VERSION ""

NS_ :

BS_:

BU_: HIB SaGE CBC DASM DIAGNOST EBCM ECM EPSB ESC ESL HALF HCP IC OCM ORC PTS RF_HUB SCCM

BO_ 996 NET_CFG_PT: 8 HIB
 SG_ NET_CFG_STAT_PT : 0|2@1+ (1,0) [0|0] ""  DASM,EBCM,ECM,EPSB,ESC,ESL,HALF,HCP,IC,OCM,ORC,PTS,RF_HUB,SCCM
 SG_ NetCfg_ACC : 2|1@1+ (1,0) [0|0] ""  RF_HUB
 SG_ NetCfg_ADCM : 3|1@1+ (1,0) [0|0] ""  RF_HUB
 SG_ NetCfg_AFLS : 28|1@1+ (1,0) [0|0] ""  RF_HUB
 SG_ NetCfg_AHLM : 4|1@1+ (1,0) [0|0] ""  RF_HUB
 SG_ NetCfg_ANC : 39|1@1+ (1,0) [0|0] ""  RF_HUB
 SG_ NetCfg_ASCM : 6|1@1+ (1,0) [0|0] ""  DASM,HALF,RF_HUB
 SG_ NetCfg_BSMO : 36|1@1+ (1,0) [0|0] ""  EPSB,IC,RF_HUB
 SG_ NetCfg_CBC_PT : 7|1@1+ (1,0) [0|0] ""  EPSB,RF_HUB
 SG_ NetCfg_DASM : 16|1@1+ (1,0) [0|0] ""  DASM,ECM,ESC,IC,RF_HUB,SCCM
 SG_ NetCfg_DTCM : 8|1@1+ (1,0) [0|0] ""  DASM,RF_HUB
 SG_ NetCfg_ECM : 9|1@1+ (1,0) [0|0] ""  DASM,EPSB,RF_HUB
 SG_ NetCfg_ELSD : 24|1@1+ (1,0) [0|0] ""  RF_HUB
 SG_ NetCfg_EPB : 13|1@1+ (1,0) [0|0] ""  RF_HUB
 SG_ NetCfg_EPPM : 18|1@1+ (1,0) [0|0] ""  RF_HUB
 SG_ NetCfg_EPS : 10|1@1+ (1,0) [0|0] ""  HALF,IC,ORC,RF_HUB
 SG_ NetCfg_ESC : 12|1@1+ (1,0) [0|0] ""  EPSB,RF_HUB
 SG_ NetCfg_ESL : 37|1@1+ (1,0) [0|0] ""  RF_HUB
 SG_ NetCfg_ESM : 11|1@1+ (1,0) [0|0] ""  RF_HUB
 SG_ NetCfg_FDCM : 17|1@1+ (1,0) [0|0] ""  RF_HUB
 SG_ NetCfg_HCP : 38|1@1+ (1,0) [0|0] ""  EPSB,PTS,RF_HUB
 SG_ NetCfg_HaLF : 31|1@1+ (1,0) [0|0] ""  DASM,HALF,RF_HUB
 SG_ NetCfg_IC : 15|1@1+ (1,0) [0|0] ""  DASM,EPSB,RF_HUB
 SG_ NetCfg_ITBM : 29|1@1+ (1,0) [0|0] ""  RF_HUB
 SG_ NetCfg_OCM : 30|1@1+ (1,0) [0|0] ""  ORC,RF_HUB
 SG_ NetCfg_ORC : 19|1@1+ (1,0) [0|0] ""  DASM,RF_HUB
 SG_ NetCfg_PASS_PT : 27|1@1+ (1,0) [0|0] ""  RF_HUB
 SG_ NetCfg_PTS : 20|1@1+ (1,0) [0|0] ""  EPSB,ESC,IC,RF_HUB
 SG_ NetCfg_RF_HUB : 14|1@1+ (1,0) [0|0] ""  HCP,IC,RF_HUB
 SG_ NetCfg_RHSC2 : 44|1@1+ (1,0) [0|0] ""  EPSB,HCP,RF_HUB
 SG_ NetCfg_SCCM : 23|1@1+ (1,0) [0|0] ""  DASM,EPSB,RF_HUB
 SG_ NetCfg_TCM : 25|1@1+ (1,0) [0|0] ""  ORC,RF_HUB
 SG_ NetCfg_TPM : 26|1@1+ (1,0) [0|0] ""  IC,RF_HUB
 SG_ NetCfg_VSIM_C : 5|1@1+ (1,0) [0|0] ""  RF_HUB

BO_ 1025 NM_CBC: 8 CBC
 SG_ Awake_Diag_Actv m15 : 33|1@1+ (1,0) [0|0] ""  CBC,EBCM,EPSB,ESC,ESL,HCP,IC,RF_HUB,SCCM
 SG_ Awake_NwSt m15 : 32|1@1+ (1,0) [0|0] ""  CBC,EBCM,EPSB,ESC,ESL,HCP,IC,RF_HUB,SCCM
 SG_ NM_Mode : 0|8@1+ (1,0) [0|0] ""  CBC,EBCM,EPSB,ESC,ESL,HCP,IC,RF_HUB,SCCM
 SG_ NM_Sleep_Ack : 22|1@1+ (1,0) [0|0] ""  CBC,EBCM,EPSB,ESC,ESL,HCP,IC,RF_HUB,SCCM
 SG_ NM_Sleep_Ind : 23|1@1+ (1,0) [0|0] ""  CBC,EBCM,EPSB,ESC,ESL,HCP,IC,RF_HUB,SCCM
 SG_ NM_Successor : 8|8@1+ (1,0) [0|63] ""  CBC,EBCM,EPSB,ESC,ESL,HCP,IC,RF_HUB,SCCM
 SG_ NM_Ud_Launch : 16|6@1+ (1,0) [0|0] ""  CBC,EBCM,EPSB,ESC,ESL,HCP,IC,RF_HUB,SCCM
 SG_ NM_Ud_Srv M : 24|8@1+ (1,0) [0|0] ""  CBC,EBCM,EPSB,ESC,ESL,HCP,IC,RF_HUB,SCCM
 SG_ Nw_Id : 56|8@1+ (1,0) [0|0] ""  CBC,EBCM,EPSB,ESC,ESL,HCP,IC,RF_HUB,SCCM
 SG_ WakeupCnt m2 : 40|8@1+ (1,0) [0|254] ""  CBC,EBCM,EPSB,ESC,ESL,HCP,IC,RF_HUB,SCCM
 SG_ WakeupRsn_CBC m2 : 32|8@1+ (1,0) [0|0] ""  CBC,EBCM,EPSB,ESC,ESL,HCP,IC,RF_HUB,SCCM

BO_ 1083 NM_EBCM: 8 EBCM
 SG_ Awake_Diag_Actv m15 : 33|1@1+ (1,0) [0|0] ""  CBC,EBCM,EPSB,ESC,ESL,HCP,IC,RF_HUB,SCCM
 SG_ Awake_NwSt m15 : 32|1@1+ (1,0) [0|0] ""  CBC,EBCM,EPSB,ESC,ESL,HCP,IC,RF_HUB,SCCM
 SG_ NM_Mode : 0|8@1+ (1,0) [0|0] ""  CBC,EBCM,EPSB,ESC,ESL,HCP,IC,RF_HUB,SCCM
 SG_ NM_Sleep_Ack : 22|1@1+ (1,0) [0|0] ""  CBC,EBCM,EPSB,ESC,ESL,HCP,IC,RF_HUB,SCCM
 SG_ NM_Sleep_Ind : 23|1@1+ (1,0) [0|0] ""  CBC,EBCM,EPSB,ESC,ESL,HCP,IC,RF_HUB,SCCM
 SG_ NM_Successor : 8|8@1+ (1,0) [0|63] ""  CBC,EBCM,EPSB,ESC,ESL,HCP,IC,RF_HUB,SCCM
 SG_ NM_Ud_Launch : 16|6@1+ (1,0) [0|0] ""  CBC,EBCM,EPSB,ESC,ESL,HCP,IC,RF_HUB,SCCM
 SG_ NM_Ud_Srv M : 24|8@1+ (1,0) [0|0] ""  CBC,EBCM,EPSB,ESC,ESL,HCP,IC,RF_HUB,SCCM
 SG_ Nw_Id : 56|8@1+ (1,0) [0|0] ""  CBC,EBCM,EPSB,ESC,ESL,HCP,IC,RF_HUB,SCCM
 SG_ WakeupCnt m2 : 40|8@1+ (1,0) [0|254] ""  CBC,EBCM,EPSB,ESC,ESL,HCP,IC,RF_HUB,SCCM
 SG_ WakeupRsn_EBCM m2 : 32|8@1+ (1,0) [0|0] ""  CBC,EBCM,EPSB,ESC,ESL,HCP,IC,RF_HUB,SCCM

BO_ 1050 NM_EPS: 8 EPSB
 SG_ Awake_Diag_Actv m15 : 33|1@1+ (1,0) [0|0] ""  CBC,EBCM,EPSB,ESC,ESL,HCP,IC,RF_HUB,SCCM
 SG_ Awake_EngRPM_high m15 : 36|1@1+ (1,0) [0|0] ""  CBC,EBCM,EPSB,ESC,ESL,HCP,IC,RF_HUB,SCCM
 SG_ Awake_IgnHigh m15 : 37|1@1+ (1,0) [0|0] ""  CBC,EBCM,EPSB,ESC,ESL,HCP,IC,RF_HUB,SCCM
 SG_ Awake_NwSt m15 : 32|1@1+ (1,0) [0|0] ""  CBC,EBCM,EPSB,ESC,ESL,HCP,IC,RF_HUB,SCCM
 SG_ Awake_Rampout m15 : 34|1@1+ (1,0) [0|0] ""  CBC,EBCM,EPSB,ESC,ESL,HCP,IC,RF_HUB,SCCM
 SG_ Awake_VSS_high m15 : 35|1@1+ (1,0) [0|0] ""  CBC,EBCM,EPSB,ESC,ESL,HCP,IC,RF_HUB,SCCM
 SG_ NM_Mode : 0|8@1+ (1,0) [0|0] ""  CBC,EBCM,EPSB,ESC,ESL,HCP,IC,RF_HUB,SCCM
 SG_ NM_Sleep_Ack : 22|1@1+ (1,0) [0|0] ""  CBC,EBCM,EPSB,ESC,ESL,HCP,IC,RF_HUB,SCCM
 SG_ NM_Sleep_Ind : 23|1@1+ (1,0) [0|0] ""  CBC,EBCM,EPSB,ESC,ESL,HCP,IC,RF_HUB,SCCM
 SG_ NM_Successor : 8|8@1+ (1,0) [0|63] ""  CBC,EBCM,EPSB,ESC,ESL,HCP,IC,RF_HUB,SCCM
 SG_ NM_Ud_Launch : 16|6@1+ (1,0) [0|0] ""  CBC,EBCM,EPSB,ESC,ESL,HCP,IC,RF_HUB,SCCM
 SG_ NM_Ud_Srv M : 24|8@1+ (1,0) [0|0] ""  CBC,EBCM,EPSB,ESC,ESL,HCP,IC,RF_HUB,SCCM
 SG_ Nw_Id : 56|8@1+ (1,0) [0|0] ""  CBC,EBCM,EPSB,ESC,ESL,HCP,IC,RF_HUB,SCCM
 SG_ WakeupCnt m2 : 40|8@1+ (1,0) [0|254] ""  CBC,EBCM,EPSB,ESC,ESL,HCP,IC,RF_HUB,SCCM
 SG_ WakeupRsn_EPS m2 : 32|8@1+ (1,0) [0|0] ""  CBC,EBCM,EPSB,ESC,ESL,HCP,IC,RF_HUB,SCCM

BO_ 1031 NM_ESC: 8 ESC
 SG_ Awake_Brake_Pedal_Pressed m15 : 34|1@1+ (1,0) [0|0] ""  CBC,EBCM,EPSB,ESC,ESL,HCP,IC,RF_HUB,SCCM
 SG_ Awake_Diag_Actv m15 : 33|1@1+ (1,0) [0|0] ""  CBC,EBCM,EPSB,ESC,ESL,HCP,IC,RF_HUB,SCCM
 SG_ Awake_EPB_Switch_Wakeup m15 : 36|1@1+ (1,0) [0|0] ""  CBC,EBCM,EPSB,ESC,ESL,HCP,IC,RF_HUB,SCCM
 SG_ Awake_Hardwire_Ignition m15 : 37|1@1+ (1,0) [0|0] ""  CBC,EBCM,EPSB,ESC,ESL,HCP,IC,RF_HUB,SCCM
 SG_ Awake_NwSt m15 : 32|1@1+ (1,0) [0|0] ""  CBC,EBCM,EPSB,ESC,ESL,HCP,IC,RF_HUB,SCCM
 SG_ Awake_Vehicle_Speed m15 : 35|1@1+ (1,0) [0|0] ""  CBC,EBCM,EPSB,ESC,ESL,HCP,IC,RF_HUB,SCCM
 SG_ NM_Mode : 0|8@1+ (1,0) [0|0] ""  CBC,EBCM,EPSB,ESC,ESL,HCP,IC,RF_HUB,SCCM
 SG_ NM_Sleep_Ack : 22|1@1+ (1,0) [0|0] ""  CBC,EBCM,EPSB,ESC,ESL,HCP,IC,RF_HUB,SCCM
 SG_ NM_Sleep_Ind : 23|1@1+ (1,0) [0|0] ""  CBC,EBCM,EPSB,ESC,ESL,HCP,IC,RF_HUB,SCCM
 SG_ NM_Successor : 8|8@1+ (1,0) [0|63] ""  CBC,EBCM,EPSB,ESC,ESL,HCP,IC,RF_HUB,SCCM
 SG_ NM_Ud_Launch : 16|6@1+ (1,0) [0|0] ""  CBC,EBCM,EPSB,ESC,ESL,HCP,IC,RF_HUB,SCCM
 SG_ NM_Ud_Srv M : 24|8@1+ (1,0) [0|0] ""  CBC,EBCM,EPSB,ESC,ESL,HCP,IC,RF_HUB,SCCM
 SG_ Nw_Id : 56|8@1+ (1,0) [0|0] ""  CBC,EBCM,EPSB,ESC,ESL,HCP,IC,RF_HUB,SCCM
 SG_ WakeupCnt m2 : 40|8@1+ (1,0) [0|254] ""  CBC,EBCM,EPSB,ESC,ESL,HCP,IC,RF_HUB,SCCM
 SG_ WakeupRsn_ESC m2 : 32|8@1+ (1,0) [0|0] ""  CBC,EBCM,EPSB,ESC,ESL,HCP,IC,RF_HUB,SCCM

BO_ 1032 NM_ESL: 8 ESL
 SG_ Awake_Diag_Actv m15 : 33|1@1+ (1,0) [0|0] ""  CBC,EBCM,EPSB,ESC,ESL,HCP,IC,RF_HUB,SCCM
 SG_ Awake_Ign_RunStart m15 : 34|1@1+ (1,0) [0|0] ""  CBC,EBCM,EPSB,ESC,ESL,HCP,IC,RF_HUB,SCCM
 SG_ Awake_Lock_Unlock m15 : 35|1@1+ (1,0) [0|0] ""  CBC,EBCM,EPSB,ESC,ESL,HCP,IC,RF_HUB,SCCM
 SG_ Awake_NwSt m15 : 32|1@1+ (1,0) [0|0] ""  CBC,EBCM,EPSB,ESC,ESL,HCP,IC,RF_HUB,SCCM
 SG_ NM_Mode : 0|8@1+ (1,0) [0|0] ""  CBC,EBCM,EPSB,ESC,ESL,HCP,IC,RF_HUB,SCCM
 SG_ NM_Sleep_Ack : 22|1@1+ (1,0) [0|0] ""  CBC,EBCM,EPSB,ESC,ESL,HCP,IC,RF_HUB,SCCM
 SG_ NM_Sleep_Ind : 23|1@1+ (1,0) [0|0] ""  CBC,EBCM,EPSB,ESC,ESL,HCP,IC,RF_HUB,SCCM
 SG_ NM_Successor : 8|8@1+ (1,0) [0|63] ""  CBC,EBCM,EPSB,ESC,ESL,HCP,IC,RF_HUB,SCCM
 SG_ NM_Ud_Launch : 16|6@1+ (1,0) [0|0] ""  CBC,EBCM,EPSB,ESC,ESL,HCP,IC,RF_HUB,SCCM
 SG_ NM_Ud_Srv M : 24|8@1+ (1,0) [0|0] ""  CBC,EBCM,EPSB,ESC,ESL,HCP,IC,RF_HUB,SCCM
 SG_ Nw_Id : 56|8@1+ (1,0) [0|0] ""  CBC,EBCM,EPSB,ESC,ESL,HCP,IC,RF_HUB,SCCM
 SG_ WakeupCnt m2 : 40|8@1+ (1,0) [0|254] ""  CBC,EBCM,EPSB,ESC,ESL,HCP,IC,RF_HUB,SCCM
 SG_ WakeupRsn_ESL m2 : 32|8@1+ (1,0) [0|0] ""  CBC,EBCM,EPSB,ESC,ESL,HCP,IC,RF_HUB,SCCM

BO_ 1082 NM_HCP: 8 HCP
 SG_ Awake_Chg_ST m15 : 35|1@1+ (1,0) [0|0] ""  CBC,EBCM,EPSB,ESC,ESL,HCP,IC,RF_HUB,SCCM
 SG_ Awake_Diag_Actv m15 : 33|1@1+ (1,0) [0|0] ""  CBC,EBCM,EPSB,ESC,ESL,HCP,IC,RF_HUB,SCCM
 SG_ Awake_NwSt m15 : 32|1@1+ (1,0) [0|0] ""  CBC,EBCM,EPSB,ESC,ESL,HCP,IC,RF_HUB,SCCM
 SG_ Awake_OBCM_WU m15 : 34|1@1+ (1,0) [0|0] ""  CBC,EBCM,EPSB,ESC,ESL,HCP,IC,RF_HUB,SCCM
 SG_ NM_Mode : 0|8@1+ (1,0) [0|0] ""  CBC,EBCM,EPSB,ESC,ESL,HCP,IC,RF_HUB,SCCM
 SG_ NM_Sleep_Ack : 22|1@1+ (1,0) [0|0] ""  CBC,EBCM,EPSB,ESC,ESL,HCP,IC,RF_HUB,SCCM
 SG_ NM_Sleep_Ind : 23|1@1+ (1,0) [0|0] ""  CBC,EBCM,EPSB,ESC,ESL,HCP,IC,RF_HUB,SCCM
 SG_ NM_Successor : 8|8@1+ (1,0) [0|63] ""  CBC,EBCM,EPSB,ESC,ESL,HCP,IC,RF_HUB,SCCM
 SG_ NM_Ud_Launch : 16|6@1+ (1,0) [0|0] ""  CBC,EBCM,EPSB,ESC,ESL,HCP,IC,RF_HUB,SCCM
 SG_ NM_Ud_Srv M : 24|8@1+ (1,0) [0|0] ""  CBC,EBCM,EPSB,ESC,ESL,HCP,IC,RF_HUB,SCCM
 SG_ Nw_Id : 56|8@1+ (1,0) [0|0] ""  CBC,EBCM,EPSB,ESC,ESL,HCP,IC,RF_HUB,SCCM
 SG_ WakeupCnt m2 : 40|8@1+ (1,0) [0|254] ""  CBC,EBCM,EPSB,ESC,ESL,HCP,IC,RF_HUB,SCCM
 SG_ WakeupRsn_HCP m2 : 32|8@1+ (1,0) [0|0] ""  CBC,EBCM,EPSB,ESC,ESL,HCP,IC,RF_HUB,SCCM

BO_ 1026 NM_IC: 8 IC
 SG_ Awake_Diag_Actv m15 : 33|1@1+ (1,0) [0|0] ""  CBC,EBCM,EPSB,ESC,ESL,HCP,IC,RF_HUB,SCCM
 SG_ Awake_NwSt m15 : 32|1@1+ (1,0) [0|0] ""  CBC,EBCM,EPSB,ESC,ESL,HCP,IC,RF_HUB,SCCM
 SG_ NM_Mode : 0|8@1+ (1,0) [0|0] ""  CBC,EBCM,EPSB,ESC,ESL,HCP,IC,RF_HUB,SCCM
 SG_ NM_Sleep_Ack : 22|1@1+ (1,0) [0|0] ""  CBC,EBCM,EPSB,ESC,ESL,HCP,IC,RF_HUB,SCCM
 SG_ NM_Sleep_Ind : 23|1@1+ (1,0) [0|0] ""  CBC,EBCM,EPSB,ESC,ESL,HCP,IC,RF_HUB,SCCM
 SG_ NM_Successor : 8|8@1+ (1,0) [0|63] ""  CBC,EBCM,EPSB,ESC,ESL,HCP,IC,RF_HUB,SCCM
 SG_ NM_Ud_Launch : 16|6@1+ (1,0) [0|0] ""  CBC,EBCM,EPSB,ESC,ESL,HCP,IC,RF_HUB,SCCM
 SG_ NM_Ud_Srv M : 24|8@1+ (1,0) [0|0] ""  CBC,EBCM,EPSB,ESC,ESL,HCP,IC,RF_HUB,SCCM
 SG_ Nw_Id : 56|8@1+ (1,0) [0|0] ""  CBC,EBCM,EPSB,ESC,ESL,HCP,IC,RF_HUB,SCCM
 SG_ WakeupCnt m2 : 40|8@1+ (1,0) [0|254] ""  CBC,EBCM,EPSB,ESC,ESL,HCP,IC,RF_HUB,SCCM
 SG_ WakeupRsn_IC m2 : 32|8@1+ (1,0) [0|0] ""  CBC,EBCM,EPSB,ESC,ESL,HCP,IC,RF_HUB,SCCM

BO_ 1024 NM_RF_HUB: 8 RF_HUB
 SG_ Awake_Diag_Actv m15 : 33|1@1+ (1,0) [0|0] ""  CBC,EBCM,EPSB,ESC,ESL,HCP,IC,RF_HUB,SCCM
 SG_ Awake_NwSt m15 : 32|1@1+ (1,0) [0|0] ""  CBC,EBCM,EPSB,ESC,ESL,HCP,IC,RF_HUB,SCCM
 SG_ NM_Mode : 0|8@1+ (1,0) [0|0] ""  CBC,EBCM,EPSB,ESC,ESL,HCP,IC,RF_HUB,SCCM
 SG_ NM_Sleep_Ack : 22|1@1+ (1,0) [0|0] ""  CBC,EBCM,EPSB,ESC,ESL,HCP,IC,RF_HUB,SCCM
 SG_ NM_Sleep_Ind : 23|1@1+ (1,0) [0|0] ""  CBC,EBCM,EPSB,ESC,ESL,HCP,IC,RF_HUB,SCCM
 SG_ NM_Successor : 8|8@1+ (1,0) [0|63] ""  CBC,EBCM,EPSB,ESC,ESL,HCP,IC,RF_HUB,SCCM
 SG_ NM_Ud_Launch : 16|6@1+ (1,0) [0|0] ""  CBC,EBCM,EPSB,ESC,ESL,HCP,IC,RF_HUB,SCCM
 SG_ NM_Ud_Srv M : 24|8@1+ (1,0) [0|0] ""  CBC,EBCM,EPSB,ESC,ESL,HCP,IC,RF_HUB,SCCM
 SG_ Nw_Id : 56|8@1+ (1,0) [0|0] ""  CBC,EBCM,EPSB,ESC,ESL,HCP,IC,RF_HUB,SCCM
 SG_ WakeupCnt m2 : 40|8@1+ (1,0) [0|254] ""  CBC,EBCM,EPSB,ESC,ESL,HCP,IC,RF_HUB,SCCM
 SG_ WakeupRsn_RF_HUB m2 : 32|8@1+ (1,0) [0|0] ""  CBC,EBCM,EPSB,ESC,ESL,HCP,IC,RF_HUB,SCCM

BO_ 1059 NM_SCCM: 8 SCCM
 SG_ Awake_Diag_Actv m15 : 33|1@1+ (1,0) [0|0] ""  CBC,EBCM,EPSB,ESC,ESL,HCP,IC,RF_HUB,SCCM
 SG_ Awake_EEPROM m15 : 36|1@1+ (1,0) [0|0] ""  CBC,EBCM,EPSB,ESC,ESL,HCP,IC,RF_HUB,SCCM
 SG_ Awake_FTP_Psd m15 : 38|1@1+ (1,0) [0|0] ""  CBC,EBCM,EPSB,ESC,ESL,HCP,IC,RF_HUB,SCCM
 SG_ Awake_HrnSwt_Actv m15 : 39|1@1+ (1,0) [0|0] ""  CBC,EBCM,EPSB,ESC,ESL,HCP,IC,RF_HUB,SCCM
 SG_ Awake_Ignition_On m15 : 35|1@1+ (1,0) [0|0] ""  CBC,EBCM,EPSB,ESC,ESL,HCP,IC,RF_HUB,SCCM
 SG_ Awake_NwSt m15 : 32|1@1+ (1,0) [0|0] ""  CBC,EBCM,EPSB,ESC,ESL,HCP,IC,RF_HUB,SCCM
 SG_ Awake_StwSw_Actv m15 : 34|1@1+ (1,0) [0|0] ""  CBC,EBCM,EPSB,ESC,ESL,HCP,IC,RF_HUB,SCCM
 SG_ Awake_tilt_tel_Psd m15 : 37|1@1+ (1,0) [0|0] ""  CBC,EBCM,EPSB,ESC,ESL,HCP,IC,RF_HUB,SCCM
 SG_ NM_Mode : 0|8@1+ (1,0) [0|0] ""  CBC,EBCM,EPSB,ESC,ESL,HCP,IC,RF_HUB,SCCM
 SG_ NM_Sleep_Ack : 22|1@1+ (1,0) [0|0] ""  CBC,EBCM,EPSB,ESC,ESL,HCP,IC,RF_HUB,SCCM
 SG_ NM_Sleep_Ind : 23|1@1+ (1,0) [0|0] ""  CBC,EBCM,EPSB,ESC,ESL,HCP,IC,RF_HUB,SCCM
 SG_ NM_Successor : 8|8@1+ (1,0) [0|63] ""  CBC,EBCM,EPSB,ESC,ESL,HCP,IC,RF_HUB,SCCM
 SG_ NM_Ud_Launch : 16|6@1+ (1,0) [0|0] ""  CBC,EBCM,EPSB,ESC,ESL,HCP,IC,RF_HUB,SCCM
 SG_ NM_Ud_Srv M : 24|8@1+ (1,0) [0|0] ""  CBC,EBCM,EPSB,ESC,ESL,HCP,IC,RF_HUB,SCCM
 SG_ Nw_Id : 56|8@1+ (1,0) [0|0] ""  CBC,EBCM,EPSB,ESC,ESL,HCP,IC,RF_HUB,SCCM
 SG_ WakeupCnt m2 : 40|8@1+ (1,0) [0|254] ""  CBC,EBCM,EPSB,ESC,ESL,HCP,IC,RF_HUB,SCCM
 SG_ WakeupRsn_SCCM m2 : 32|8@1+ (1,0) [0|0] ""  CBC,EBCM,EPSB,ESC,ESL,HCP,IC,RF_HUB,SCCM

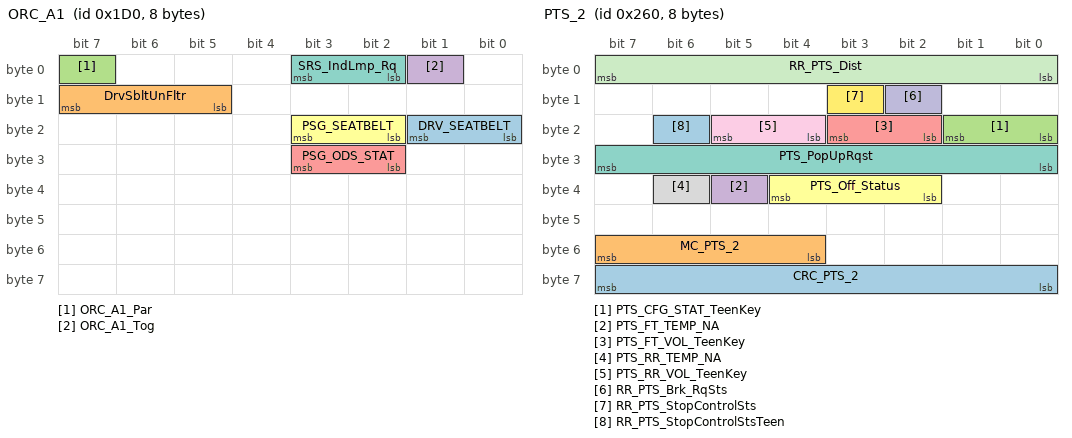
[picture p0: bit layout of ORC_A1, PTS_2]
BO_ 464 ORC_A1: 8 ORC
 SG_ DRV_SEATBELT : 16|2@1+ (1,0) [0|0] ""  DASM,ECM,ESC,HCP,IC
 SG_ DrvSbltUnFltr : 13|3@1+ (1,0) [0|0] ""  ECM,ESC
 SG_ ORC_A1_Par : 7|1@1+ (1,0) [0|0] ""  DASM
 SG_ ORC_A1_Tog : 1|1@1+ (1,0) [0|0] ""  DASM
 SG_ PSG_ODS_STAT : 26|2@1+ (1,0) [0|0] ""  IC
 SG_ PSG_SEATBELT : 18|2@1+ (1,0) [0|0] ""  IC
 SG_ SRS_IndLmp_Rq : 2|2@1+ (1,0) [0|0] ""  IC

BO_ 826 PTS_1: 8 PTS
 SG_ PTS_AlrFC : 40|4@1+ (1,0) [0|0] ""  CBC,IC
 SG_ PTS_AlrFL : 8|4@1+ (1,0) [0|0] ""  CBC,IC
 SG_ PTS_AlrFR : 16|4@1+ (1,0) [0|0] ""  CBC,IC
 SG_ PTS_AlrRC : 48|4@1+ (1,0) [0|0] ""  CBC,IC
 SG_ PTS_AlrRL : 24|4@1+ (1,0) [0|0] ""  CBC,IC
 SG_ PTS_AlrRR : 32|4@1+ (1,0) [0|0] ""  CBC,IC
 SG_ PTS_CFG_STAT : 1|2@1+ (1,0) [0|0] ""  CBC
 SG_ PTS_FT_NA : 3|1@1+ (1,0) [0|0] ""  IC
 SG_ PTS_FT_SRV : 58|1@1+ (1,0) [0|0] ""  IC
 SG_ PTS_GraphicFC : 46|2@1+ (1,0) [0|0] ""  IC
 SG_ PTS_GraphicFL : 14|2@1+ (1,0) [0|0] ""  IC
 SG_ PTS_GraphicFR : 22|2@1+ (1,0) [0|0] ""  IC
 SG_ PTS_GraphicRC : 54|2@1+ (1,0) [0|0] ""  IC
 SG_ PTS_GraphicRL : 30|2@1+ (1,0) [0|0] ""  IC
 SG_ PTS_GraphicRR : 38|2@1+ (1,0) [0|0] ""  IC
 SG_ PTS_RR_NA : 4|1@1+ (1,0) [0|0] ""  IC
 SG_ PTS_RR_SRV : 59|1@1+ (1,0) [0|0] ""  IC
 SG_ PTS_SRV_RQ : 5|1@1+ (1,0) [0|0] ""  IC
 SG_ PTS_STAT : 60|2@1+ (1,0) [0|0] ""  CBC

BO_ 608 PTS_2: 8 PTS
 SG_ CRC_PTS_2 : 56|8@1+ (1,0) [0|0] ""  ESC
 SG_ MC_PTS_2 : 52|4@1+ (1,0) [0|15] ""  ESC
 SG_ PTS_CFG_STAT_TeenKey : 16|2@1+ (1,0) [0|0] ""  CBC
 SG_ PTS_FT_TEMP_NA : 37|1@1+ (1,0) [0|0] ""  IC
 SG_ PTS_FT_VOL_TeenKey : 18|2@1+ (1,0) [0|0] ""  CBC
 SG_ PTS_Off_Status : 34|3@1+ (1,0) [0|0] ""  IC
 SG_ PTS_PopUpRqst : 24|8@1+ (1,0) [0|0] ""  IC
 SG_ PTS_RR_TEMP_NA : 38|1@1+ (1,0) [0|0] ""  IC
 SG_ PTS_RR_VOL_TeenKey : 20|2@1+ (1,0) [0|0] ""  CBC
 SG_ RR_PTS_Brk_RqSts : 10|1@1+ (1,0) [0|0] ""  ESC
 SG_ RR_PTS_Dist : 0|8@1+ (1,0) [0|254] "cm"  ESC
 SG_ RR_PTS_StopControlSts : 11|1@1+ (1,0) [0|0] ""  CBC,IC
 SG_ RR_PTS_StopControlStsTeen : 22|1@1+ (1,0) [0|0] ""  CBC,IC

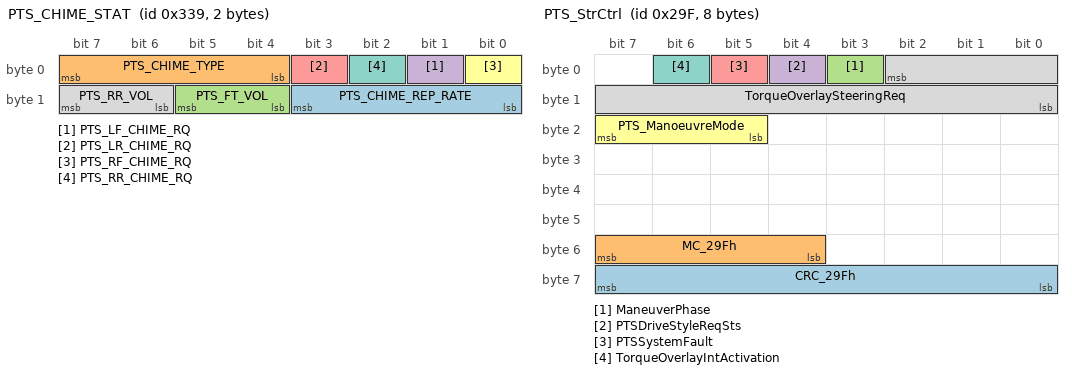
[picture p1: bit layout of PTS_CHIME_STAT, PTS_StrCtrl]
BO_ 825 PTS_CHIME_STAT: 2 PTS
 SG_ PTS_CHIME_REP_RATE : 8|4@1+ (1,0) [0|15] "Hz"  CBC
 SG_ PTS_CHIME_TYPE : 4|4@1+ (1,0) [0|0] ""  CBC
 SG_ PTS_FT_VOL : 12|2@1+ (1,0) [0|0] ""  CBC
 SG_ PTS_LF_CHIME_RQ : 1|1@1+ (1,0) [0|0] ""  CBC
 SG_ PTS_LR_CHIME_RQ : 3|1@1+ (1,0) [0|0] ""  CBC
 SG_ PTS_RF_CHIME_RQ : 0|1@1+ (1,0) [0|0] ""  CBC
 SG_ PTS_RR_CHIME_RQ : 2|1@1+ (1,0) [0|0] ""  CBC
 SG_ PTS_RR_VOL : 14|2@1+ (1,0) [0|0] ""  CBC

BO_ 671 PTS_StrCtrl: 8 PTS
 SG_ CRC_29Fh : 56|8@1+ (1,0) [0|0] ""  EPSB
 SG_ MC_29Fh : 52|4@1+ (1,0) [0|15] ""  EPSB
 SG_ ManeuverPhase : 3|1@1+ (1,0) [0|0] ""  EPSB
 SG_ PTSDriveStyleReqSts : 4|1@1+ (1,0) [0|0] ""  EPSB
 SG_ PTSSystemFault : 5|1@1+ (1,0) [0|0] ""  EPSB
 SG_ PTS_ManoeuvreMode : 21|3@1+ (1,0) [0|0] ""  IC
 SG_ TorqueOverlayIntActivation : 6|1@1+ (1,0) [0|0] ""  EPSB
 SG_ TorqueOverlaySteeringReq : 2|11@0+ (0.0078125,-8) [-8|7.9921875] "Nm"  EPSB

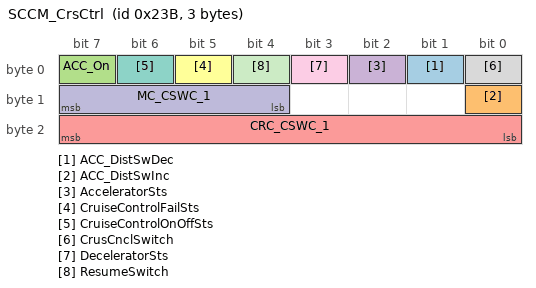
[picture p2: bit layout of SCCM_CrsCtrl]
BO_ 571 SCCM_CrsCtrl: 3 SCCM
 SG_ ACC_DistSwDec : 1|1@1+ (1,0) [0|0] ""  DASM
 SG_ ACC_DistSwInc : 8|1@1+ (1,0) [0|0] ""  DASM
 SG_ ACC_On : 7|1@1+ (1,0) [0|0] ""  DASM,ESC
 SG_ AcceleratorSts : 2|1@1+ (1,0) [0|0] ""  DASM,ECM,ESC
 SG_ CRC_CSWC_1 : 16|8@1+ (1,0) [0|0] ""  ECM
 SG_ CruiseControlFailSts : 5|1@1+ (1,0) [0|0] ""  DASM,ECM,ESC
 SG_ CruiseControlOnOffSts : 6|1@1+ (1,0) [0|0] ""  DASM,ECM,ESC
 SG_ CrusCnclSwitch : 0|1@1+ (1,0) [0|0] ""  DASM,ECM,ESC
 SG_ DeceleratorSts : 3|1@1+ (1,0) [0|0] ""  DASM,ECM,ESC
 SG_ MC_CSWC_1 : 12|4@1+ (1,0) [0|15] ""  ECM
 SG_ ResumeSwitch : 4|1@1+ (1,0) [0|0] ""  DASM,ECM,ESC

CM_ SG_ 996 NET_CFG_STAT_PT "Network configuration status";
CM_ SG_ 996 NetCfg_ACC "Active Cruise Control (1=present)";
CM_ SG_ 996 NetCfg_ADCM "Active Damping Control Module (1=present)";
CM_ SG_ 996 NetCfg_AFLS "Advanced Front Lighting System (1=present)";
CM_ SG_ 996 NetCfg_AHLM "Automatic Headlamp Leveling Module (1=present)";
CM_ SG_ 996 NetCfg_ANC "Active Noise Cancellation (1=present)";
CM_ SG_ 996 NetCfg_ASCM "Air Suspension Control Module (1=present)";
CM_ SG_ 996 NetCfg_BSMO "Brake System Module - OBD (1=present)";
CM_ SG_ 996 NetCfg_CBC_PT "Common Body Controller PT Bus (1=present)";
CM_ SG_ 996 NetCfg_DASM "Driver Assistance System Module (1=present)";
CM_ SG_ 996 NetCfg_DTCM "Drivetrain Control Module (1=present)";
CM_ SG_ 996 NetCfg_ECM "Engine Control Module (1=present)";
CM_ SG_ 996 NetCfg_ELSD "Electric Limited Slip Differential (1=present)";
CM_ SG_ 996 NetCfg_EPB "Electric Park Brake Module (1=present)";
CM_ SG_ 996 NetCfg_EPPM "Elect. Pedestrian protection module (1=present)";
CM_ SG_ 996 NetCfg_EPS "Electric Power Steering (1=present)";
CM_ SG_ 996 NetCfg_ESC "Electronic Stability Module / Anti-Lock Brake (1=present)";
CM_ SG_ 996 NetCfg_ESL "Electric Steering Lock (1=present)";
CM_ SG_ 996 NetCfg_ESM "Electronic Shift Module (1=present)";
CM_ SG_ 996 NetCfg_FDCM "Final Drive Control Module (1=present)";
CM_ SG_ 996 NetCfg_HCP "Hybrid Control Processor (1=present)";
CM_ SG_ 996 NetCfg_HaLF "Haptic Lane Feedback module (1=present)";
CM_ SG_ 996 NetCfg_IC "Instrument Cluster (1=present)";
CM_ SG_ 996 NetCfg_ITBM "Integrated Trailer Brake Module (1=present)";
CM_ SG_ 996 NetCfg_OCM "Occupant Classification Module (1=present)";
CM_ SG_ 996 NetCfg_ORC "Occupant Restraint Controller (1=present)";
CM_ SG_ 996 NetCfg_PASS_PT "Personal Assistant Safety System Module PT Bus (1=present)";
CM_ SG_ 996 NetCfg_PTS "Parktronics System (1=present)";
CM_ SG_ 996 NetCfg_RF_HUB "RF Hub Node (1=present)";
CM_ SG_ 996 NetCfg_RHSC2 "RHSC2 module (1=present)";
CM_ SG_ 996 NetCfg_SCCM "Steering Column Control Module (1=present)";
CM_ SG_ 996 NetCfg_TCM "Automatic Transmission Controller (1=present)";
CM_ SG_ 996 NetCfg_TPM "Tire Pressure Monitor (1=present)";
CM_ SG_ 996 NetCfg_VSIM_C "Vehicle System Interface Module (1=present)";
CM_ SG_ 1025 Awake_Diag_Actv "Stay awake for diagnostics active; True = [1]";
CM_ SG_ 1025 Awake_NwSt "Stay awake for network startup; True = [1]";
CM_ SG_ 1025 NM_Mode "Network management mode";
CM_ SG_ 1025 NM_Sleep_Ack "Network management sleep acknowledge; True = [1]";
CM_ SG_ 1025 NM_Sleep_Ind "Network management sleep indication; True = [1]";
CM_ SG_ 1025 NM_Successor "Network management logical successor";
CM_ SG_ 1025 NM_Ud_Launch "Network management userdata launch type";
CM_ SG_ 1025 NM_Ud_Srv "Network management userdata service no.";
CM_ SG_ 1025 Nw_Id "Network identification no.";
CM_ SG_ 1025 WakeupCnt "Counter for module wakeup states during network sleep";
CM_ SG_ 1025 WakeupRsn_CBC "Wakeup reason CBC";
CM_ SG_ 1083 Awake_Diag_Actv "Stay awake for diagnostics active; True = [1]";
CM_ SG_ 1083 Awake_NwSt "Stay awake for network startup; True = [1]";
CM_ SG_ 1083 NM_Mode "Network management mode";
CM_ SG_ 1083 NM_Sleep_Ack "Network management sleep acknowledge; True = [1]";
CM_ SG_ 1083 NM_Sleep_Ind "Network management sleep indication; True = [1]";
CM_ SG_ 1083 NM_Successor "Network management logical successor";
CM_ SG_ 1083 NM_Ud_Launch "Network management userdata launch type";
CM_ SG_ 1083 NM_Ud_Srv "Network management userdata service no.";
CM_ SG_ 1083 Nw_Id "Network identification no.";
CM_ SG_ 1083 WakeupCnt "Counter for module wakeup states during network sleep";
CM_ SG_ 1083 WakeupRsn_EBCM "Wakeup reason EBCM";
CM_ SG_ 1050 Awake_Diag_Actv "Stay awake for diagnostics active; True = [1]";
CM_ SG_ 1050 Awake_EngRPM_high "Stay awake - assist active due to engine RPM high; True = 1";
CM_ SG_ 1050 Awake_IgnHigh "Stay awake - ignition high; True = 1";
CM_ SG_ 1050 Awake_NwSt "Stay awake for network startup; True = [1]";
CM_ SG_ 1050 Awake_Rampout "Stay awake - ramping assist off; True = 1";
CM_ SG_ 1050 Awake_VSS_high "Stay awake - assist active due to vehicle speed high; True = 1";
CM_ SG_ 1050 NM_Mode "Network management mode";
CM_ SG_ 1050 NM_Sleep_Ack "Network management sleep acknowledge; True = [1]";
CM_ SG_ 1050 NM_Sleep_Ind "Network management sleep indication; True = [1]";
CM_ SG_ 1050 NM_Successor "Network management logical successor";
CM_ SG_ 1050 NM_Ud_Launch "Network management userdata launch type";
CM_ SG_ 1050 NM_Ud_Srv "Network management userdata service no.";
CM_ SG_ 1050 Nw_Id "Network identification no.";
CM_ SG_ 1050 WakeupCnt "Counter for module wakeup states during network sleep";
CM_ SG_ 1050 WakeupRsn_EPS "Wakeup reason EPS";
CM_ SG_ 1031 Awake_Brake_Pedal_Pressed "Stay awake for brake pedal pressed; True = [1]";
CM_ SG_ 1031 Awake_Diag_Actv "Stay awake for diagnostics active; True = [1]";
CM_ SG_ 1031 Awake_EPB_Switch_Wakeup "Stay awake for EPB switch actuation; True = [1]";
CM_ SG_ 1031 Awake_Hardwire_Ignition "Stay awake for ignition on; True = [1]";
CM_ SG_ 1031 Awake_NwSt "Stay awake for network startup; True = [1]";
CM_ SG_ 1031 Awake_Vehicle_Speed "Stay awake for vehicle speed; True = [1]";
CM_ SG_ 1031 NM_Mode "Network management mode";
CM_ SG_ 1031 NM_Sleep_Ack "Network management sleep acknowledge; True = [1]";
CM_ SG_ 1031 NM_Sleep_Ind "Network management sleep indication; True = [1]";
CM_ SG_ 1031 NM_Successor "Network management logical successor";
CM_ SG_ 1031 NM_Ud_Launch "Network management userdata launch type";
CM_ SG_ 1031 NM_Ud_Srv "Network management userdata service no.";
CM_ SG_ 1031 Nw_Id "Network identification no.";
CM_ SG_ 1031 WakeupCnt "Counter for module wakeup states during network sleep";
CM_ SG_ 1031 WakeupRsn_ESC "Wakeup reason ESC";
CM_ SG_ 1032 Awake_Diag_Actv "Stay awake for diagnostics active; True = [1]";
CM_ SG_ 1032 Awake_Ign_RunStart "Stay awake for the ignition is either Run or start; True = [1]";
CM_ SG_ 1032 Awake_Lock_Unlock "ESL is performing lock/unlock operation; True = [1]";
CM_ SG_ 1032 Awake_NwSt "Stay awake for network startup; True = [1]";
CM_ SG_ 1032 NM_Mode "Network management mode";
CM_ SG_ 1032 NM_Sleep_Ack "Network management sleep acknowledge; True = [1]";
CM_ SG_ 1032 NM_Sleep_Ind "Network management sleep indication; True = [1]";
CM_ SG_ 1032 NM_Successor "Network management logical successor";
CM_ SG_ 1032 NM_Ud_Launch "Network management userdata launch type";
CM_ SG_ 1032 NM_Ud_Srv "Network management userdata service no.";
CM_ SG_ 1032 Nw_Id "Network identification no.";
CM_ SG_ 1032 WakeupCnt "Counter for module wakeup states during network sleep";
CM_ SG_ 1032 WakeupRsn_ESL "Wakeup reason ESL";
CM_ SG_ 1082 Awake_Chg_ST "Stay awake for charging status indiaction; True = [1]";
CM_ SG_ 1082 Awake_Diag_Actv "Stay awake for diagnostics active; True = [1]";
CM_ SG_ 1082 Awake_NwSt "Stay awake for network startup; True = [1]";
CM_ SG_ 1082 Awake_OBCM_WU "Stay awake for OBCM wakeup; True = [1]";
CM_ SG_ 1082 NM_Mode "Network management mode";
CM_ SG_ 1082 NM_Sleep_Ack "Network management sleep acknowledge; True = [1]";
CM_ SG_ 1082 NM_Sleep_Ind "Network management sleep indication; True = [1]";
CM_ SG_ 1082 NM_Successor "Network management logical successor";
CM_ SG_ 1082 NM_Ud_Launch "Network management userdata launch type";
CM_ SG_ 1082 NM_Ud_Srv "Network management userdata service no.";
CM_ SG_ 1082 Nw_Id "Network identification no.";
CM_ SG_ 1082 WakeupCnt "Counter for module wakeup states during network sleep";
CM_ SG_ 1082 WakeupRsn_HCP "Wakeup reason HCP";
CM_ SG_ 1026 Awake_Diag_Actv "Stay awake for diagnostics active; True = [1]";
CM_ SG_ 1026 Awake_NwSt "Stay awake for network startup; True = [1]";
CM_ SG_ 1026 NM_Mode "Network management mode";
CM_ SG_ 1026 NM_Sleep_Ack "Network management sleep acknowledge; True = [1]";
CM_ SG_ 1026 NM_Sleep_Ind "Network management sleep indication; True = [1]";
CM_ SG_ 1026 NM_Successor "Network management logical successor";
CM_ SG_ 1026 NM_Ud_Launch "Network management userdata launch type";
CM_ SG_ 1026 NM_Ud_Srv "Network management userdata service no.";
CM_ SG_ 1026 Nw_Id "Network identification no.";
CM_ SG_ 1026 WakeupCnt "Counter for module wakeup states during network sleep";
CM_ SG_ 1026 WakeupRsn_IC "Wakeup reason IC";
CM_ SG_ 1024 Awake_Diag_Actv "Stay awake for diagnostics active; True = [1]";
CM_ SG_ 1024 Awake_NwSt "Stay awake for network startup; True = [1]";
CM_ SG_ 1024 NM_Mode "Network management mode";
CM_ SG_ 1024 NM_Sleep_Ack "Network management sleep acknowledge; True = [1]";
CM_ SG_ 1024 NM_Sleep_Ind "Network management sleep indication; True = [1]";
CM_ SG_ 1024 NM_Successor "Network management logical successor";
CM_ SG_ 1024 NM_Ud_Launch "Network management userdata launch type";
CM_ SG_ 1024 NM_Ud_Srv "Network management userdata service no.";
CM_ SG_ 1024 Nw_Id "Network identification no.";
CM_ SG_ 1024 WakeupCnt "Counter for module wakeup states during network sleep";
CM_ SG_ 1024 WakeupRsn_RF_HUB "Wakeup reason RF_HUB";
CM_ SG_ 1059 Awake_Diag_Actv "Stay awake for diagnostics active; True = [1]";
CM_ SG_ 1059 Awake_EEPROM "Stay awake for EEPROM write access; True = [1]";
CM_ SG_ 1059 Awake_FTP_Psd "Stay awake for flash to pass lever actuated; True = [1]";
CM_ SG_ 1059 Awake_HrnSwt_Actv "Stay awake for  horn switch active; True = [1]";
CM_ SG_ 1059 Awake_Ignition_On "Stay awake for ignition on; True = [1]";
CM_ SG_ 1059 Awake_NwSt "Stay awake for network startup; True = [1]";
CM_ SG_ 1059 Awake_StwSw_Actv "Stay awake for steering wheel switches active; True = [1]";
CM_ SG_ 1059 Awake_tilt_tel_Psd "Stay awake for tilt/telescope switch actuated; True = [1]";
CM_ SG_ 1059 NM_Mode "Network management mode";
CM_ SG_ 1059 NM_Sleep_Ack "Network management sleep acknowledge; True = [1]";
CM_ SG_ 1059 NM_Sleep_Ind "Network management sleep indication; True = [1]";
CM_ SG_ 1059 NM_Successor "Network management logical successor";
CM_ SG_ 1059 NM_Ud_Launch "Network management userdata launch type";
CM_ SG_ 1059 NM_Ud_Srv "Network management userdata service no.";
CM_ SG_ 1059 Nw_Id "Network identification no.";
CM_ SG_ 1059 WakeupCnt "Counter for module wakeup states during network sleep";
CM_ SG_ 1059 WakeupRsn_SCCM "Wakeup reason SCCM";
CM_ SG_ 464 DRV_SEATBELT "Drivers seat belt status";
CM_ SG_ 464 DrvSbltUnFltr "Drivers seat belt fault status - unfiltered";
CM_ SG_ 464 ORC_A1_Par "ORC_A1 even parity bit";
CM_ SG_ 464 ORC_A1_Tog "ORC_A1 toggle bit";
CM_ SG_ 464 PSG_ODS_STAT "Passenger Occupant Detection Sensor Status";
CM_ SG_ 464 PSG_SEATBELT "Passengers seat belt status";
CM_ SG_ 464 SRS_IndLmp_Rq "SRS indication lamp request";
CM_ SG_ 826 PTS_AlrFC "PTS alert front center";
CM_ SG_ 826 PTS_AlrFL "PTS alert front left";
CM_ SG_ 826 PTS_AlrFR "PTS alert front right";
CM_ SG_ 826 PTS_AlrRC "PTS alert rear center";
CM_ SG_ 826 PTS_AlrRL "PTS alert rear left";
CM_ SG_ 826 PTS_AlrRR "PTS alert rear right";
CM_ SG_ 826 PTS_CFG_STAT "Park assist configuration status";
CM_ SG_ 826 PTS_FT_NA "Front park assist not available - blinded sensor; True = [1]";
CM_ SG_ 826 PTS_FT_SRV "Front PTS sensor service request; True = [1]";
CM_ SG_ 826 PTS_GraphicFC "PTS graphic flash rate front center";
CM_ SG_ 826 PTS_GraphicFL "PTS graphic flash rate front left";
CM_ SG_ 826 PTS_GraphicFR "PTS graphic flash rate front right";
CM_ SG_ 826 PTS_GraphicRC "PTS graphic flash rate rear center";
CM_ SG_ 826 PTS_GraphicRL "PTS graphic flash rate rear left";
CM_ SG_ 826 PTS_GraphicRR "PTS graphic flash rate rear right";
CM_ SG_ 826 PTS_RR_NA "Rear park assist not available - blinded sensor; True = [1]";
CM_ SG_ 826 PTS_RR_SRV "Rear PTS sensor service request; True = [1]";
CM_ SG_ 826 PTS_SRV_RQ "PTS service warning request; True = [1]";
CM_ SG_ 826 PTS_STAT "Park Assist System - LED control status";
CM_ SG_ 608 CRC_PTS_2 "CRC-checksum byte 1 to 7 according to SAE J1850";
CM_ SG_ 608 MC_PTS_2 "Message counter";
CM_ SG_ 608 PTS_CFG_STAT_TeenKey "Park assist configuration status for teen key";
CM_ SG_ 608 PTS_FT_TEMP_NA "ParkSense front system temporarily not available; True = [1]";
CM_ SG_ 608 PTS_FT_VOL_TeenKey "PTS Front Volume Setting for teen key";
CM_ SG_ 608 PTS_Off_Status "ParkSense system on/off status indication";
CM_ SG_ 608 PTS_PopUpRqst "ParkSense HMI pop-up message request";
CM_ SG_ 608 PTS_RR_TEMP_NA "ParkSense rear system temporarily not available; True = [1]";
CM_ SG_ 608 PTS_RR_VOL_TeenKey "PTS Rear Volume Setting for teen key";
CM_ SG_ 608 RR_PTS_Brk_RqSts "PTS rear brake request flag; True = [1]";
CM_ SG_ 608 RR_PTS_Dist "Rear distance to nearest obstacle";
CM_ SG_ 608 RR_PTS_StopControlSts "PTS rear park stop control status; Enabled = [1]";
CM_ SG_ 608 RR_PTS_StopControlStsTeen "PTS rear park stop control status for teen key; Enabled = [1]";
CM_ SG_ 825 PTS_CHIME_REP_RATE "PTS chime repetition rate";
CM_ SG_ 825 PTS_CHIME_TYPE "PTS chime type";
CM_ SG_ 825 PTS_FT_VOL "PTS Front Volume Setting";
CM_ SG_ 825 PTS_LF_CHIME_RQ "PTS left front chime on request; True = [1]";
CM_ SG_ 825 PTS_LR_CHIME_RQ "PTS left rear chime on request; True = [1]";
CM_ SG_ 825 PTS_RF_CHIME_RQ "PTS right front chime on request; True = [1]";
CM_ SG_ 825 PTS_RR_CHIME_RQ "PTS right rear chime on request; True = [1]";
CM_ SG_ 825 PTS_RR_VOL "PTS Rear Volume Setting";
CM_ SG_ 671 CRC_29Fh "CRC-checksum byte 1 to 7 according to SAE J1850";
CM_ SG_ 671 MC_29Fh "Message counter";
CM_ SG_ 671 ManeuverPhase "Movement direction estimated by PTS; Forward = [1]";
CM_ SG_ 671 PTSDriveStyleReqSts "PTS drive style request status; Active = [1]";
CM_ SG_ 671 PTSSystemFault "PTS system fault; True = [1]";
CM_ SG_ 671 PTS_ManoeuvreMode "Parking maneuver mode status of the PTS";
CM_ SG_ 671 TorqueOverlayIntActivation "Torques overlay interface activiation request; Active = [1]";
CM_ SG_ 671 TorqueOverlaySteeringReq "Torque requested by the PTS torque overlay";
CM_ SG_ 571 ACC_DistSwDec "Cruise Switch: Distance Decrease pressed";
CM_ SG_ 571 ACC_DistSwInc "Cruise Switch: Distance Increase pressed";
CM_ SG_ 571 ACC_On "Cruise Switch: ACC or ESC mode pressed";
CM_ SG_ 571 AcceleratorSts "Cruise Switch: Set/Accel Pressed";
CM_ SG_ 571 CRC_CSWC_1 "CRC-checksum byte 1 to 2 according to SAE J1850";
CM_ SG_ 571 CruiseControlFailSts "Cruise Switch: Implausible State=1";
CM_ SG_ 571 CruiseControlOnOffSts "Cruise Switch: On/Off  Pressed";
CM_ SG_ 571 CrusCnclSwitch "Cruise Switch: Cancel Pressed";
CM_ SG_ 571 DeceleratorSts "Cruise Switch: Coast or Set/Decel Pressed";
CM_ SG_ 571 MC_CSWC_1 "Message counter";
CM_ SG_ 571 ResumeSwitch "Cruise Switch: Resume Pressed";
BA_DEF_ BO_  "App-Botschaft" ENUM  "nein","ja";
BA_DEF_ BO_  "CanMsgMinLen" INT 0 8;
BA_DEF_ BO_  "DiagRequest" ENUM  "nein","ja";
BA_DEF_ BO_  "DiagResponse" ENUM  "nein","ja";
BA_DEF_ BO_  "DiagState" ENUM  "nein","ja";
BA_DEF_ BO_  "GenMsgCycleTime" INT 0 65535;
BA_DEF_ BO_  "GenMsgCycleTimeActive" INT 0 65535;
BA_DEF_ BO_  "GenMsgDelayTime" INT 0 65535;
BA_DEF_ BO_  "GenMsgNrOfRepetitions" INT 0 65535;
BA_DEF_ BO_  "GenMsgSendType" ENUM  "cyclicX","spontanX","cyclicIfActiveX","spontanWithDelay","cyclicAndSpontanX","cyclicAndSpontanWithDelay","spontanWithRepitition","cyclicIfActiveAndSpontanWD","cyclicIfActiveFast","cyclicWithRepeatOnDemand","none";
BA_DEF_ BO_  "GenMsgStartDelayTime" INT 0 65535;
BA_DEF_ BO_  "GenMsgStartValue" STRING ;
BA_DEF_ BO_  "NWM-Botschaft" ENUM  "nein","ja";
BA_DEF_ BO_  "TpTxIndex" INT 0 99;
BA_DEF_ SG_  "FlexKomComment" STRING ;
BA_DEF_ SG_  "FlexKomIsMotorola" ENUM  "nein","ja";
BA_DEF_ SG_  "FlexKomSID" INT 0 2147483647;
BA_DEF_ SG_  "FlexKomSigLaenge" INT 0 64;
BA_DEF_ SG_  "FlexKomSigName" STRING ;
BA_DEF_ SG_  "FlexKomSigStartPos" INT 0 63;
BA_DEF_ SG_  "FlexKomSigStartValue" STRING ;
BA_DEF_ SG_  "GenSigCycleTime" INT 0 65535;
BA_DEF_ SG_  "GenSigCycleTimeActive" INT 0 65535;
BA_DEF_ SG_  "GenSigSendType" ENUM  "cyclicX","spontanX","cyclicIfActiveX","spontanWithDelay","cyclicAndSpontanX","cyclicAndSpontanWithDelay","spontanWithRepitition","cyclicIfActiveAndSpontanWD","cyclicIfActiveFast","cyclicWithRepeatOnDemand","none";
BA_DEF_ SG_  "GenSigSNA" STRING ;
BA_DEF_ SG_  "GenSigStartValue" HEX 0 2147483648;
BA_DEF_ SG_  "GenSigTimeout_CBC" INT 0 65535;
BA_DEF_ SG_  "GenSigTimeout_EPS" INT 0 65535;
BA_DEF_ SG_  "GenSigTimeout_ESC" INT 0 65535;
BA_DEF_ SG_  "GenSigTimeout_ESL" INT 0 65535;
BA_DEF_ SG_  "GenSigTimeout_RHSC2" INT 0 65535;
BA_DEF_ SG_  "GenSigTimeout_ETM" INT 0 65535;
BA_DEF_ SG_  "GenSigTimeout_HaLF" INT 0 65535;
BA_DEF_ SG_  "GenSigTimeout_IC" INT 0 65535;
BA_DEF_ SG_  "GenSigTimeout_OCM" INT 0 65535;
BA_DEF_ SG_  "GenSigTimeout_ORC" INT 0 65535;
BA_DEF_ SG_  "GenSigTimeout_PTS" INT 0 65535;
BA_DEF_ SG_  "GenSigTimeout_RF_HUB" INT 0 65535;
BA_DEF_ SG_  "GenSigTimeout_SCCM" INT 0 65535;
BA_DEF_ SG_  "RID" STRING ;
BA_DEF_DEF_  "App-Botschaft" "nein";
BA_DEF_DEF_  "CanMsgMinLen" 0;
BA_DEF_DEF_  "DiagRequest" "nein";
BA_DEF_DEF_  "DiagResponse" "nein";
BA_DEF_DEF_  "DiagState" "nein";
BA_DEF_DEF_  "GenMsgCycleTime" 0;
BA_DEF_DEF_  "GenMsgCycleTimeActive" 0;
BA_DEF_DEF_  "GenMsgDelayTime" 0;
BA_DEF_DEF_  "GenMsgNrOfRepetitions" 0;
BA_DEF_DEF_  "GenMsgSendType" "cyclicX";
BA_DEF_DEF_  "GenMsgStartDelayTime" 0;
BA_DEF_DEF_  "GenMsgStartValue" "";
BA_DEF_DEF_  "NWM-Botschaft" "nein";
BA_DEF_DEF_  "TpTxIndex" 0;
BA_DEF_DEF_  "FlexKomComment" "";
BA_DEF_DEF_  "FlexKomIsMotorola" "nein";
BA_DEF_DEF_  "FlexKomSID" 0;
BA_DEF_DEF_  "FlexKomSigLaenge" 0;
BA_DEF_DEF_  "FlexKomSigName" "";
BA_DEF_DEF_  "FlexKomSigStartPos" 0;
BA_DEF_DEF_  "FlexKomSigStartValue" "";
BA_DEF_DEF_  "GenSigCycleTime" 0;
BA_DEF_DEF_  "GenSigCycleTimeActive" 0;
BA_DEF_DEF_  "GenSigSendType" "cyclicX";
BA_DEF_DEF_  "GenSigSNA" "";
BA_DEF_DEF_  "GenSigStartValue" 0;
BA_DEF_DEF_  "GenSigTimeout_CBC" 0;
BA_DEF_DEF_  "GenSigTimeout_EPS" 0;
BA_DEF_DEF_  "GenSigTimeout_ESC" 0;
BA_DEF_DEF_  "GenSigTimeout_ESL" 0;
BA_DEF_DEF_  "GenSigTimeout_RHSC2" 0;
BA_DEF_DEF_  "GenSigTimeout_ETM" 0;
BA_DEF_DEF_  "GenSigTimeout_HaLF" 0;
BA_DEF_DEF_  "GenSigTimeout_IC" 0;
BA_DEF_DEF_  "GenSigTimeout_OCM" 0;
BA_DEF_DEF_  "GenSigTimeout_ORC" 0;
BA_DEF_DEF_  "GenSigTimeout_PTS" 0;
BA_DEF_DEF_  "GenSigTimeout_RF_HUB" 0;
BA_DEF_DEF_  "GenSigTimeout_SCCM" 0;
BA_DEF_DEF_  "RID" "";
BA_ "GenMsgCycleTime" BO_ 996 2000;
BA_ "GenMsgDelayTime" BO_ 996 20;
BA_ "GenMsgNrOfRepetitions" BO_ 996 2;
BA_ "GenMsgSendType" BO_ 996 5;
BA_ "GenMsgStartDelayTime" BO_ 996 10;
BA_ "GenMsgStartValue" BO_ 996 "0300000000000000h";
BA_ "GenMsgDelayTime" BO_ 1025 20;
BA_ "GenMsgNrOfRepetitions" BO_ 1025 2;
BA_ "GenMsgSendType" BO_ 1025 1;
BA_ "GenMsgStartValue" BO_ 1025 "FFFFFFFF000000FFh";
BA_ "NWM-Botschaft" BO_ 1025 1;
BA_ "GenMsgDelayTime" BO_ 1083 20;
BA_ "GenMsgNrOfRepetitions" BO_ 1083 2;
BA_ "GenMsgSendType" BO_ 1083 1;
BA_ "GenMsgStartValue" BO_ 1083 "FFFFFFFF000000FFh";
BA_ "NWM-Botschaft" BO_ 1083 1;
BA_ "GenMsgDelayTime" BO_ 1050 20;
BA_ "GenMsgNrOfRepetitions" BO_ 1050 2;
BA_ "GenMsgSendType" BO_ 1050 1;
BA_ "GenMsgStartValue" BO_ 1050 "FFFFFFFF000000FFh";
BA_ "NWM-Botschaft" BO_ 1050 1;
BA_ "GenMsgDelayTime" BO_ 1031 20;
BA_ "GenMsgNrOfRepetitions" BO_ 1031 2;
BA_ "GenMsgSendType" BO_ 1031 1;
BA_ "GenMsgStartValue" BO_ 1031 "FFFFFFFF000000FFh";
BA_ "NWM-Botschaft" BO_ 1031 1;
BA_ "GenMsgDelayTime" BO_ 1032 20;
BA_ "GenMsgNrOfRepetitions" BO_ 1032 2;
BA_ "GenMsgSendType" BO_ 1032 1;
BA_ "GenMsgStartValue" BO_ 1032 "FFFFFFFF000000FFh";
BA_ "NWM-Botschaft" BO_ 1032 1;
BA_ "GenMsgDelayTime" BO_ 1082 20;
BA_ "GenMsgNrOfRepetitions" BO_ 1082 2;
BA_ "GenMsgSendType" BO_ 1082 1;
BA_ "GenMsgStartValue" BO_ 1082 "FFFFFFFF000000FFh";
BA_ "NWM-Botschaft" BO_ 1082 1;
BA_ "GenMsgDelayTime" BO_ 1026 20;
BA_ "GenMsgNrOfRepetitions" BO_ 1026 2;
BA_ "GenMsgSendType" BO_ 1026 1;
BA_ "GenMsgStartValue" BO_ 1026 "FFFFFFFF000000FFh";
BA_ "NWM-Botschaft" BO_ 1026 1;
BA_ "GenMsgDelayTime" BO_ 1024 20;
BA_ "GenMsgNrOfRepetitions" BO_ 1024 2;
BA_ "GenMsgSendType" BO_ 1024 1;
BA_ "GenMsgStartValue" BO_ 1024 "FFFFFFFF000000FFh";
BA_ "NWM-Botschaft" BO_ 1024 1;
BA_ "GenMsgDelayTime" BO_ 1059 20;
BA_ "GenMsgNrOfRepetitions" BO_ 1059 2;
BA_ "GenMsgSendType" BO_ 1059 1;
BA_ "GenMsgStartValue" BO_ 1059 "FFFFFFFF000000FFh";
BA_ "NWM-Botschaft" BO_ 1059 1;
BA_ "GenMsgCycleTime" BO_ 464 1000;
BA_ "GenMsgDelayTime" BO_ 464 20;
BA_ "GenMsgNrOfRepetitions" BO_ 464 2;
BA_ "GenMsgSendType" BO_ 464 5;
BA_ "GenMsgStartValue" BO_ 464 "44E70F0F00070000h";
BA_ "GenMsgCycleTime" BO_ 826 500;
BA_ "GenMsgDelayTime" BO_ 826 20;
BA_ "GenMsgNrOfRepetitions" BO_ 826 2;
BA_ "GenMsgSendType" BO_ 826 5;
BA_ "GenMsgStartValue" BO_ 826 "00F0F0F0F0F0F000h";
BA_ "GenMsgCycleTime" BO_ 608 500;
BA_ "GenMsgDelayTime" BO_ 608 20;
BA_ "GenMsgNrOfRepetitions" BO_ 608 2;
BA_ "GenMsgSendType" BO_ 608 5;
BA_ "GenMsgStartValue" BO_ 608 "FF001400000000FFh";
BA_ "GenMsgCycleTime" BO_ 825 500;
BA_ "GenMsgDelayTime" BO_ 825 20;
BA_ "GenMsgNrOfRepetitions" BO_ 825 2;
BA_ "GenMsgSendType" BO_ 825 5;
BA_ "GenMsgStartValue" BO_ 825 "0050h";
BA_ "GenMsgCycleTime" BO_ 671 20;
BA_ "GenMsgDelayTime" BO_ 671 20;
BA_ "GenMsgNrOfRepetitions" BO_ 671 2;
BA_ "GenMsgStartValue" BO_ 671 "04000000000000FFh";
BA_ "GenMsgDelayTime" BO_ 571 20;
BA_ "GenMsgNrOfRepetitions" BO_ 571 2;
BA_ "GenMsgSendType" BO_ 571 1;
BA_ "GenMsgStartValue" BO_ 571 "0000FFh";
BA_ "FlexKomComment" SG_ 996 NET_CFG_STAT_PT "Network ECU config data for Powertrain";
BA_ "FlexKomIsMotorola" SG_ 996 NET_CFG_STAT_PT 1;
BA_ "FlexKomSID" SG_ 996 NET_CFG_STAT_PT 39;
BA_ "FlexKomSigLaenge" SG_ 996 NET_CFG_STAT_PT 64;
BA_ "FlexKomSigName" SG_ 996 NET_CFG_STAT_PT "NET_CFG_DATA_PT";
BA_ "FlexKomSigStartPos" SG_ 996 NET_CFG_STAT_PT 7;
BA_ "FlexKomSigStartValue" SG_ 996 NET_CFG_STAT_PT "0300000000000000h";
BA_ "GenSigCycleTime" SG_ 996 NET_CFG_STAT_PT 2000;
BA_ "GenSigSendType" SG_ 996 NET_CFG_STAT_PT 5;
BA_ "GenSigSNA" SG_ 996 NET_CFG_STAT_PT "3h";
BA_ "GenSigStartValue" SG_ 996 NET_CFG_STAT_PT 3;
BA_ "GenSigTimeout_EPS" SG_ 996 NET_CFG_STAT_PT 21000;
BA_ "GenSigTimeout_RHSC2" SG_ 996 NET_CFG_STAT_PT 21000;
BA_ "GenSigTimeout_IC" SG_ 996 NET_CFG_STAT_PT 21000;
BA_ "GenSigTimeout_OCM" SG_ 996 NET_CFG_STAT_PT 21000;
BA_ "GenSigTimeout_ORC" SG_ 996 NET_CFG_STAT_PT 7000;
BA_ "RID" SG_ 996 NET_CFG_STAT_PT "9993";
BA_ "FlexKomComment" SG_ 996 NetCfg_ACC "Network ECU config data for Powertrain";
BA_ "FlexKomIsMotorola" SG_ 996 NetCfg_ACC 1;
BA_ "FlexKomSID" SG_ 996 NetCfg_ACC 39;
BA_ "FlexKomSigLaenge" SG_ 996 NetCfg_ACC 64;
BA_ "FlexKomSigName" SG_ 996 NetCfg_ACC "NET_CFG_DATA_PT";
BA_ "FlexKomSigStartPos" SG_ 996 NetCfg_ACC 7;
BA_ "FlexKomSigStartValue" SG_ 996 NetCfg_ACC "0300000000000000h";
BA_ "GenSigCycleTime" SG_ 996 NetCfg_ACC 2000;
BA_ "GenSigSendType" SG_ 996 NetCfg_ACC 5;
BA_ "GenSigSNA" SG_ 996 NetCfg_ACC "0h";
BA_ "GenSigTimeout_IC" SG_ 996 NetCfg_ACC 21000;
BA_ "FlexKomComment" SG_ 996 NetCfg_ADCM "Network ECU config data for Powertrain";
BA_ "FlexKomIsMotorola" SG_ 996 NetCfg_ADCM 1;
BA_ "FlexKomSID" SG_ 996 NetCfg_ADCM 39;
BA_ "FlexKomSigLaenge" SG_ 996 NetCfg_ADCM 64;
BA_ "FlexKomSigName" SG_ 996 NetCfg_ADCM "NET_CFG_DATA_PT";
BA_ "FlexKomSigStartPos" SG_ 996 NetCfg_ADCM 7;
BA_ "FlexKomSigStartValue" SG_ 996 NetCfg_ADCM "0300000000000000h";
BA_ "GenSigCycleTime" SG_ 996 NetCfg_ADCM 2000;
BA_ "GenSigSendType" SG_ 996 NetCfg_ADCM 5;
BA_ "GenSigSNA" SG_ 996 NetCfg_ADCM "0h";
BA_ "GenSigTimeout_IC" SG_ 996 NetCfg_ADCM 21000;
BA_ "GenSigTimeout_ORC" SG_ 996 NetCfg_ADCM 7000;
BA_ "FlexKomComment" SG_ 996 NetCfg_AFLS "Network ECU config data for Powertrain";
BA_ "FlexKomIsMotorola" SG_ 996 NetCfg_AFLS 1;
BA_ "FlexKomSID" SG_ 996 NetCfg_AFLS 39;
BA_ "FlexKomSigLaenge" SG_ 996 NetCfg_AFLS 64;
BA_ "FlexKomSigName" SG_ 996 NetCfg_AFLS "NET_CFG_DATA_PT";
BA_ "FlexKomSigStartPos" SG_ 996 NetCfg_AFLS 7;
BA_ "FlexKomSigStartValue" SG_ 996 NetCfg_AFLS "0300000000000000h";
BA_ "GenSigCycleTime" SG_ 996 NetCfg_AFLS 2000;
BA_ "GenSigSendType" SG_ 996 NetCfg_AFLS 5;
BA_ "GenSigSNA" SG_ 996 NetCfg_AFLS "0h";
BA_ "GenSigTimeout_IC" SG_ 996 NetCfg_AFLS 21000;
BA_ "FlexKomComment" SG_ 996 NetCfg_AHLM "Network ECU config data for Powertrain";
BA_ "FlexKomIsMotorola" SG_ 996 NetCfg_AHLM 1;
BA_ "FlexKomSID" SG_ 996 NetCfg_AHLM 39;
BA_ "FlexKomSigLaenge" SG_ 996 NetCfg_AHLM 64;
BA_ "FlexKomSigName" SG_ 996 NetCfg_AHLM "NET_CFG_DATA_PT";
BA_ "FlexKomSigStartPos" SG_ 996 NetCfg_AHLM 7;
BA_ "FlexKomSigStartValue" SG_ 996 NetCfg_AHLM "0300000000000000h";
BA_ "GenSigCycleTime" SG_ 996 NetCfg_AHLM 2000;
BA_ "GenSigSendType" SG_ 996 NetCfg_AHLM 5;
BA_ "GenSigSNA" SG_ 996 NetCfg_AHLM "0h";
BA_ "GenSigTimeout_IC" SG_ 996 NetCfg_AHLM 21000;
BA_ "FlexKomComment" SG_ 996 NetCfg_ANC "Network ECU config data for Powertrain";
BA_ "FlexKomIsMotorola" SG_ 996 NetCfg_ANC 1;
BA_ "FlexKomSID" SG_ 996 NetCfg_ANC 39;
BA_ "FlexKomSigLaenge" SG_ 996 NetCfg_ANC 64;
BA_ "FlexKomSigName" SG_ 996 NetCfg_ANC "NET_CFG_DATA_PT";
BA_ "FlexKomSigStartPos" SG_ 996 NetCfg_ANC 7;
BA_ "FlexKomSigStartValue" SG_ 996 NetCfg_ANC "0300000000000000h";
BA_ "GenSigCycleTime" SG_ 996 NetCfg_ANC 2000;
BA_ "GenSigSendType" SG_ 996 NetCfg_ANC 5;
BA_ "GenSigSNA" SG_ 996 NetCfg_ANC "0h";
BA_ "FlexKomComment" SG_ 996 NetCfg_ASCM "Network ECU config data for Powertrain";
BA_ "FlexKomIsMotorola" SG_ 996 NetCfg_ASCM 1;
BA_ "FlexKomSID" SG_ 996 NetCfg_ASCM 39;
BA_ "FlexKomSigLaenge" SG_ 996 NetCfg_ASCM 64;
BA_ "FlexKomSigName" SG_ 996 NetCfg_ASCM "NET_CFG_DATA_PT";
BA_ "FlexKomSigStartPos" SG_ 996 NetCfg_ASCM 7;
BA_ "FlexKomSigStartValue" SG_ 996 NetCfg_ASCM "0300000000000000h";
BA_ "GenSigCycleTime" SG_ 996 NetCfg_ASCM 2000;
BA_ "GenSigSendType" SG_ 996 NetCfg_ASCM 5;
BA_ "GenSigSNA" SG_ 996 NetCfg_ASCM "0h";
BA_ "GenSigTimeout_IC" SG_ 996 NetCfg_ASCM 21000;
BA_ "FlexKomComment" SG_ 996 NetCfg_BSMO "Network ECU config data for Powertrain";
BA_ "FlexKomIsMotorola" SG_ 996 NetCfg_BSMO 1;
BA_ "FlexKomSID" SG_ 996 NetCfg_BSMO 39;
BA_ "FlexKomSigLaenge" SG_ 996 NetCfg_BSMO 64;
BA_ "FlexKomSigName" SG_ 996 NetCfg_BSMO "NET_CFG_DATA_PT";
BA_ "FlexKomSigStartPos" SG_ 996 NetCfg_BSMO 7;
BA_ "FlexKomSigStartValue" SG_ 996 NetCfg_BSMO "0300000000000000h";
BA_ "GenSigCycleTime" SG_ 996 NetCfg_BSMO 2000;
BA_ "GenSigSendType" SG_ 996 NetCfg_BSMO 5;
BA_ "GenSigSNA" SG_ 996 NetCfg_BSMO "0h";
BA_ "RID" SG_ 996 NetCfg_BSMO "9780";
BA_ "FlexKomComment" SG_ 996 NetCfg_CBC_PT "Network ECU config data for Powertrain";
BA_ "FlexKomIsMotorola" SG_ 996 NetCfg_CBC_PT 1;
BA_ "FlexKomSID" SG_ 996 NetCfg_CBC_PT 39;
BA_ "FlexKomSigLaenge" SG_ 996 NetCfg_CBC_PT 64;
BA_ "FlexKomSigName" SG_ 996 NetCfg_CBC_PT "NET_CFG_DATA_PT";
BA_ "FlexKomSigStartPos" SG_ 996 NetCfg_CBC_PT 7;
BA_ "FlexKomSigStartValue" SG_ 996 NetCfg_CBC_PT "0300000000000000h";
BA_ "GenSigCycleTime" SG_ 996 NetCfg_CBC_PT 2000;
BA_ "GenSigSendType" SG_ 996 NetCfg_CBC_PT 5;
BA_ "GenSigSNA" SG_ 996 NetCfg_CBC_PT "0h";
BA_ "GenSigTimeout_EPS" SG_ 996 NetCfg_CBC_PT 21000;
BA_ "GenSigTimeout_RHSC2" SG_ 996 NetCfg_CBC_PT 21000;
BA_ "GenSigTimeout_IC" SG_ 996 NetCfg_CBC_PT 21000;
BA_ "GenSigTimeout_OCM" SG_ 996 NetCfg_CBC_PT 21000;
BA_ "GenSigTimeout_ORC" SG_ 996 NetCfg_CBC_PT 7000;
BA_ "RID" SG_ 996 NetCfg_CBC_PT "9781";
BA_ "FlexKomComment" SG_ 996 NetCfg_DASM "Network ECU config data for Powertrain";
BA_ "FlexKomIsMotorola" SG_ 996 NetCfg_DASM 1;
BA_ "FlexKomSID" SG_ 996 NetCfg_DASM 39;
BA_ "FlexKomSigLaenge" SG_ 996 NetCfg_DASM 64;
BA_ "FlexKomSigName" SG_ 996 NetCfg_DASM "NET_CFG_DATA_PT";
BA_ "FlexKomSigStartPos" SG_ 996 NetCfg_DASM 7;
BA_ "FlexKomSigStartValue" SG_ 996 NetCfg_DASM "0300000000000000h";
BA_ "GenSigCycleTime" SG_ 996 NetCfg_DASM 2000;
BA_ "GenSigSendType" SG_ 996 NetCfg_DASM 5;
BA_ "GenSigSNA" SG_ 996 NetCfg_DASM "0h";
BA_ "GenSigTimeout_IC" SG_ 996 NetCfg_DASM 21000;
BA_ "GenSigTimeout_ORC" SG_ 996 NetCfg_DASM 7000;
BA_ "FlexKomComment" SG_ 996 NetCfg_DTCM "Network ECU config data for Powertrain";
BA_ "FlexKomIsMotorola" SG_ 996 NetCfg_DTCM 1;
BA_ "FlexKomSID" SG_ 996 NetCfg_DTCM 39;
BA_ "FlexKomSigLaenge" SG_ 996 NetCfg_DTCM 64;
BA_ "FlexKomSigName" SG_ 996 NetCfg_DTCM "NET_CFG_DATA_PT";
BA_ "FlexKomSigStartPos" SG_ 996 NetCfg_DTCM 7;
BA_ "FlexKomSigStartValue" SG_ 996 NetCfg_DTCM "0300000000000000h";
BA_ "GenSigCycleTime" SG_ 996 NetCfg_DTCM 2000;
BA_ "GenSigSendType" SG_ 996 NetCfg_DTCM 5;
BA_ "GenSigSNA" SG_ 996 NetCfg_DTCM "0h";
BA_ "GenSigTimeout_IC" SG_ 996 NetCfg_DTCM 21000;
BA_ "GenSigTimeout_ORC" SG_ 996 NetCfg_DTCM 7000;
BA_ "FlexKomComment" SG_ 996 NetCfg_ECM "Network ECU config data for Powertrain";
BA_ "FlexKomIsMotorola" SG_ 996 NetCfg_ECM 1;
BA_ "FlexKomSID" SG_ 996 NetCfg_ECM 39;
BA_ "FlexKomSigLaenge" SG_ 996 NetCfg_ECM 64;
BA_ "FlexKomSigName" SG_ 996 NetCfg_ECM "NET_CFG_DATA_PT";
BA_ "FlexKomSigStartPos" SG_ 996 NetCfg_ECM 7;
BA_ "FlexKomSigStartValue" SG_ 996 NetCfg_ECM "0300000000000000h";
BA_ "GenSigCycleTime" SG_ 996 NetCfg_ECM 2000;
BA_ "GenSigSendType" SG_ 996 NetCfg_ECM 5;
BA_ "GenSigSNA" SG_ 996 NetCfg_ECM "0h";
BA_ "GenSigTimeout_EPS" SG_ 996 NetCfg_ECM 21000;
BA_ "GenSigTimeout_RHSC2" SG_ 996 NetCfg_ECM 21000;
BA_ "GenSigTimeout_IC" SG_ 996 NetCfg_ECM 21000;
BA_ "GenSigTimeout_OCM" SG_ 996 NetCfg_ECM 21000;
BA_ "GenSigTimeout_ORC" SG_ 996 NetCfg_ECM 7000;
BA_ "RID" SG_ 996 NetCfg_ECM "9782";
BA_ "FlexKomComment" SG_ 996 NetCfg_ELSD "Network ECU config data for Powertrain";
BA_ "FlexKomIsMotorola" SG_ 996 NetCfg_ELSD 1;
BA_ "FlexKomSID" SG_ 996 NetCfg_ELSD 39;
BA_ "FlexKomSigLaenge" SG_ 996 NetCfg_ELSD 64;
BA_ "FlexKomSigName" SG_ 996 NetCfg_ELSD "NET_CFG_DATA_PT";
BA_ "FlexKomSigStartPos" SG_ 996 NetCfg_ELSD 7;
BA_ "FlexKomSigStartValue" SG_ 996 NetCfg_ELSD "0300000000000000h";
BA_ "GenSigCycleTime" SG_ 996 NetCfg_ELSD 2000;
BA_ "GenSigSendType" SG_ 996 NetCfg_ELSD 5;
BA_ "GenSigSNA" SG_ 996 NetCfg_ELSD "0h";
BA_ "GenSigTimeout_IC" SG_ 996 NetCfg_ELSD 21000;
BA_ "FlexKomComment" SG_ 996 NetCfg_EPB "Network ECU config data for Powertrain";
BA_ "FlexKomIsMotorola" SG_ 996 NetCfg_EPB 1;
BA_ "FlexKomSID" SG_ 996 NetCfg_EPB 39;
BA_ "FlexKomSigLaenge" SG_ 996 NetCfg_EPB 64;
BA_ "FlexKomSigName" SG_ 996 NetCfg_EPB "NET_CFG_DATA_PT";
BA_ "FlexKomSigStartPos" SG_ 996 NetCfg_EPB 7;
BA_ "FlexKomSigStartValue" SG_ 996 NetCfg_EPB "0300000000000000h";
BA_ "GenSigCycleTime" SG_ 996 NetCfg_EPB 2000;
BA_ "GenSigSendType" SG_ 996 NetCfg_EPB 5;
BA_ "GenSigSNA" SG_ 996 NetCfg_EPB "0h";
BA_ "GenSigTimeout_IC" SG_ 996 NetCfg_EPB 21000;
BA_ "GenSigTimeout_ORC" SG_ 996 NetCfg_EPB 7000;
BA_ "FlexKomComment" SG_ 996 NetCfg_EPPM "Network ECU config data for Powertrain";
BA_ "FlexKomIsMotorola" SG_ 996 NetCfg_EPPM 1;
BA_ "FlexKomSID" SG_ 996 NetCfg_EPPM 39;
BA_ "FlexKomSigLaenge" SG_ 996 NetCfg_EPPM 64;
BA_ "FlexKomSigName" SG_ 996 NetCfg_EPPM "NET_CFG_DATA_PT";
BA_ "FlexKomSigStartPos" SG_ 996 NetCfg_EPPM 7;
BA_ "FlexKomSigStartValue" SG_ 996 NetCfg_EPPM "0300000000000000h";
BA_ "GenSigCycleTime" SG_ 996 NetCfg_EPPM 2000;
BA_ "GenSigSendType" SG_ 996 NetCfg_EPPM 5;
BA_ "GenSigSNA" SG_ 996 NetCfg_EPPM "0h";
BA_ "GenSigTimeout_ORC" SG_ 996 NetCfg_EPPM 7000;
BA_ "FlexKomComment" SG_ 996 NetCfg_EPS "Network ECU config data for Powertrain";
BA_ "FlexKomIsMotorola" SG_ 996 NetCfg_EPS 1;
BA_ "FlexKomSID" SG_ 996 NetCfg_EPS 39;
BA_ "FlexKomSigLaenge" SG_ 996 NetCfg_EPS 64;
BA_ "FlexKomSigName" SG_ 996 NetCfg_EPS "NET_CFG_DATA_PT";
BA_ "FlexKomSigStartPos" SG_ 996 NetCfg_EPS 7;
BA_ "FlexKomSigStartValue" SG_ 996 NetCfg_EPS "0300000000000000h";
BA_ "GenSigCycleTime" SG_ 996 NetCfg_EPS 2000;
BA_ "GenSigSendType" SG_ 996 NetCfg_EPS 5;
BA_ "GenSigSNA" SG_ 996 NetCfg_EPS "0h";
BA_ "GenSigTimeout_IC" SG_ 996 NetCfg_EPS 21000;
BA_ "GenSigTimeout_ORC" SG_ 996 NetCfg_EPS 7000;
BA_ "FlexKomComment" SG_ 996 NetCfg_ESC "Network ECU config data for Powertrain";
BA_ "FlexKomIsMotorola" SG_ 996 NetCfg_ESC 1;
BA_ "FlexKomSID" SG_ 996 NetCfg_ESC 39;
BA_ "FlexKomSigLaenge" SG_ 996 NetCfg_ESC 64;
BA_ "FlexKomSigName" SG_ 996 NetCfg_ESC "NET_CFG_DATA_PT";
BA_ "FlexKomSigStartPos" SG_ 996 NetCfg_ESC 7;
BA_ "FlexKomSigStartValue" SG_ 996 NetCfg_ESC "0300000000000000h";
BA_ "GenSigCycleTime" SG_ 996 NetCfg_ESC 2000;
BA_ "GenSigSendType" SG_ 996 NetCfg_ESC 5;
BA_ "GenSigSNA" SG_ 996 NetCfg_ESC "0h";
BA_ "GenSigTimeout_EPS" SG_ 996 NetCfg_ESC 21000;
BA_ "GenSigTimeout_RHSC2" SG_ 996 NetCfg_ESC 21000;
BA_ "GenSigTimeout_IC" SG_ 996 NetCfg_ESC 21000;
BA_ "GenSigTimeout_ORC" SG_ 996 NetCfg_ESC 7000;
BA_ "RID" SG_ 996 NetCfg_ESC "9992";
BA_ "FlexKomComment" SG_ 996 NetCfg_ESL "Network ECU config data for Powertrain";
BA_ "FlexKomIsMotorola" SG_ 996 NetCfg_ESL 1;
BA_ "FlexKomSID" SG_ 996 NetCfg_ESL 39;
BA_ "FlexKomSigLaenge" SG_ 996 NetCfg_ESL 64;
BA_ "FlexKomSigName" SG_ 996 NetCfg_ESL "NET_CFG_DATA_PT";
BA_ "FlexKomSigStartPos" SG_ 996 NetCfg_ESL 7;
BA_ "FlexKomSigStartValue" SG_ 996 NetCfg_ESL "0300000000000000h";
BA_ "GenSigCycleTime" SG_ 996 NetCfg_ESL 2000;
BA_ "GenSigSendType" SG_ 996 NetCfg_ESL 5;
BA_ "GenSigSNA" SG_ 996 NetCfg_ESL "0h";
BA_ "FlexKomComment" SG_ 996 NetCfg_ESM "Network ECU config data for Powertrain";
BA_ "FlexKomIsMotorola" SG_ 996 NetCfg_ESM 1;
BA_ "FlexKomSID" SG_ 996 NetCfg_ESM 39;
BA_ "FlexKomSigLaenge" SG_ 996 NetCfg_ESM 64;
BA_ "FlexKomSigName" SG_ 996 NetCfg_ESM "NET_CFG_DATA_PT";
BA_ "FlexKomSigStartPos" SG_ 996 NetCfg_ESM 7;
BA_ "FlexKomSigStartValue" SG_ 996 NetCfg_ESM "0300000000000000h";
BA_ "GenSigCycleTime" SG_ 996 NetCfg_ESM 2000;
BA_ "GenSigSendType" SG_ 996 NetCfg_ESM 5;
BA_ "GenSigSNA" SG_ 996 NetCfg_ESM "0h";
BA_ "GenSigTimeout_RHSC2" SG_ 996 NetCfg_ESM 21000;
BA_ "GenSigTimeout_IC" SG_ 996 NetCfg_ESM 21000;
BA_ "FlexKomComment" SG_ 996 NetCfg_FDCM "Network ECU config data for Powertrain";
BA_ "FlexKomIsMotorola" SG_ 996 NetCfg_FDCM 1;
BA_ "FlexKomSID" SG_ 996 NetCfg_FDCM 39;
BA_ "FlexKomSigLaenge" SG_ 996 NetCfg_FDCM 64;
BA_ "FlexKomSigName" SG_ 996 NetCfg_FDCM "NET_CFG_DATA_PT";
BA_ "FlexKomSigStartPos" SG_ 996 NetCfg_FDCM 7;
BA_ "FlexKomSigStartValue" SG_ 996 NetCfg_FDCM "0300000000000000h";
BA_ "GenSigCycleTime" SG_ 996 NetCfg_FDCM 2000;
BA_ "GenSigSendType" SG_ 996 NetCfg_FDCM 5;
BA_ "GenSigSNA" SG_ 996 NetCfg_FDCM "0h";
BA_ "FlexKomComment" SG_ 996 NetCfg_HCP "Network ECU config data for Powertrain";
BA_ "FlexKomIsMotorola" SG_ 996 NetCfg_HCP 1;
BA_ "FlexKomSID" SG_ 996 NetCfg_HCP 39;
BA_ "FlexKomSigLaenge" SG_ 996 NetCfg_HCP 64;
BA_ "FlexKomSigName" SG_ 996 NetCfg_HCP "NET_CFG_DATA_PT";
BA_ "FlexKomSigStartPos" SG_ 996 NetCfg_HCP 7;
BA_ "FlexKomSigStartValue" SG_ 996 NetCfg_HCP "0300000000000000h";
BA_ "GenSigCycleTime" SG_ 996 NetCfg_HCP 2000;
BA_ "GenSigSendType" SG_ 996 NetCfg_HCP 5;
BA_ "GenSigSNA" SG_ 996 NetCfg_HCP "0h";
BA_ "GenSigTimeout_ORC" SG_ 996 NetCfg_HCP 7000;
BA_ "RID" SG_ 996 NetCfg_HCP "9783";
BA_ "FlexKomComment" SG_ 996 NetCfg_HaLF "Network ECU config data for Powertrain";
BA_ "FlexKomIsMotorola" SG_ 996 NetCfg_HaLF 1;
BA_ "FlexKomSID" SG_ 996 NetCfg_HaLF 39;
BA_ "FlexKomSigLaenge" SG_ 996 NetCfg_HaLF 64;
BA_ "FlexKomSigName" SG_ 996 NetCfg_HaLF "NET_CFG_DATA_PT";
BA_ "FlexKomSigStartPos" SG_ 996 NetCfg_HaLF 7;
BA_ "FlexKomSigStartValue" SG_ 996 NetCfg_HaLF "0300000000000000h";
BA_ "GenSigCycleTime" SG_ 996 NetCfg_HaLF 2000;
BA_ "GenSigSendType" SG_ 996 NetCfg_HaLF 5;
BA_ "GenSigSNA" SG_ 996 NetCfg_HaLF "0h";
BA_ "GenSigTimeout_EPS" SG_ 996 NetCfg_HaLF 21000;
BA_ "FlexKomComment" SG_ 996 NetCfg_IC "Network ECU config data for Powertrain";
BA_ "FlexKomIsMotorola" SG_ 996 NetCfg_IC 1;
BA_ "FlexKomSID" SG_ 996 NetCfg_IC 39;
BA_ "FlexKomSigLaenge" SG_ 996 NetCfg_IC 64;
BA_ "FlexKomSigName" SG_ 996 NetCfg_IC "NET_CFG_DATA_PT";
BA_ "FlexKomSigStartPos" SG_ 996 NetCfg_IC 7;
BA_ "FlexKomSigStartValue" SG_ 996 NetCfg_IC "0300000000000000h";
BA_ "GenSigCycleTime" SG_ 996 NetCfg_IC 2000;
BA_ "GenSigSendType" SG_ 996 NetCfg_IC 5;
BA_ "GenSigSNA" SG_ 996 NetCfg_IC "0h";
BA_ "GenSigTimeout_EPS" SG_ 996 NetCfg_IC 21000;
BA_ "GenSigTimeout_RHSC2" SG_ 996 NetCfg_IC 21000;
BA_ "GenSigTimeout_IC" SG_ 996 NetCfg_IC 21000;
BA_ "RID" SG_ 996 NetCfg_IC "9784";
BA_ "FlexKomComment" SG_ 996 NetCfg_ITBM "Network ECU config data for Powertrain";
BA_ "FlexKomIsMotorola" SG_ 996 NetCfg_ITBM 1;
BA_ "FlexKomSID" SG_ 996 NetCfg_ITBM 39;
BA_ "FlexKomSigLaenge" SG_ 996 NetCfg_ITBM 64;
BA_ "FlexKomSigName" SG_ 996 NetCfg_ITBM "NET_CFG_DATA_PT";
BA_ "FlexKomSigStartPos" SG_ 996 NetCfg_ITBM 7;
BA_ "FlexKomSigStartValue" SG_ 996 NetCfg_ITBM "0300000000000000h";
BA_ "GenSigCycleTime" SG_ 996 NetCfg_ITBM 2000;
BA_ "GenSigSendType" SG_ 996 NetCfg_ITBM 5;
BA_ "GenSigSNA" SG_ 996 NetCfg_ITBM "0h";
BA_ "GenSigTimeout_IC" SG_ 996 NetCfg_ITBM 21000;
BA_ "FlexKomComment" SG_ 996 NetCfg_OCM "Network ECU config data for Powertrain";
BA_ "FlexKomIsMotorola" SG_ 996 NetCfg_OCM 1;
BA_ "FlexKomSID" SG_ 996 NetCfg_OCM 39;
BA_ "FlexKomSigLaenge" SG_ 996 NetCfg_OCM 64;
BA_ "FlexKomSigName" SG_ 996 NetCfg_OCM "NET_CFG_DATA_PT";
BA_ "FlexKomSigStartPos" SG_ 996 NetCfg_OCM 7;
BA_ "FlexKomSigStartValue" SG_ 996 NetCfg_OCM "0300000000000000h";
BA_ "GenSigCycleTime" SG_ 996 NetCfg_OCM 2000;
BA_ "GenSigSendType" SG_ 996 NetCfg_OCM 5;
BA_ "GenSigSNA" SG_ 996 NetCfg_OCM "0h";
BA_ "GenSigTimeout_ORC" SG_ 996 NetCfg_OCM 7000;
BA_ "FlexKomComment" SG_ 996 NetCfg_ORC "Network ECU config data for Powertrain";
BA_ "FlexKomIsMotorola" SG_ 996 NetCfg_ORC 1;
BA_ "FlexKomSID" SG_ 996 NetCfg_ORC 39;
BA_ "FlexKomSigLaenge" SG_ 996 NetCfg_ORC 64;
BA_ "FlexKomSigName" SG_ 996 NetCfg_ORC "NET_CFG_DATA_PT";
BA_ "FlexKomSigStartPos" SG_ 996 NetCfg_ORC 7;
BA_ "FlexKomSigStartValue" SG_ 996 NetCfg_ORC "0300000000000000h";
BA_ "GenSigCycleTime" SG_ 996 NetCfg_ORC 2000;
BA_ "GenSigSendType" SG_ 996 NetCfg_ORC 5;
BA_ "GenSigSNA" SG_ 996 NetCfg_ORC "0h";
BA_ "GenSigTimeout_IC" SG_ 996 NetCfg_ORC 21000;
BA_ "GenSigTimeout_OCM" SG_ 996 NetCfg_ORC 21000;
BA_ "FlexKomComment" SG_ 996 NetCfg_PASS_PT "Network ECU config data for Powertrain";
BA_ "FlexKomIsMotorola" SG_ 996 NetCfg_PASS_PT 1;
BA_ "FlexKomSID" SG_ 996 NetCfg_PASS_PT 39;
BA_ "FlexKomSigLaenge" SG_ 996 NetCfg_PASS_PT 64;
BA_ "FlexKomSigName" SG_ 996 NetCfg_PASS_PT "NET_CFG_DATA_PT";
BA_ "FlexKomSigStartPos" SG_ 996 NetCfg_PASS_PT 7;
BA_ "FlexKomSigStartValue" SG_ 996 NetCfg_PASS_PT "0300000000000000h";
BA_ "GenSigCycleTime" SG_ 996 NetCfg_PASS_PT 2000;
BA_ "GenSigSendType" SG_ 996 NetCfg_PASS_PT 5;
BA_ "GenSigSNA" SG_ 996 NetCfg_PASS_PT "0h";
BA_ "GenSigTimeout_IC" SG_ 996 NetCfg_PASS_PT 21000;
BA_ "FlexKomComment" SG_ 996 NetCfg_PTS "Network ECU config data for Powertrain";
BA_ "FlexKomIsMotorola" SG_ 996 NetCfg_PTS 1;
BA_ "FlexKomSID" SG_ 996 NetCfg_PTS 39;
BA_ "FlexKomSigLaenge" SG_ 996 NetCfg_PTS 64;
BA_ "FlexKomSigName" SG_ 996 NetCfg_PTS "NET_CFG_DATA_PT";
BA_ "FlexKomSigStartPos" SG_ 996 NetCfg_PTS 7;
BA_ "FlexKomSigStartValue" SG_ 996 NetCfg_PTS "0300000000000000h";
BA_ "GenSigCycleTime" SG_ 996 NetCfg_PTS 2000;
BA_ "GenSigSendType" SG_ 996 NetCfg_PTS 5;
BA_ "GenSigSNA" SG_ 996 NetCfg_PTS "0h";
BA_ "GenSigTimeout_IC" SG_ 996 NetCfg_PTS 21000;
BA_ "RID" SG_ 996 NetCfg_PTS "9785";
BA_ "FlexKomComment" SG_ 996 NetCfg_RF_HUB "Network ECU config data for Powertrain";
BA_ "FlexKomIsMotorola" SG_ 996 NetCfg_RF_HUB 1;
BA_ "FlexKomSID" SG_ 996 NetCfg_RF_HUB 39;
BA_ "FlexKomSigLaenge" SG_ 996 NetCfg_RF_HUB 64;
BA_ "FlexKomSigName" SG_ 996 NetCfg_RF_HUB "NET_CFG_DATA_PT";
BA_ "FlexKomSigStartPos" SG_ 996 NetCfg_RF_HUB 7;
BA_ "FlexKomSigStartValue" SG_ 996 NetCfg_RF_HUB "0300000000000000h";
BA_ "GenSigCycleTime" SG_ 996 NetCfg_RF_HUB 2000;
BA_ "GenSigSendType" SG_ 996 NetCfg_RF_HUB 5;
BA_ "GenSigSNA" SG_ 996 NetCfg_RF_HUB "0h";
BA_ "GenSigTimeout_IC" SG_ 996 NetCfg_RF_HUB 21000;
BA_ "FlexKomComment" SG_ 996 NetCfg_RHSC2 "Network ECU config data for Powertrain";
BA_ "FlexKomIsMotorola" SG_ 996 NetCfg_RHSC2 1;
BA_ "FlexKomSID" SG_ 996 NetCfg_RHSC2 39;
BA_ "FlexKomSigLaenge" SG_ 996 NetCfg_RHSC2 64;
BA_ "FlexKomSigName" SG_ 996 NetCfg_RHSC2 "NET_CFG_DATA_PT";
BA_ "FlexKomSigStartPos" SG_ 996 NetCfg_RHSC2 7;
BA_ "FlexKomSigStartValue" SG_ 996 NetCfg_RHSC2 "0300000000000000h";
BA_ "GenSigCycleTime" SG_ 996 NetCfg_RHSC2 2000;
BA_ "GenSigSendType" SG_ 996 NetCfg_RHSC2 5;
BA_ "GenSigSNA" SG_ 996 NetCfg_RHSC2 "0h";
BA_ "RID" SG_ 996 NetCfg_RHSC2 "9779";
BA_ "FlexKomComment" SG_ 996 NetCfg_SCCM "Network ECU config data for Powertrain";
BA_ "FlexKomIsMotorola" SG_ 996 NetCfg_SCCM 1;
BA_ "FlexKomSID" SG_ 996 NetCfg_SCCM 39;
BA_ "FlexKomSigLaenge" SG_ 996 NetCfg_SCCM 64;
BA_ "FlexKomSigName" SG_ 996 NetCfg_SCCM "NET_CFG_DATA_PT";
BA_ "FlexKomSigStartPos" SG_ 996 NetCfg_SCCM 7;
BA_ "FlexKomSigStartValue" SG_ 996 NetCfg_SCCM "0300000000000000h";
BA_ "GenSigCycleTime" SG_ 996 NetCfg_SCCM 2000;
BA_ "GenSigSendType" SG_ 996 NetCfg_SCCM 5;
BA_ "GenSigSNA" SG_ 996 NetCfg_SCCM "0h";
BA_ "GenSigTimeout_EPS" SG_ 996 NetCfg_SCCM 21000;
BA_ "GenSigTimeout_IC" SG_ 996 NetCfg_SCCM 21000;
BA_ "GenSigTimeout_ORC" SG_ 996 NetCfg_SCCM 7000;
BA_ "GenSigTimeout_SCCM" SG_ 996 NetCfg_SCCM 21000;
BA_ "RID" SG_ 996 NetCfg_SCCM "9786";
BA_ "FlexKomComment" SG_ 996 NetCfg_TCM "Network ECU config data for Powertrain";
BA_ "FlexKomIsMotorola" SG_ 996 NetCfg_TCM 1;
BA_ "FlexKomSID" SG_ 996 NetCfg_TCM 39;
BA_ "FlexKomSigLaenge" SG_ 996 NetCfg_TCM 64;
BA_ "FlexKomSigName" SG_ 996 NetCfg_TCM "NET_CFG_DATA_PT";
BA_ "FlexKomSigStartPos" SG_ 996 NetCfg_TCM 7;
BA_ "FlexKomSigStartValue" SG_ 996 NetCfg_TCM "0300000000000000h";
BA_ "GenSigCycleTime" SG_ 996 NetCfg_TCM 2000;
BA_ "GenSigSendType" SG_ 996 NetCfg_TCM 5;
BA_ "GenSigSNA" SG_ 996 NetCfg_TCM "0h";
BA_ "GenSigTimeout_RHSC2" SG_ 996 NetCfg_TCM 21000;
BA_ "GenSigTimeout_IC" SG_ 996 NetCfg_TCM 21000;
BA_ "GenSigTimeout_ORC" SG_ 996 NetCfg_TCM 7000;
BA_ "RID" SG_ 996 NetCfg_TCM "9749";
BA_ "FlexKomComment" SG_ 996 NetCfg_TPM "Network ECU config data for Powertrain";
BA_ "FlexKomIsMotorola" SG_ 996 NetCfg_TPM 1;
BA_ "FlexKomSID" SG_ 996 NetCfg_TPM 39;
BA_ "FlexKomSigLaenge" SG_ 996 NetCfg_TPM 64;
BA_ "FlexKomSigName" SG_ 996 NetCfg_TPM "NET_CFG_DATA_PT";
BA_ "FlexKomSigStartPos" SG_ 996 NetCfg_TPM 7;
BA_ "FlexKomSigStartValue" SG_ 996 NetCfg_TPM "0300000000000000h";
BA_ "GenSigCycleTime" SG_ 996 NetCfg_TPM 2000;
BA_ "GenSigSendType" SG_ 996 NetCfg_TPM 5;
BA_ "GenSigSNA" SG_ 996 NetCfg_TPM "0h";
BA_ "GenSigTimeout_IC" SG_ 996 NetCfg_TPM 21000;
BA_ "GenSigTimeout_ORC" SG_ 996 NetCfg_TPM 7000;
BA_ "FlexKomComment" SG_ 996 NetCfg_VSIM_C "Network ECU config data for Powertrain";
BA_ "FlexKomIsMotorola" SG_ 996 NetCfg_VSIM_C 1;
BA_ "FlexKomSID" SG_ 996 NetCfg_VSIM_C 39;
BA_ "FlexKomSigLaenge" SG_ 996 NetCfg_VSIM_C 64;
BA_ "FlexKomSigName" SG_ 996 NetCfg_VSIM_C "NET_CFG_DATA_PT";
BA_ "FlexKomSigStartPos" SG_ 996 NetCfg_VSIM_C 7;
BA_ "FlexKomSigStartValue" SG_ 996 NetCfg_VSIM_C "0300000000000000h";
BA_ "GenSigCycleTime" SG_ 996 NetCfg_VSIM_C 2000;
BA_ "GenSigSendType" SG_ 996 NetCfg_VSIM_C 5;
BA_ "GenSigSNA" SG_ 996 NetCfg_VSIM_C "0h";
BA_ "GenSigTimeout_IC" SG_ 996 NetCfg_VSIM_C 21000;
BA_ "FlexKomComment" SG_ 1025 Awake_Diag_Actv "Mode 15 of NM_Ud_Srv";
BA_ "FlexKomIsMotorola" SG_ 1025 Awake_Diag_Actv 1;
BA_ "FlexKomSID" SG_ 1025 Awake_Diag_Actv 504;
BA_ "FlexKomSigLaenge" SG_ 1025 Awake_Diag_Actv 24;
BA_ "FlexKomSigName" SG_ 1025 Awake_Diag_Actv "Awake_CBC";
BA_ "FlexKomSigStartPos" SG_ 1025 Awake_Diag_Actv 39;
BA_ "FlexKomSigStartValue" SG_ 1025 Awake_Diag_Actv "000000h";
BA_ "GenSigSendType" SG_ 1025 Awake_Diag_Actv 1;
BA_ "GenSigSNA" SG_ 1025 Awake_Diag_Actv "0h";
BA_ "RID" SG_ 1025 Awake_Diag_Actv "9626";
BA_ "FlexKomComment" SG_ 1025 Awake_NwSt "Mode 15 of NM_Ud_Srv";
BA_ "FlexKomIsMotorola" SG_ 1025 Awake_NwSt 1;
BA_ "FlexKomSID" SG_ 1025 Awake_NwSt 504;
BA_ "FlexKomSigLaenge" SG_ 1025 Awake_NwSt 24;
BA_ "FlexKomSigName" SG_ 1025 Awake_NwSt "Awake_CBC";
BA_ "FlexKomSigStartPos" SG_ 1025 Awake_NwSt 39;
BA_ "FlexKomSigStartValue" SG_ 1025 Awake_NwSt "000000h";
BA_ "GenSigSendType" SG_ 1025 Awake_NwSt 1;
BA_ "GenSigSNA" SG_ 1025 Awake_NwSt "0h";
BA_ "RID" SG_ 1025 Awake_NwSt "9627";
BA_ "FlexKomComment" SG_ 1025 NM_Mode "Network management state";
BA_ "FlexKomIsMotorola" SG_ 1025 NM_Mode 1;
BA_ "FlexKomSID" SG_ 1025 NM_Mode 472;
BA_ "FlexKomSigLaenge" SG_ 1025 NM_Mode 32;
BA_ "FlexKomSigName" SG_ 1025 NM_Mode "NM";
BA_ "FlexKomSigStartPos" SG_ 1025 NM_Mode 7;
BA_ "FlexKomSigStartValue" SG_ 1025 NM_Mode "FFFFFFFFh";
BA_ "GenSigSendType" SG_ 1025 NM_Mode 1;
BA_ "GenSigSNA" SG_ 1025 NM_Mode "FFh";
BA_ "GenSigStartValue" SG_ 1025 NM_Mode 255;
BA_ "RID" SG_ 1025 NM_Mode "9628";
BA_ "FlexKomComment" SG_ 1025 NM_Sleep_Ack "Network management state";
BA_ "FlexKomIsMotorola" SG_ 1025 NM_Sleep_Ack 1;
BA_ "FlexKomSID" SG_ 1025 NM_Sleep_Ack 472;
BA_ "FlexKomSigLaenge" SG_ 1025 NM_Sleep_Ack 32;
BA_ "FlexKomSigName" SG_ 1025 NM_Sleep_Ack "NM";
BA_ "FlexKomSigStartPos" SG_ 1025 NM_Sleep_Ack 7;
BA_ "FlexKomSigStartValue" SG_ 1025 NM_Sleep_Ack "FFFFFFFFh";
BA_ "GenSigSendType" SG_ 1025 NM_Sleep_Ack 1;
BA_ "GenSigSNA" SG_ 1025 NM_Sleep_Ack "1h";
BA_ "GenSigStartValue" SG_ 1025 NM_Sleep_Ack 1;
BA_ "RID" SG_ 1025 NM_Sleep_Ack "9629";
BA_ "FlexKomComment" SG_ 1025 NM_Sleep_Ind "Network management state";
BA_ "FlexKomIsMotorola" SG_ 1025 NM_Sleep_Ind 1;
BA_ "FlexKomSID" SG_ 1025 NM_Sleep_Ind 472;
BA_ "FlexKomSigLaenge" SG_ 1025 NM_Sleep_Ind 32;
BA_ "FlexKomSigName" SG_ 1025 NM_Sleep_Ind "NM";
BA_ "FlexKomSigStartPos" SG_ 1025 NM_Sleep_Ind 7;
BA_ "FlexKomSigStartValue" SG_ 1025 NM_Sleep_Ind "FFFFFFFFh";
BA_ "GenSigSendType" SG_ 1025 NM_Sleep_Ind 1;
BA_ "GenSigSNA" SG_ 1025 NM_Sleep_Ind "1h";
BA_ "GenSigStartValue" SG_ 1025 NM_Sleep_Ind 1;
BA_ "RID" SG_ 1025 NM_Sleep_Ind "9630";
BA_ "FlexKomComment" SG_ 1025 NM_Successor "Network management state";
BA_ "FlexKomIsMotorola" SG_ 1025 NM_Successor 1;
BA_ "FlexKomSID" SG_ 1025 NM_Successor 472;
BA_ "FlexKomSigLaenge" SG_ 1025 NM_Successor 32;
BA_ "FlexKomSigName" SG_ 1025 NM_Successor "NM";
BA_ "FlexKomSigStartPos" SG_ 1025 NM_Successor 7;
BA_ "FlexKomSigStartValue" SG_ 1025 NM_Successor "FFFFFFFFh";
BA_ "GenSigSendType" SG_ 1025 NM_Successor 1;
BA_ "GenSigSNA" SG_ 1025 NM_Successor "FFh";
BA_ "GenSigStartValue" SG_ 1025 NM_Successor 255;
BA_ "RID" SG_ 1025 NM_Successor "9631";
BA_ "FlexKomComment" SG_ 1025 NM_Ud_Launch "Network management state";
BA_ "FlexKomIsMotorola" SG_ 1025 NM_Ud_Launch 1;
BA_ "FlexKomSID" SG_ 1025 NM_Ud_Launch 472;
BA_ "FlexKomSigLaenge" SG_ 1025 NM_Ud_Launch 32;
BA_ "FlexKomSigName" SG_ 1025 NM_Ud_Launch "NM";
BA_ "FlexKomSigStartPos" SG_ 1025 NM_Ud_Launch 7;
BA_ "FlexKomSigStartValue" SG_ 1025 NM_Ud_Launch "FFFFFFFFh";
BA_ "GenSigSendType" SG_ 1025 NM_Ud_Launch 1;
BA_ "GenSigSNA" SG_ 1025 NM_Ud_Launch "3Fh";
BA_ "GenSigStartValue" SG_ 1025 NM_Ud_Launch 63;
BA_ "RID" SG_ 1025 NM_Ud_Launch "9632";
BA_ "FlexKomComment" SG_ 1025 NM_Ud_Srv "Network management state";
BA_ "FlexKomIsMotorola" SG_ 1025 NM_Ud_Srv 1;
BA_ "FlexKomSID" SG_ 1025 NM_Ud_Srv 472;
BA_ "FlexKomSigLaenge" SG_ 1025 NM_Ud_Srv 32;
BA_ "FlexKomSigName" SG_ 1025 NM_Ud_Srv "NM";
BA_ "FlexKomSigStartPos" SG_ 1025 NM_Ud_Srv 7;
BA_ "FlexKomSigStartValue" SG_ 1025 NM_Ud_Srv "FFFFFFFFh";
BA_ "GenSigSendType" SG_ 1025 NM_Ud_Srv 1;
BA_ "GenSigSNA" SG_ 1025 NM_Ud_Srv "FFh";
BA_ "GenSigStartValue" SG_ 1025 NM_Ud_Srv 255;
BA_ "RID" SG_ 1025 NM_Ud_Srv "9633";
BA_ "FlexKomComment" SG_ 1025 Nw_Id "Network identification no.";
BA_ "FlexKomIsMotorola" SG_ 1025 Nw_Id 1;
BA_ "FlexKomSID" SG_ 1025 Nw_Id 535;
BA_ "FlexKomSigLaenge" SG_ 1025 Nw_Id 8;
BA_ "FlexKomSigName" SG_ 1025 Nw_Id "Nw_Id";
BA_ "FlexKomSigStartPos" SG_ 1025 Nw_Id 63;
BA_ "FlexKomSigStartValue" SG_ 1025 Nw_Id "FFh";
BA_ "GenSigSendType" SG_ 1025 Nw_Id 1;
BA_ "GenSigSNA" SG_ 1025 Nw_Id "FFh";
BA_ "GenSigStartValue" SG_ 1025 Nw_Id 255;
BA_ "RID" SG_ 1025 Nw_Id "9634";
BA_ "FlexKomComment" SG_ 1025 WakeupCnt "Mode 2 of NM_Ud_Srv";
BA_ "FlexKomIsMotorola" SG_ 1025 WakeupCnt 1;
BA_ "FlexKomSID" SG_ 1025 WakeupCnt 474;
BA_ "FlexKomSigLaenge" SG_ 1025 WakeupCnt 24;
BA_ "FlexKomSigName" SG_ 1025 WakeupCnt "Wakeup_CBC";
BA_ "FlexKomSigStartPos" SG_ 1025 WakeupCnt 39;
BA_ "FlexKomSigStartValue" SG_ 1025 WakeupCnt "FFFF00h";
BA_ "GenSigSendType" SG_ 1025 WakeupCnt 1;
BA_ "GenSigSNA" SG_ 1025 WakeupCnt "FFh";
BA_ "GenSigStartValue" SG_ 1025 WakeupCnt 255;
BA_ "RID" SG_ 1025 WakeupCnt "9635";
BA_ "FlexKomComment" SG_ 1025 WakeupRsn_CBC "Mode 2 of NM_Ud_Srv";
BA_ "FlexKomIsMotorola" SG_ 1025 WakeupRsn_CBC 1;
BA_ "FlexKomSID" SG_ 1025 WakeupRsn_CBC 474;
BA_ "FlexKomSigLaenge" SG_ 1025 WakeupRsn_CBC 24;
BA_ "FlexKomSigName" SG_ 1025 WakeupRsn_CBC "Wakeup_CBC";
BA_ "FlexKomSigStartPos" SG_ 1025 WakeupRsn_CBC 39;
BA_ "FlexKomSigStartValue" SG_ 1025 WakeupRsn_CBC "FFFF00h";
BA_ "GenSigSendType" SG_ 1025 WakeupRsn_CBC 1;
BA_ "GenSigSNA" SG_ 1025 WakeupRsn_CBC "FFh";
BA_ "GenSigStartValue" SG_ 1025 WakeupRsn_CBC 255;
BA_ "RID" SG_ 1025 WakeupRsn_CBC "9636";
BA_ "FlexKomComment" SG_ 1083 Awake_Diag_Actv "Mode 15 of NM_Ud_Srv";
BA_ "FlexKomIsMotorola" SG_ 1083 Awake_Diag_Actv 1;
BA_ "FlexKomSID" SG_ 1083 Awake_Diag_Actv 2196;
BA_ "FlexKomSigLaenge" SG_ 1083 Awake_Diag_Actv 24;
BA_ "FlexKomSigName" SG_ 1083 Awake_Diag_Actv "Awake_EBCM";
BA_ "FlexKomSigStartPos" SG_ 1083 Awake_Diag_Actv 39;
BA_ "FlexKomSigStartValue" SG_ 1083 Awake_Diag_Actv "000000h";
BA_ "GenSigSendType" SG_ 1083 Awake_Diag_Actv 1;
BA_ "GenSigSNA" SG_ 1083 Awake_Diag_Actv "0h";
BA_ "RID" SG_ 1083 Awake_Diag_Actv "9637";
BA_ "FlexKomComment" SG_ 1083 Awake_NwSt "Mode 15 of NM_Ud_Srv";
BA_ "FlexKomIsMotorola" SG_ 1083 Awake_NwSt 1;
BA_ "FlexKomSID" SG_ 1083 Awake_NwSt 2196;
BA_ "FlexKomSigLaenge" SG_ 1083 Awake_NwSt 24;
BA_ "FlexKomSigName" SG_ 1083 Awake_NwSt "Awake_EBCM";
BA_ "FlexKomSigStartPos" SG_ 1083 Awake_NwSt 39;
BA_ "FlexKomSigStartValue" SG_ 1083 Awake_NwSt "000000h";
BA_ "GenSigSendType" SG_ 1083 Awake_NwSt 1;
BA_ "GenSigSNA" SG_ 1083 Awake_NwSt "0h";
BA_ "RID" SG_ 1083 Awake_NwSt "9638";
BA_ "FlexKomComment" SG_ 1083 NM_Mode "Network management state";
BA_ "FlexKomIsMotorola" SG_ 1083 NM_Mode 1;
BA_ "FlexKomSID" SG_ 1083 NM_Mode 472;
BA_ "FlexKomSigLaenge" SG_ 1083 NM_Mode 32;
BA_ "FlexKomSigName" SG_ 1083 NM_Mode "NM";
BA_ "FlexKomSigStartPos" SG_ 1083 NM_Mode 7;
BA_ "FlexKomSigStartValue" SG_ 1083 NM_Mode "FFFFFFFFh";
BA_ "GenSigSendType" SG_ 1083 NM_Mode 1;
BA_ "GenSigSNA" SG_ 1083 NM_Mode "FFh";
BA_ "GenSigStartValue" SG_ 1083 NM_Mode 255;
BA_ "RID" SG_ 1083 NM_Mode "9639";
BA_ "FlexKomComment" SG_ 1083 NM_Sleep_Ack "Network management state";
BA_ "FlexKomIsMotorola" SG_ 1083 NM_Sleep_Ack 1;
BA_ "FlexKomSID" SG_ 1083 NM_Sleep_Ack 472;
BA_ "FlexKomSigLaenge" SG_ 1083 NM_Sleep_Ack 32;
BA_ "FlexKomSigName" SG_ 1083 NM_Sleep_Ack "NM";
BA_ "FlexKomSigStartPos" SG_ 1083 NM_Sleep_Ack 7;
BA_ "FlexKomSigStartValue" SG_ 1083 NM_Sleep_Ack "FFFFFFFFh";
BA_ "GenSigSendType" SG_ 1083 NM_Sleep_Ack 1;
BA_ "GenSigSNA" SG_ 1083 NM_Sleep_Ack "1h";
BA_ "GenSigStartValue" SG_ 1083 NM_Sleep_Ack 1;
BA_ "RID" SG_ 1083 NM_Sleep_Ack "9640";
BA_ "FlexKomComment" SG_ 1083 NM_Sleep_Ind "Network management state";
BA_ "FlexKomIsMotorola" SG_ 1083 NM_Sleep_Ind 1;
BA_ "FlexKomSID" SG_ 1083 NM_Sleep_Ind 472;
BA_ "FlexKomSigLaenge" SG_ 1083 NM_Sleep_Ind 32;
BA_ "FlexKomSigName" SG_ 1083 NM_Sleep_Ind "NM";
BA_ "FlexKomSigStartPos" SG_ 1083 NM_Sleep_Ind 7;
BA_ "FlexKomSigStartValue" SG_ 1083 NM_Sleep_Ind "FFFFFFFFh";
BA_ "GenSigSendType" SG_ 1083 NM_Sleep_Ind 1;
BA_ "GenSigSNA" SG_ 1083 NM_Sleep_Ind "1h";
BA_ "GenSigStartValue" SG_ 1083 NM_Sleep_Ind 1;
BA_ "RID" SG_ 1083 NM_Sleep_Ind "9641";
BA_ "FlexKomComment" SG_ 1083 NM_Successor "Network management state";
BA_ "FlexKomIsMotorola" SG_ 1083 NM_Successor 1;
BA_ "FlexKomSID" SG_ 1083 NM_Successor 472;
BA_ "FlexKomSigLaenge" SG_ 1083 NM_Successor 32;
BA_ "FlexKomSigName" SG_ 1083 NM_Successor "NM";
BA_ "FlexKomSigStartPos" SG_ 1083 NM_Successor 7;
BA_ "FlexKomSigStartValue" SG_ 1083 NM_Successor "FFFFFFFFh";
BA_ "GenSigSendType" SG_ 1083 NM_Successor 1;
BA_ "GenSigSNA" SG_ 1083 NM_Successor "FFh";
BA_ "GenSigStartValue" SG_ 1083 NM_Successor 255;
BA_ "RID" SG_ 1083 NM_Successor "9642";
BA_ "FlexKomComment" SG_ 1083 NM_Ud_Launch "Network management state";
BA_ "FlexKomIsMotorola" SG_ 1083 NM_Ud_Launch 1;
BA_ "FlexKomSID" SG_ 1083 NM_Ud_Launch 472;
BA_ "FlexKomSigLaenge" SG_ 1083 NM_Ud_Launch 32;
BA_ "FlexKomSigName" SG_ 1083 NM_Ud_Launch "NM";
BA_ "FlexKomSigStartPos" SG_ 1083 NM_Ud_Launch 7;
BA_ "FlexKomSigStartValue" SG_ 1083 NM_Ud_Launch "FFFFFFFFh";
BA_ "GenSigSendType" SG_ 1083 NM_Ud_Launch 1;
BA_ "GenSigSNA" SG_ 1083 NM_Ud_Launch "3Fh";
BA_ "GenSigStartValue" SG_ 1083 NM_Ud_Launch 63;
BA_ "RID" SG_ 1083 NM_Ud_Launch "9643";
BA_ "FlexKomComment" SG_ 1083 NM_Ud_Srv "Network management state";
BA_ "FlexKomIsMotorola" SG_ 1083 NM_Ud_Srv 1;
BA_ "FlexKomSID" SG_ 1083 NM_Ud_Srv 472;
BA_ "FlexKomSigLaenge" SG_ 1083 NM_Ud_Srv 32;
BA_ "FlexKomSigName" SG_ 1083 NM_Ud_Srv "NM";
BA_ "FlexKomSigStartPos" SG_ 1083 NM_Ud_Srv 7;
BA_ "FlexKomSigStartValue" SG_ 1083 NM_Ud_Srv "FFFFFFFFh";
BA_ "GenSigSendType" SG_ 1083 NM_Ud_Srv 1;
BA_ "GenSigSNA" SG_ 1083 NM_Ud_Srv "FFh";
BA_ "GenSigStartValue" SG_ 1083 NM_Ud_Srv 255;
BA_ "RID" SG_ 1083 NM_Ud_Srv "9644";
BA_ "FlexKomComment" SG_ 1083 Nw_Id "Network identification no.";
BA_ "FlexKomIsMotorola" SG_ 1083 Nw_Id 1;
BA_ "FlexKomSID" SG_ 1083 Nw_Id 535;
BA_ "FlexKomSigLaenge" SG_ 1083 Nw_Id 8;
BA_ "FlexKomSigName" SG_ 1083 Nw_Id "Nw_Id";
BA_ "FlexKomSigStartPos" SG_ 1083 Nw_Id 63;
BA_ "FlexKomSigStartValue" SG_ 1083 Nw_Id "FFh";
BA_ "GenSigSendType" SG_ 1083 Nw_Id 1;
BA_ "GenSigSNA" SG_ 1083 Nw_Id "FFh";
BA_ "GenSigStartValue" SG_ 1083 Nw_Id 255;
BA_ "RID" SG_ 1083 Nw_Id "9645";
BA_ "FlexKomComment" SG_ 1083 WakeupCnt "Mode 2 of NM_Ud_Srv";
BA_ "FlexKomIsMotorola" SG_ 1083 WakeupCnt 1;
BA_ "FlexKomSID" SG_ 1083 WakeupCnt 2197;
BA_ "FlexKomSigLaenge" SG_ 1083 WakeupCnt 24;
BA_ "FlexKomSigName" SG_ 1083 WakeupCnt "Wakeup_EBCM";
BA_ "FlexKomSigStartPos" SG_ 1083 WakeupCnt 39;
BA_ "FlexKomSigStartValue" SG_ 1083 WakeupCnt "FFFF00h";
BA_ "GenSigSendType" SG_ 1083 WakeupCnt 1;
BA_ "GenSigSNA" SG_ 1083 WakeupCnt "FFh";
BA_ "GenSigStartValue" SG_ 1083 WakeupCnt 255;
BA_ "RID" SG_ 1083 WakeupCnt "9646";
BA_ "FlexKomComment" SG_ 1083 WakeupRsn_EBCM "Mode 2 of NM_Ud_Srv";
BA_ "FlexKomIsMotorola" SG_ 1083 WakeupRsn_EBCM 1;
BA_ "FlexKomSID" SG_ 1083 WakeupRsn_EBCM 2197;
BA_ "FlexKomSigLaenge" SG_ 1083 WakeupRsn_EBCM 24;
BA_ "FlexKomSigName" SG_ 1083 WakeupRsn_EBCM "Wakeup_EBCM";
BA_ "FlexKomSigStartPos" SG_ 1083 WakeupRsn_EBCM 39;
BA_ "FlexKomSigStartValue" SG_ 1083 WakeupRsn_EBCM "FFFF00h";
BA_ "GenSigSendType" SG_ 1083 WakeupRsn_EBCM 1;
BA_ "GenSigSNA" SG_ 1083 WakeupRsn_EBCM "FFh";
BA_ "GenSigStartValue" SG_ 1083 WakeupRsn_EBCM 255;
BA_ "RID" SG_ 1083 WakeupRsn_EBCM "9647";
BA_ "FlexKomComment" SG_ 1050 Awake_Diag_Actv "Mode 15 of NM_Ud_Srv";
BA_ "FlexKomIsMotorola" SG_ 1050 Awake_Diag_Actv 1;
BA_ "FlexKomSID" SG_ 1050 Awake_Diag_Actv 1274;
BA_ "FlexKomSigLaenge" SG_ 1050 Awake_Diag_Actv 24;
BA_ "FlexKomSigName" SG_ 1050 Awake_Diag_Actv "Awake_EPS";
BA_ "FlexKomSigStartPos" SG_ 1050 Awake_Diag_Actv 39;
BA_ "FlexKomSigStartValue" SG_ 1050 Awake_Diag_Actv "000000h";
BA_ "GenSigSendType" SG_ 1050 Awake_Diag_Actv 1;
BA_ "GenSigSNA" SG_ 1050 Awake_Diag_Actv "0h";
BA_ "RID" SG_ 1050 Awake_Diag_Actv "9648";
BA_ "FlexKomComment" SG_ 1050 Awake_EngRPM_high "Mode 15 of NM_Ud_Srv";
BA_ "FlexKomIsMotorola" SG_ 1050 Awake_EngRPM_high 1;
BA_ "FlexKomSID" SG_ 1050 Awake_EngRPM_high 1274;
BA_ "FlexKomSigLaenge" SG_ 1050 Awake_EngRPM_high 24;
BA_ "FlexKomSigName" SG_ 1050 Awake_EngRPM_high "Awake_EPS";
BA_ "FlexKomSigStartPos" SG_ 1050 Awake_EngRPM_high 39;
BA_ "FlexKomSigStartValue" SG_ 1050 Awake_EngRPM_high "000000h";
BA_ "GenSigSendType" SG_ 1050 Awake_EngRPM_high 1;
BA_ "GenSigSNA" SG_ 1050 Awake_EngRPM_high "0h";
BA_ "RID" SG_ 1050 Awake_EngRPM_high "9649";
BA_ "FlexKomComment" SG_ 1050 Awake_IgnHigh "Mode 15 of NM_Ud_Srv";
BA_ "FlexKomIsMotorola" SG_ 1050 Awake_IgnHigh 1;
BA_ "FlexKomSID" SG_ 1050 Awake_IgnHigh 1274;
BA_ "FlexKomSigLaenge" SG_ 1050 Awake_IgnHigh 24;
BA_ "FlexKomSigName" SG_ 1050 Awake_IgnHigh "Awake_EPS";
BA_ "FlexKomSigStartPos" SG_ 1050 Awake_IgnHigh 39;
BA_ "FlexKomSigStartValue" SG_ 1050 Awake_IgnHigh "000000h";
BA_ "GenSigSendType" SG_ 1050 Awake_IgnHigh 1;
BA_ "GenSigSNA" SG_ 1050 Awake_IgnHigh "0h";
BA_ "RID" SG_ 1050 Awake_IgnHigh "9650";
BA_ "FlexKomComment" SG_ 1050 Awake_NwSt "Mode 15 of NM_Ud_Srv";
BA_ "FlexKomIsMotorola" SG_ 1050 Awake_NwSt 1;
BA_ "FlexKomSID" SG_ 1050 Awake_NwSt 1274;
BA_ "FlexKomSigLaenge" SG_ 1050 Awake_NwSt 24;
BA_ "FlexKomSigName" SG_ 1050 Awake_NwSt "Awake_EPS";
BA_ "FlexKomSigStartPos" SG_ 1050 Awake_NwSt 39;
BA_ "FlexKomSigStartValue" SG_ 1050 Awake_NwSt "000000h";
BA_ "GenSigSendType" SG_ 1050 Awake_NwSt 1;
BA_ "GenSigSNA" SG_ 1050 Awake_NwSt "0h";
BA_ "RID" SG_ 1050 Awake_NwSt "9651";
BA_ "FlexKomComment" SG_ 1050 Awake_Rampout "Mode 15 of NM_Ud_Srv";
BA_ "FlexKomIsMotorola" SG_ 1050 Awake_Rampout 1;
BA_ "FlexKomSID" SG_ 1050 Awake_Rampout 1274;
BA_ "FlexKomSigLaenge" SG_ 1050 Awake_Rampout 24;
BA_ "FlexKomSigName" SG_ 1050 Awake_Rampout "Awake_EPS";
BA_ "FlexKomSigStartPos" SG_ 1050 Awake_Rampout 39;
BA_ "FlexKomSigStartValue" SG_ 1050 Awake_Rampout "000000h";
BA_ "GenSigSendType" SG_ 1050 Awake_Rampout 1;
BA_ "GenSigSNA" SG_ 1050 Awake_Rampout "0h";
BA_ "RID" SG_ 1050 Awake_Rampout "9652";
BA_ "FlexKomComment" SG_ 1050 Awake_VSS_high "Mode 15 of NM_Ud_Srv";
BA_ "FlexKomIsMotorola" SG_ 1050 Awake_VSS_high 1;
BA_ "FlexKomSID" SG_ 1050 Awake_VSS_high 1274;
BA_ "FlexKomSigLaenge" SG_ 1050 Awake_VSS_high 24;
BA_ "FlexKomSigName" SG_ 1050 Awake_VSS_high "Awake_EPS";
BA_ "FlexKomSigStartPos" SG_ 1050 Awake_VSS_high 39;
BA_ "FlexKomSigStartValue" SG_ 1050 Awake_VSS_high "000000h";
BA_ "GenSigSendType" SG_ 1050 Awake_VSS_high 1;
BA_ "GenSigSNA" SG_ 1050 Awake_VSS_high "0h";
BA_ "RID" SG_ 1050 Awake_VSS_high "9653";
BA_ "FlexKomComment" SG_ 1050 NM_Mode "Network management state";
BA_ "FlexKomIsMotorola" SG_ 1050 NM_Mode 1;
BA_ "FlexKomSID" SG_ 1050 NM_Mode 472;
BA_ "FlexKomSigLaenge" SG_ 1050 NM_Mode 32;
BA_ "FlexKomSigName" SG_ 1050 NM_Mode "NM";
BA_ "FlexKomSigStartPos" SG_ 1050 NM_Mode 7;
BA_ "FlexKomSigStartValue" SG_ 1050 NM_Mode "FFFFFFFFh";
BA_ "GenSigSendType" SG_ 1050 NM_Mode 1;
BA_ "GenSigSNA" SG_ 1050 NM_Mode "FFh";
BA_ "GenSigStartValue" SG_ 1050 NM_Mode 255;
BA_ "RID" SG_ 1050 NM_Mode "9654";
BA_ "FlexKomComment" SG_ 1050 NM_Sleep_Ack "Network management state";
BA_ "FlexKomIsMotorola" SG_ 1050 NM_Sleep_Ack 1;
BA_ "FlexKomSID" SG_ 1050 NM_Sleep_Ack 472;
BA_ "FlexKomSigLaenge" SG_ 1050 NM_Sleep_Ack 32;
BA_ "FlexKomSigName" SG_ 1050 NM_Sleep_Ack "NM";
BA_ "FlexKomSigStartPos" SG_ 1050 NM_Sleep_Ack 7;
BA_ "FlexKomSigStartValue" SG_ 1050 NM_Sleep_Ack "FFFFFFFFh";
BA_ "GenSigSendType" SG_ 1050 NM_Sleep_Ack 1;
BA_ "GenSigSNA" SG_ 1050 NM_Sleep_Ack "1h";
BA_ "GenSigStartValue" SG_ 1050 NM_Sleep_Ack 1;
BA_ "RID" SG_ 1050 NM_Sleep_Ack "9655";
BA_ "FlexKomComment" SG_ 1050 NM_Sleep_Ind "Network management state";
BA_ "FlexKomIsMotorola" SG_ 1050 NM_Sleep_Ind 1;
BA_ "FlexKomSID" SG_ 1050 NM_Sleep_Ind 472;
BA_ "FlexKomSigLaenge" SG_ 1050 NM_Sleep_Ind 32;
BA_ "FlexKomSigName" SG_ 1050 NM_Sleep_Ind "NM";
BA_ "FlexKomSigStartPos" SG_ 1050 NM_Sleep_Ind 7;
BA_ "FlexKomSigStartValue" SG_ 1050 NM_Sleep_Ind "FFFFFFFFh";
BA_ "GenSigSendType" SG_ 1050 NM_Sleep_Ind 1;
BA_ "GenSigSNA" SG_ 1050 NM_Sleep_Ind "1h";
BA_ "GenSigStartValue" SG_ 1050 NM_Sleep_Ind 1;
BA_ "RID" SG_ 1050 NM_Sleep_Ind "9656";
BA_ "FlexKomComment" SG_ 1050 NM_Successor "Network management state";
BA_ "FlexKomIsMotorola" SG_ 1050 NM_Successor 1;
BA_ "FlexKomSID" SG_ 1050 NM_Successor 472;
BA_ "FlexKomSigLaenge" SG_ 1050 NM_Successor 32;
BA_ "FlexKomSigName" SG_ 1050 NM_Successor "NM";
BA_ "FlexKomSigStartPos" SG_ 1050 NM_Successor 7;
BA_ "FlexKomSigStartValue" SG_ 1050 NM_Successor "FFFFFFFFh";
BA_ "GenSigSendType" SG_ 1050 NM_Successor 1;
BA_ "GenSigSNA" SG_ 1050 NM_Successor "FFh";
BA_ "GenSigStartValue" SG_ 1050 NM_Successor 255;
BA_ "RID" SG_ 1050 NM_Successor "9657";
BA_ "FlexKomComment" SG_ 1050 NM_Ud_Launch "Network management state";
BA_ "FlexKomIsMotorola" SG_ 1050 NM_Ud_Launch 1;
BA_ "FlexKomSID" SG_ 1050 NM_Ud_Launch 472;
BA_ "FlexKomSigLaenge" SG_ 1050 NM_Ud_Launch 32;
BA_ "FlexKomSigName" SG_ 1050 NM_Ud_Launch "NM";
BA_ "FlexKomSigStartPos" SG_ 1050 NM_Ud_Launch 7;
BA_ "FlexKomSigStartValue" SG_ 1050 NM_Ud_Launch "FFFFFFFFh";
BA_ "GenSigSendType" SG_ 1050 NM_Ud_Launch 1;
BA_ "GenSigSNA" SG_ 1050 NM_Ud_Launch "3Fh";
BA_ "GenSigStartValue" SG_ 1050 NM_Ud_Launch 63;
BA_ "RID" SG_ 1050 NM_Ud_Launch "9658";
BA_ "FlexKomComment" SG_ 1050 NM_Ud_Srv "Network management state";
BA_ "FlexKomIsMotorola" SG_ 1050 NM_Ud_Srv 1;
BA_ "FlexKomSID" SG_ 1050 NM_Ud_Srv 472;
BA_ "FlexKomSigLaenge" SG_ 1050 NM_Ud_Srv 32;
BA_ "FlexKomSigName" SG_ 1050 NM_Ud_Srv "NM";
BA_ "FlexKomSigStartPos" SG_ 1050 NM_Ud_Srv 7;
BA_ "FlexKomSigStartValue" SG_ 1050 NM_Ud_Srv "FFFFFFFFh";
BA_ "GenSigSendType" SG_ 1050 NM_Ud_Srv 1;
BA_ "GenSigSNA" SG_ 1050 NM_Ud_Srv "FFh";
BA_ "GenSigStartValue" SG_ 1050 NM_Ud_Srv 255;
BA_ "RID" SG_ 1050 NM_Ud_Srv "9659";
BA_ "FlexKomComment" SG_ 1050 Nw_Id "Network identification no.";
BA_ "FlexKomIsMotorola" SG_ 1050 Nw_Id 1;
BA_ "FlexKomSID" SG_ 1050 Nw_Id 535;
BA_ "FlexKomSigLaenge" SG_ 1050 Nw_Id 8;
BA_ "FlexKomSigName" SG_ 1050 Nw_Id "Nw_Id";
BA_ "FlexKomSigStartPos" SG_ 1050 Nw_Id 63;
BA_ "FlexKomSigStartValue" SG_ 1050 Nw_Id "FFh";
BA_ "GenSigSendType" SG_ 1050 Nw_Id 1;
BA_ "GenSigSNA" SG_ 1050 Nw_Id "FFh";
BA_ "GenSigStartValue" SG_ 1050 Nw_Id 255;
BA_ "RID" SG_ 1050 Nw_Id "9660";
BA_ "FlexKomComment" SG_ 1050 WakeupCnt "Mode 2 of NM_Ud_Srv";
BA_ "FlexKomIsMotorola" SG_ 1050 WakeupCnt 1;
BA_ "FlexKomSID" SG_ 1050 WakeupCnt 1273;
BA_ "FlexKomSigLaenge" SG_ 1050 WakeupCnt 24;
BA_ "FlexKomSigName" SG_ 1050 WakeupCnt "Wakeup_EPS";
BA_ "FlexKomSigStartPos" SG_ 1050 WakeupCnt 39;
BA_ "FlexKomSigStartValue" SG_ 1050 WakeupCnt "FFFF00h";
BA_ "GenSigSendType" SG_ 1050 WakeupCnt 1;
BA_ "GenSigSNA" SG_ 1050 WakeupCnt "FFh";
BA_ "GenSigStartValue" SG_ 1050 WakeupCnt 255;
BA_ "RID" SG_ 1050 WakeupCnt "9661";
BA_ "FlexKomComment" SG_ 1050 WakeupRsn_EPS "Mode 2 of NM_Ud_Srv";
BA_ "FlexKomIsMotorola" SG_ 1050 WakeupRsn_EPS 1;
BA_ "FlexKomSID" SG_ 1050 WakeupRsn_EPS 1273;
BA_ "FlexKomSigLaenge" SG_ 1050 WakeupRsn_EPS 24;
BA_ "FlexKomSigName" SG_ 1050 WakeupRsn_EPS "Wakeup_EPS";
BA_ "FlexKomSigStartPos" SG_ 1050 WakeupRsn_EPS 39;
BA_ "FlexKomSigStartValue" SG_ 1050 WakeupRsn_EPS "FFFF00h";
BA_ "GenSigSendType" SG_ 1050 WakeupRsn_EPS 1;
BA_ "GenSigSNA" SG_ 1050 WakeupRsn_EPS "FFh";
BA_ "GenSigStartValue" SG_ 1050 WakeupRsn_EPS 255;
BA_ "RID" SG_ 1050 WakeupRsn_EPS "9662";
BA_ "FlexKomComment" SG_ 1031 Awake_Brake_Pedal_Pressed "Mode 15 of NM_Ud_Srv";
BA_ "FlexKomIsMotorola" SG_ 1031 Awake_Brake_Pedal_Pressed 1;
BA_ "FlexKomSID" SG_ 1031 Awake_Brake_Pedal_Pressed 961;
BA_ "FlexKomSigLaenge" SG_ 1031 Awake_Brake_Pedal_Pressed 24;
BA_ "FlexKomSigName" SG_ 1031 Awake_Brake_Pedal_Pressed "Awake_ESC";
BA_ "FlexKomSigStartPos" SG_ 1031 Awake_Brake_Pedal_Pressed 39;
BA_ "FlexKomSigStartValue" SG_ 1031 Awake_Brake_Pedal_Pressed "000000h";
BA_ "GenSigSendType" SG_ 1031 Awake_Brake_Pedal_Pressed 1;
BA_ "GenSigSNA" SG_ 1031 Awake_Brake_Pedal_Pressed "0h";
BA_ "RID" SG_ 1031 Awake_Brake_Pedal_Pressed "9663";
BA_ "FlexKomComment" SG_ 1031 Awake_Diag_Actv "Mode 15 of NM_Ud_Srv";
BA_ "FlexKomIsMotorola" SG_ 1031 Awake_Diag_Actv 1;
BA_ "FlexKomSID" SG_ 1031 Awake_Diag_Actv 961;
BA_ "FlexKomSigLaenge" SG_ 1031 Awake_Diag_Actv 24;
BA_ "FlexKomSigName" SG_ 1031 Awake_Diag_Actv "Awake_ESC";
BA_ "FlexKomSigStartPos" SG_ 1031 Awake_Diag_Actv 39;
BA_ "FlexKomSigStartValue" SG_ 1031 Awake_Diag_Actv "000000h";
BA_ "GenSigSendType" SG_ 1031 Awake_Diag_Actv 1;
BA_ "GenSigSNA" SG_ 1031 Awake_Diag_Actv "0h";
BA_ "RID" SG_ 1031 Awake_Diag_Actv "9664";
BA_ "FlexKomComment" SG_ 1031 Awake_EPB_Switch_Wakeup "Mode 15 of NM_Ud_Srv";
BA_ "FlexKomIsMotorola" SG_ 1031 Awake_EPB_Switch_Wakeup 1;
BA_ "FlexKomSID" SG_ 1031 Awake_EPB_Switch_Wakeup 961;
BA_ "FlexKomSigLaenge" SG_ 1031 Awake_EPB_Switch_Wakeup 24;
BA_ "FlexKomSigName" SG_ 1031 Awake_EPB_Switch_Wakeup "Awake_ESC";
BA_ "FlexKomSigStartPos" SG_ 1031 Awake_EPB_Switch_Wakeup 39;
BA_ "FlexKomSigStartValue" SG_ 1031 Awake_EPB_Switch_Wakeup "000000h";
BA_ "GenSigSendType" SG_ 1031 Awake_EPB_Switch_Wakeup 1;
BA_ "GenSigSNA" SG_ 1031 Awake_EPB_Switch_Wakeup "0h";
BA_ "RID" SG_ 1031 Awake_EPB_Switch_Wakeup "9665";
BA_ "FlexKomComment" SG_ 1031 Awake_Hardwire_Ignition "Mode 15 of NM_Ud_Srv";
BA_ "FlexKomIsMotorola" SG_ 1031 Awake_Hardwire_Ignition 1;
BA_ "FlexKomSID" SG_ 1031 Awake_Hardwire_Ignition 961;
BA_ "FlexKomSigLaenge" SG_ 1031 Awake_Hardwire_Ignition 24;
BA_ "FlexKomSigName" SG_ 1031 Awake_Hardwire_Ignition "Awake_ESC";
BA_ "FlexKomSigStartPos" SG_ 1031 Awake_Hardwire_Ignition 39;
BA_ "FlexKomSigStartValue" SG_ 1031 Awake_Hardwire_Ignition "000000h";
BA_ "GenSigSendType" SG_ 1031 Awake_Hardwire_Ignition 1;
BA_ "GenSigSNA" SG_ 1031 Awake_Hardwire_Ignition "0h";
BA_ "RID" SG_ 1031 Awake_Hardwire_Ignition "9666";
BA_ "FlexKomComment" SG_ 1031 Awake_NwSt "Mode 15 of NM_Ud_Srv";
BA_ "FlexKomIsMotorola" SG_ 1031 Awake_NwSt 1;
BA_ "FlexKomSID" SG_ 1031 Awake_NwSt 961;
BA_ "FlexKomSigLaenge" SG_ 1031 Awake_NwSt 24;
BA_ "FlexKomSigName" SG_ 1031 Awake_NwSt "Awake_ESC";
BA_ "FlexKomSigStartPos" SG_ 1031 Awake_NwSt 39;
BA_ "FlexKomSigStartValue" SG_ 1031 Awake_NwSt "000000h";
BA_ "GenSigSendType" SG_ 1031 Awake_NwSt 1;
BA_ "GenSigSNA" SG_ 1031 Awake_NwSt "0h";
BA_ "RID" SG_ 1031 Awake_NwSt "9667";
BA_ "FlexKomComment" SG_ 1031 Awake_Vehicle_Speed "Mode 15 of NM_Ud_Srv";
BA_ "FlexKomIsMotorola" SG_ 1031 Awake_Vehicle_Speed 1;
BA_ "FlexKomSID" SG_ 1031 Awake_Vehicle_Speed 961;
BA_ "FlexKomSigLaenge" SG_ 1031 Awake_Vehicle_Speed 24;
BA_ "FlexKomSigName" SG_ 1031 Awake_Vehicle_Speed "Awake_ESC";
BA_ "FlexKomSigStartPos" SG_ 1031 Awake_Vehicle_Speed 39;
BA_ "FlexKomSigStartValue" SG_ 1031 Awake_Vehicle_Speed "000000h";
BA_ "GenSigSendType" SG_ 1031 Awake_Vehicle_Speed 1;
BA_ "GenSigSNA" SG_ 1031 Awake_Vehicle_Speed "0h";
BA_ "RID" SG_ 1031 Awake_Vehicle_Speed "9668";
BA_ "FlexKomComment" SG_ 1031 NM_Mode "Network management state";
BA_ "FlexKomIsMotorola" SG_ 1031 NM_Mode 1;
BA_ "FlexKomSID" SG_ 1031 NM_Mode 472;
BA_ "FlexKomSigLaenge" SG_ 1031 NM_Mode 32;
BA_ "FlexKomSigName" SG_ 1031 NM_Mode "NM";
BA_ "FlexKomSigStartPos" SG_ 1031 NM_Mode 7;
BA_ "FlexKomSigStartValue" SG_ 1031 NM_Mode "FFFFFFFFh";
BA_ "GenSigSendType" SG_ 1031 NM_Mode 1;
BA_ "GenSigSNA" SG_ 1031 NM_Mode "FFh";
BA_ "GenSigStartValue" SG_ 1031 NM_Mode 255;
BA_ "RID" SG_ 1031 NM_Mode "9669";
BA_ "FlexKomComment" SG_ 1031 NM_Sleep_Ack "Network management state";
BA_ "FlexKomIsMotorola" SG_ 1031 NM_Sleep_Ack 1;
BA_ "FlexKomSID" SG_ 1031 NM_Sleep_Ack 472;
BA_ "FlexKomSigLaenge" SG_ 1031 NM_Sleep_Ack 32;
BA_ "FlexKomSigName" SG_ 1031 NM_Sleep_Ack "NM";
BA_ "FlexKomSigStartPos" SG_ 1031 NM_Sleep_Ack 7;
BA_ "FlexKomSigStartValue" SG_ 1031 NM_Sleep_Ack "FFFFFFFFh";
BA_ "GenSigSendType" SG_ 1031 NM_Sleep_Ack 1;
BA_ "GenSigSNA" SG_ 1031 NM_Sleep_Ack "1h";
BA_ "GenSigStartValue" SG_ 1031 NM_Sleep_Ack 1;
BA_ "RID" SG_ 1031 NM_Sleep_Ack "9670";
BA_ "FlexKomComment" SG_ 1031 NM_Sleep_Ind "Network management state";
BA_ "FlexKomIsMotorola" SG_ 1031 NM_Sleep_Ind 1;
BA_ "FlexKomSID" SG_ 1031 NM_Sleep_Ind 472;
BA_ "FlexKomSigLaenge" SG_ 1031 NM_Sleep_Ind 32;
BA_ "FlexKomSigName" SG_ 1031 NM_Sleep_Ind "NM";
BA_ "FlexKomSigStartPos" SG_ 1031 NM_Sleep_Ind 7;
BA_ "FlexKomSigStartValue" SG_ 1031 NM_Sleep_Ind "FFFFFFFFh";
BA_ "GenSigSendType" SG_ 1031 NM_Sleep_Ind 1;
BA_ "GenSigSNA" SG_ 1031 NM_Sleep_Ind "1h";
BA_ "GenSigStartValue" SG_ 1031 NM_Sleep_Ind 1;
BA_ "RID" SG_ 1031 NM_Sleep_Ind "9671";
BA_ "FlexKomComment" SG_ 1031 NM_Successor "Network management state";
BA_ "FlexKomIsMotorola" SG_ 1031 NM_Successor 1;
BA_ "FlexKomSID" SG_ 1031 NM_Successor 472;
BA_ "FlexKomSigLaenge" SG_ 1031 NM_Successor 32;
BA_ "FlexKomSigName" SG_ 1031 NM_Successor "NM";
BA_ "FlexKomSigStartPos" SG_ 1031 NM_Successor 7;
BA_ "FlexKomSigStartValue" SG_ 1031 NM_Successor "FFFFFFFFh";
BA_ "GenSigSendType" SG_ 1031 NM_Successor 1;
BA_ "GenSigSNA" SG_ 1031 NM_Successor "FFh";
BA_ "GenSigStartValue" SG_ 1031 NM_Successor 255;
BA_ "RID" SG_ 1031 NM_Successor "9672";
BA_ "FlexKomComment" SG_ 1031 NM_Ud_Launch "Network management state";
BA_ "FlexKomIsMotorola" SG_ 1031 NM_Ud_Launch 1;
BA_ "FlexKomSID" SG_ 1031 NM_Ud_Launch 472;
BA_ "FlexKomSigLaenge" SG_ 1031 NM_Ud_Launch 32;
BA_ "FlexKomSigName" SG_ 1031 NM_Ud_Launch "NM";
BA_ "FlexKomSigStartPos" SG_ 1031 NM_Ud_Launch 7;
BA_ "FlexKomSigStartValue" SG_ 1031 NM_Ud_Launch "FFFFFFFFh";
BA_ "GenSigSendType" SG_ 1031 NM_Ud_Launch 1;
BA_ "GenSigSNA" SG_ 1031 NM_Ud_Launch "3Fh";
BA_ "GenSigStartValue" SG_ 1031 NM_Ud_Launch 63;
BA_ "RID" SG_ 1031 NM_Ud_Launch "9673";
BA_ "FlexKomComment" SG_ 1031 NM_Ud_Srv "Network management state";
BA_ "FlexKomIsMotorola" SG_ 1031 NM_Ud_Srv 1;
BA_ "FlexKomSID" SG_ 1031 NM_Ud_Srv 472;
BA_ "FlexKomSigLaenge" SG_ 1031 NM_Ud_Srv 32;
BA_ "FlexKomSigName" SG_ 1031 NM_Ud_Srv "NM";
BA_ "FlexKomSigStartPos" SG_ 1031 NM_Ud_Srv 7;
BA_ "FlexKomSigStartValue" SG_ 1031 NM_Ud_Srv "FFFFFFFFh";
BA_ "GenSigSendType" SG_ 1031 NM_Ud_Srv 1;
BA_ "GenSigSNA" SG_ 1031 NM_Ud_Srv "FFh";
BA_ "GenSigStartValue" SG_ 1031 NM_Ud_Srv 255;
BA_ "RID" SG_ 1031 NM_Ud_Srv "9674";
BA_ "FlexKomComment" SG_ 1031 Nw_Id "Network identification no.";
BA_ "FlexKomIsMotorola" SG_ 1031 Nw_Id 1;
BA_ "FlexKomSID" SG_ 1031 Nw_Id 535;
BA_ "FlexKomSigLaenge" SG_ 1031 Nw_Id 8;
BA_ "FlexKomSigName" SG_ 1031 Nw_Id "Nw_Id";
BA_ "FlexKomSigStartPos" SG_ 1031 Nw_Id 63;
BA_ "FlexKomSigStartValue" SG_ 1031 Nw_Id "FFh";
BA_ "GenSigSendType" SG_ 1031 Nw_Id 1;
BA_ "GenSigSNA" SG_ 1031 Nw_Id "FFh";
BA_ "GenSigStartValue" SG_ 1031 Nw_Id 255;
BA_ "RID" SG_ 1031 Nw_Id "9675";
BA_ "FlexKomComment" SG_ 1031 WakeupCnt "Mode 2 of NM_Ud_Srv";
BA_ "FlexKomIsMotorola" SG_ 1031 WakeupCnt 1;
BA_ "FlexKomSID" SG_ 1031 WakeupCnt 962;
BA_ "FlexKomSigLaenge" SG_ 1031 WakeupCnt 24;
BA_ "FlexKomSigName" SG_ 1031 WakeupCnt "Wakeup_ESC";
BA_ "FlexKomSigStartPos" SG_ 1031 WakeupCnt 39;
BA_ "FlexKomSigStartValue" SG_ 1031 WakeupCnt "FFFF00h";
BA_ "GenSigSendType" SG_ 1031 WakeupCnt 1;
BA_ "GenSigSNA" SG_ 1031 WakeupCnt "FFh";
BA_ "GenSigStartValue" SG_ 1031 WakeupCnt 255;
BA_ "RID" SG_ 1031 WakeupCnt "9676";
BA_ "FlexKomComment" SG_ 1031 WakeupRsn_ESC "Mode 2 of NM_Ud_Srv";
BA_ "FlexKomIsMotorola" SG_ 1031 WakeupRsn_ESC 1;
BA_ "FlexKomSID" SG_ 1031 WakeupRsn_ESC 962;
BA_ "FlexKomSigLaenge" SG_ 1031 WakeupRsn_ESC 24;
BA_ "FlexKomSigName" SG_ 1031 WakeupRsn_ESC "Wakeup_ESC";
BA_ "FlexKomSigStartPos" SG_ 1031 WakeupRsn_ESC 39;
BA_ "FlexKomSigStartValue" SG_ 1031 WakeupRsn_ESC "FFFF00h";
BA_ "GenSigSendType" SG_ 1031 WakeupRsn_ESC 1;
BA_ "GenSigSNA" SG_ 1031 WakeupRsn_ESC "FFh";
BA_ "GenSigStartValue" SG_ 1031 WakeupRsn_ESC 255;
BA_ "RID" SG_ 1031 WakeupRsn_ESC "9677";
BA_ "FlexKomComment" SG_ 1032 Awake_Diag_Actv "Mode 15 of NM_Ud_Srv";
BA_ "FlexKomIsMotorola" SG_ 1032 Awake_Diag_Actv 1;
BA_ "FlexKomSID" SG_ 1032 Awake_Diag_Actv 2343;
BA_ "FlexKomSigLaenge" SG_ 1032 Awake_Diag_Actv 24;
BA_ "FlexKomSigName" SG_ 1032 Awake_Diag_Actv "Awake_ESL";
BA_ "FlexKomSigStartPos" SG_ 1032 Awake_Diag_Actv 39;
BA_ "FlexKomSigStartValue" SG_ 1032 Awake_Diag_Actv "000000h";
BA_ "GenSigSendType" SG_ 1032 Awake_Diag_Actv 1;
BA_ "GenSigSNA" SG_ 1032 Awake_Diag_Actv "0h";
BA_ "RID" SG_ 1032 Awake_Diag_Actv "9678";
BA_ "FlexKomComment" SG_ 1032 Awake_Ign_RunStart "Mode 15 of NM_Ud_Srv";
BA_ "FlexKomIsMotorola" SG_ 1032 Awake_Ign_RunStart 1;
BA_ "FlexKomSID" SG_ 1032 Awake_Ign_RunStart 2343;
BA_ "FlexKomSigLaenge" SG_ 1032 Awake_Ign_RunStart 24;
BA_ "FlexKomSigName" SG_ 1032 Awake_Ign_RunStart "Awake_ESL";
BA_ "FlexKomSigStartPos" SG_ 1032 Awake_Ign_RunStart 39;
BA_ "FlexKomSigStartValue" SG_ 1032 Awake_Ign_RunStart "000000h";
BA_ "GenSigSendType" SG_ 1032 Awake_Ign_RunStart 1;
BA_ "GenSigSNA" SG_ 1032 Awake_Ign_RunStart "0h";
BA_ "RID" SG_ 1032 Awake_Ign_RunStart "9679";
BA_ "FlexKomComment" SG_ 1032 Awake_Lock_Unlock "Mode 15 of NM_Ud_Srv";
BA_ "FlexKomIsMotorola" SG_ 1032 Awake_Lock_Unlock 1;
BA_ "FlexKomSID" SG_ 1032 Awake_Lock_Unlock 2343;
BA_ "FlexKomSigLaenge" SG_ 1032 Awake_Lock_Unlock 24;
BA_ "FlexKomSigName" SG_ 1032 Awake_Lock_Unlock "Awake_ESL";
BA_ "FlexKomSigStartPos" SG_ 1032 Awake_Lock_Unlock 39;
BA_ "FlexKomSigStartValue" SG_ 1032 Awake_Lock_Unlock "000000h";
BA_ "GenSigSendType" SG_ 1032 Awake_Lock_Unlock 1;
BA_ "GenSigSNA" SG_ 1032 Awake_Lock_Unlock "0h";
BA_ "RID" SG_ 1032 Awake_Lock_Unlock "9680";
BA_ "FlexKomComment" SG_ 1032 Awake_NwSt "Mode 15 of NM_Ud_Srv";
BA_ "FlexKomIsMotorola" SG_ 1032 Awake_NwSt 1;
BA_ "FlexKomSID" SG_ 1032 Awake_NwSt 2343;
BA_ "FlexKomSigLaenge" SG_ 1032 Awake_NwSt 24;
BA_ "FlexKomSigName" SG_ 1032 Awake_NwSt "Awake_ESL";
BA_ "FlexKomSigStartPos" SG_ 1032 Awake_NwSt 39;
BA_ "FlexKomSigStartValue" SG_ 1032 Awake_NwSt "000000h";
BA_ "GenSigSendType" SG_ 1032 Awake_NwSt 1;
BA_ "GenSigSNA" SG_ 1032 Awake_NwSt "0h";
BA_ "RID" SG_ 1032 Awake_NwSt "9681";
BA_ "FlexKomComment" SG_ 1032 NM_Mode "Network management state";
BA_ "FlexKomIsMotorola" SG_ 1032 NM_Mode 1;
BA_ "FlexKomSID" SG_ 1032 NM_Mode 472;
BA_ "FlexKomSigLaenge" SG_ 1032 NM_Mode 32;
BA_ "FlexKomSigName" SG_ 1032 NM_Mode "NM";
BA_ "FlexKomSigStartPos" SG_ 1032 NM_Mode 7;
BA_ "FlexKomSigStartValue" SG_ 1032 NM_Mode "FFFFFFFFh";
BA_ "GenSigSendType" SG_ 1032 NM_Mode 1;
BA_ "GenSigSNA" SG_ 1032 NM_Mode "FFh";
BA_ "GenSigStartValue" SG_ 1032 NM_Mode 255;
BA_ "RID" SG_ 1032 NM_Mode "9682";
BA_ "FlexKomComment" SG_ 1032 NM_Sleep_Ack "Network management state";
BA_ "FlexKomIsMotorola" SG_ 1032 NM_Sleep_Ack 1;
BA_ "FlexKomSID" SG_ 1032 NM_Sleep_Ack 472;
BA_ "FlexKomSigLaenge" SG_ 1032 NM_Sleep_Ack 32;
BA_ "FlexKomSigName" SG_ 1032 NM_Sleep_Ack "NM";
BA_ "FlexKomSigStartPos" SG_ 1032 NM_Sleep_Ack 7;
BA_ "FlexKomSigStartValue" SG_ 1032 NM_Sleep_Ack "FFFFFFFFh";
BA_ "GenSigSendType" SG_ 1032 NM_Sleep_Ack 1;
BA_ "GenSigSNA" SG_ 1032 NM_Sleep_Ack "1h";
BA_ "GenSigStartValue" SG_ 1032 NM_Sleep_Ack 1;
BA_ "RID" SG_ 1032 NM_Sleep_Ack "9683";
BA_ "FlexKomComment" SG_ 1032 NM_Sleep_Ind "Network management state";
BA_ "FlexKomIsMotorola" SG_ 1032 NM_Sleep_Ind 1;
BA_ "FlexKomSID" SG_ 1032 NM_Sleep_Ind 472;
BA_ "FlexKomSigLaenge" SG_ 1032 NM_Sleep_Ind 32;
BA_ "FlexKomSigName" SG_ 1032 NM_Sleep_Ind "NM";
BA_ "FlexKomSigStartPos" SG_ 1032 NM_Sleep_Ind 7;
BA_ "FlexKomSigStartValue" SG_ 1032 NM_Sleep_Ind "FFFFFFFFh";
BA_ "GenSigSendType" SG_ 1032 NM_Sleep_Ind 1;
BA_ "GenSigSNA" SG_ 1032 NM_Sleep_Ind "1h";
BA_ "GenSigStartValue" SG_ 1032 NM_Sleep_Ind 1;
BA_ "RID" SG_ 1032 NM_Sleep_Ind "9684";
BA_ "FlexKomComment" SG_ 1032 NM_Successor "Network management state";
BA_ "FlexKomIsMotorola" SG_ 1032 NM_Successor 1;
BA_ "FlexKomSID" SG_ 1032 NM_Successor 472;
BA_ "FlexKomSigLaenge" SG_ 1032 NM_Successor 32;
BA_ "FlexKomSigName" SG_ 1032 NM_Successor "NM";
BA_ "FlexKomSigStartPos" SG_ 1032 NM_Successor 7;
BA_ "FlexKomSigStartValue" SG_ 1032 NM_Successor "FFFFFFFFh";
BA_ "GenSigSendType" SG_ 1032 NM_Successor 1;
BA_ "GenSigSNA" SG_ 1032 NM_Successor "FFh";
BA_ "GenSigStartValue" SG_ 1032 NM_Successor 255;
BA_ "RID" SG_ 1032 NM_Successor "9685";
BA_ "FlexKomComment" SG_ 1032 NM_Ud_Launch "Network management state";
BA_ "FlexKomIsMotorola" SG_ 1032 NM_Ud_Launch 1;
BA_ "FlexKomSID" SG_ 1032 NM_Ud_Launch 472;
BA_ "FlexKomSigLaenge" SG_ 1032 NM_Ud_Launch 32;
BA_ "FlexKomSigName" SG_ 1032 NM_Ud_Launch "NM";
BA_ "FlexKomSigStartPos" SG_ 1032 NM_Ud_Launch 7;
BA_ "FlexKomSigStartValue" SG_ 1032 NM_Ud_Launch "FFFFFFFFh";
BA_ "GenSigSendType" SG_ 1032 NM_Ud_Launch 1;
BA_ "GenSigSNA" SG_ 1032 NM_Ud_Launch "3Fh";
BA_ "GenSigStartValue" SG_ 1032 NM_Ud_Launch 63;
BA_ "RID" SG_ 1032 NM_Ud_Launch "9686";
BA_ "FlexKomComment" SG_ 1032 NM_Ud_Srv "Network management state";
BA_ "FlexKomIsMotorola" SG_ 1032 NM_Ud_Srv 1;
BA_ "FlexKomSID" SG_ 1032 NM_Ud_Srv 472;
BA_ "FlexKomSigLaenge" SG_ 1032 NM_Ud_Srv 32;
BA_ "FlexKomSigName" SG_ 1032 NM_Ud_Srv "NM";
BA_ "FlexKomSigStartPos" SG_ 1032 NM_Ud_Srv 7;
BA_ "FlexKomSigStartValue" SG_ 1032 NM_Ud_Srv "FFFFFFFFh";
BA_ "GenSigSendType" SG_ 1032 NM_Ud_Srv 1;
BA_ "GenSigSNA" SG_ 1032 NM_Ud_Srv "FFh";
BA_ "GenSigStartValue" SG_ 1032 NM_Ud_Srv 255;
BA_ "RID" SG_ 1032 NM_Ud_Srv "9687";
BA_ "FlexKomComment" SG_ 1032 Nw_Id "Network identification no.";
BA_ "FlexKomIsMotorola" SG_ 1032 Nw_Id 1;
BA_ "FlexKomSID" SG_ 1032 Nw_Id 535;
BA_ "FlexKomSigLaenge" SG_ 1032 Nw_Id 8;
BA_ "FlexKomSigName" SG_ 1032 Nw_Id "Nw_Id";
BA_ "FlexKomSigStartPos" SG_ 1032 Nw_Id 63;
BA_ "FlexKomSigStartValue" SG_ 1032 Nw_Id "FFh";
BA_ "GenSigSendType" SG_ 1032 Nw_Id 1;
BA_ "GenSigSNA" SG_ 1032 Nw_Id "FFh";
BA_ "GenSigStartValue" SG_ 1032 Nw_Id 255;
BA_ "RID" SG_ 1032 Nw_Id "9688";
BA_ "FlexKomComment" SG_ 1032 WakeupCnt "Mode 2 of NM_Ud_Srv";
BA_ "FlexKomIsMotorola" SG_ 1032 WakeupCnt 1;
BA_ "FlexKomSID" SG_ 1032 WakeupCnt 2344;
BA_ "FlexKomSigLaenge" SG_ 1032 WakeupCnt 24;
BA_ "FlexKomSigName" SG_ 1032 WakeupCnt "Wakeup_ESL";
BA_ "FlexKomSigStartPos" SG_ 1032 WakeupCnt 39;
BA_ "FlexKomSigStartValue" SG_ 1032 WakeupCnt "FFFF00h";
BA_ "GenSigSendType" SG_ 1032 WakeupCnt 1;
BA_ "GenSigSNA" SG_ 1032 WakeupCnt "FFh";
BA_ "GenSigStartValue" SG_ 1032 WakeupCnt 255;
BA_ "RID" SG_ 1032 WakeupCnt "9689";
BA_ "FlexKomComment" SG_ 1032 WakeupRsn_ESL "Mode 2 of NM_Ud_Srv";
BA_ "FlexKomIsMotorola" SG_ 1032 WakeupRsn_ESL 1;
BA_ "FlexKomSID" SG_ 1032 WakeupRsn_ESL 2344;
BA_ "FlexKomSigLaenge" SG_ 1032 WakeupRsn_ESL 24;
BA_ "FlexKomSigName" SG_ 1032 WakeupRsn_ESL "Wakeup_ESL";
BA_ "FlexKomSigStartPos" SG_ 1032 WakeupRsn_ESL 39;
BA_ "FlexKomSigStartValue" SG_ 1032 WakeupRsn_ESL "FFFF00h";
BA_ "GenSigSendType" SG_ 1032 WakeupRsn_ESL 1;
BA_ "GenSigSNA" SG_ 1032 WakeupRsn_ESL "FFh";
BA_ "GenSigStartValue" SG_ 1032 WakeupRsn_ESL 255;
BA_ "RID" SG_ 1032 WakeupRsn_ESL "9690";
BA_ "FlexKomComment" SG_ 1082 Awake_Chg_ST "Mode 15 of NM_Ud_Srv";
BA_ "FlexKomIsMotorola" SG_ 1082 Awake_Chg_ST 1;
BA_ "FlexKomSID" SG_ 1082 Awake_Chg_ST 2122;
BA_ "FlexKomSigLaenge" SG_ 1082 Awake_Chg_ST 24;
BA_ "FlexKomSigName" SG_ 1082 Awake_Chg_ST "Awake_HCP";
BA_ "FlexKomSigStartPos" SG_ 1082 Awake_Chg_ST 39;
BA_ "FlexKomSigStartValue" SG_ 1082 Awake_Chg_ST "000000h";
BA_ "GenSigSendType" SG_ 1082 Awake_Chg_ST 1;
BA_ "GenSigSNA" SG_ 1082 Awake_Chg_ST "0h";
BA_ "RID" SG_ 1082 Awake_Chg_ST "9691";
BA_ "FlexKomComment" SG_ 1082 Awake_Diag_Actv "Mode 15 of NM_Ud_Srv";
BA_ "FlexKomIsMotorola" SG_ 1082 Awake_Diag_Actv 1;
BA_ "FlexKomSID" SG_ 1082 Awake_Diag_Actv 2122;
BA_ "FlexKomSigLaenge" SG_ 1082 Awake_Diag_Actv 24;
BA_ "FlexKomSigName" SG_ 1082 Awake_Diag_Actv "Awake_HCP";
BA_ "FlexKomSigStartPos" SG_ 1082 Awake_Diag_Actv 39;
BA_ "FlexKomSigStartValue" SG_ 1082 Awake_Diag_Actv "000000h";
BA_ "GenSigSendType" SG_ 1082 Awake_Diag_Actv 1;
BA_ "GenSigSNA" SG_ 1082 Awake_Diag_Actv "0h";
BA_ "RID" SG_ 1082 Awake_Diag_Actv "9692";
BA_ "FlexKomComment" SG_ 1082 Awake_NwSt "Mode 15 of NM_Ud_Srv";
BA_ "FlexKomIsMotorola" SG_ 1082 Awake_NwSt 1;
BA_ "FlexKomSID" SG_ 1082 Awake_NwSt 2122;
BA_ "FlexKomSigLaenge" SG_ 1082 Awake_NwSt 24;
BA_ "FlexKomSigName" SG_ 1082 Awake_NwSt "Awake_HCP";
BA_ "FlexKomSigStartPos" SG_ 1082 Awake_NwSt 39;
BA_ "FlexKomSigStartValue" SG_ 1082 Awake_NwSt "000000h";
BA_ "GenSigSendType" SG_ 1082 Awake_NwSt 1;
BA_ "GenSigSNA" SG_ 1082 Awake_NwSt "0h";
BA_ "RID" SG_ 1082 Awake_NwSt "9693";
BA_ "FlexKomComment" SG_ 1082 Awake_OBCM_WU "Mode 15 of NM_Ud_Srv";
BA_ "FlexKomIsMotorola" SG_ 1082 Awake_OBCM_WU 1;
BA_ "FlexKomSID" SG_ 1082 Awake_OBCM_WU 2122;
BA_ "FlexKomSigLaenge" SG_ 1082 Awake_OBCM_WU 24;
BA_ "FlexKomSigName" SG_ 1082 Awake_OBCM_WU "Awake_HCP";
BA_ "FlexKomSigStartPos" SG_ 1082 Awake_OBCM_WU 39;
BA_ "FlexKomSigStartValue" SG_ 1082 Awake_OBCM_WU "000000h";
BA_ "GenSigSendType" SG_ 1082 Awake_OBCM_WU 1;
BA_ "GenSigSNA" SG_ 1082 Awake_OBCM_WU "0h";
BA_ "RID" SG_ 1082 Awake_OBCM_WU "9694";
BA_ "FlexKomComment" SG_ 1082 NM_Mode "Network management state";
BA_ "FlexKomIsMotorola" SG_ 1082 NM_Mode 1;
BA_ "FlexKomSID" SG_ 1082 NM_Mode 472;
BA_ "FlexKomSigLaenge" SG_ 1082 NM_Mode 32;
BA_ "FlexKomSigName" SG_ 1082 NM_Mode "NM";
BA_ "FlexKomSigStartPos" SG_ 1082 NM_Mode 7;
BA_ "FlexKomSigStartValue" SG_ 1082 NM_Mode "FFFFFFFFh";
BA_ "GenSigSendType" SG_ 1082 NM_Mode 1;
BA_ "GenSigSNA" SG_ 1082 NM_Mode "FFh";
BA_ "GenSigStartValue" SG_ 1082 NM_Mode 255;
BA_ "RID" SG_ 1082 NM_Mode "9695";
BA_ "FlexKomComment" SG_ 1082 NM_Sleep_Ack "Network management state";
BA_ "FlexKomIsMotorola" SG_ 1082 NM_Sleep_Ack 1;
BA_ "FlexKomSID" SG_ 1082 NM_Sleep_Ack 472;
BA_ "FlexKomSigLaenge" SG_ 1082 NM_Sleep_Ack 32;
BA_ "FlexKomSigName" SG_ 1082 NM_Sleep_Ack "NM";
BA_ "FlexKomSigStartPos" SG_ 1082 NM_Sleep_Ack 7;
BA_ "FlexKomSigStartValue" SG_ 1082 NM_Sleep_Ack "FFFFFFFFh";
BA_ "GenSigSendType" SG_ 1082 NM_Sleep_Ack 1;
BA_ "GenSigSNA" SG_ 1082 NM_Sleep_Ack "1h";
BA_ "GenSigStartValue" SG_ 1082 NM_Sleep_Ack 1;
BA_ "RID" SG_ 1082 NM_Sleep_Ack "9696";
BA_ "FlexKomComment" SG_ 1082 NM_Sleep_Ind "Network management state";
BA_ "FlexKomIsMotorola" SG_ 1082 NM_Sleep_Ind 1;
BA_ "FlexKomSID" SG_ 1082 NM_Sleep_Ind 472;
BA_ "FlexKomSigLaenge" SG_ 1082 NM_Sleep_Ind 32;
BA_ "FlexKomSigName" SG_ 1082 NM_Sleep_Ind "NM";
BA_ "FlexKomSigStartPos" SG_ 1082 NM_Sleep_Ind 7;
BA_ "FlexKomSigStartValue" SG_ 1082 NM_Sleep_Ind "FFFFFFFFh";
BA_ "GenSigSendType" SG_ 1082 NM_Sleep_Ind 1;
BA_ "GenSigSNA" SG_ 1082 NM_Sleep_Ind "1h";
BA_ "GenSigStartValue" SG_ 1082 NM_Sleep_Ind 1;
BA_ "RID" SG_ 1082 NM_Sleep_Ind "9697";
BA_ "FlexKomComment" SG_ 1082 NM_Successor "Network management state";
BA_ "FlexKomIsMotorola" SG_ 1082 NM_Successor 1;
BA_ "FlexKomSID" SG_ 1082 NM_Successor 472;
BA_ "FlexKomSigLaenge" SG_ 1082 NM_Successor 32;
BA_ "FlexKomSigName" SG_ 1082 NM_Successor "NM";
BA_ "FlexKomSigStartPos" SG_ 1082 NM_Successor 7;
BA_ "FlexKomSigStartValue" SG_ 1082 NM_Successor "FFFFFFFFh";
BA_ "GenSigSendType" SG_ 1082 NM_Successor 1;
BA_ "GenSigSNA" SG_ 1082 NM_Successor "FFh";
BA_ "GenSigStartValue" SG_ 1082 NM_Successor 255;
BA_ "RID" SG_ 1082 NM_Successor "9698";
BA_ "FlexKomComment" SG_ 1082 NM_Ud_Launch "Network management state";
BA_ "FlexKomIsMotorola" SG_ 1082 NM_Ud_Launch 1;
BA_ "FlexKomSID" SG_ 1082 NM_Ud_Launch 472;
BA_ "FlexKomSigLaenge" SG_ 1082 NM_Ud_Launch 32;
BA_ "FlexKomSigName" SG_ 1082 NM_Ud_Launch "NM";
BA_ "FlexKomSigStartPos" SG_ 1082 NM_Ud_Launch 7;
BA_ "FlexKomSigStartValue" SG_ 1082 NM_Ud_Launch "FFFFFFFFh";
BA_ "GenSigSendType" SG_ 1082 NM_Ud_Launch 1;
BA_ "GenSigSNA" SG_ 1082 NM_Ud_Launch "3Fh";
BA_ "GenSigStartValue" SG_ 1082 NM_Ud_Launch 63;
BA_ "RID" SG_ 1082 NM_Ud_Launch "9699";
BA_ "FlexKomComment" SG_ 1082 NM_Ud_Srv "Network management state";
BA_ "FlexKomIsMotorola" SG_ 1082 NM_Ud_Srv 1;
BA_ "FlexKomSID" SG_ 1082 NM_Ud_Srv 472;
BA_ "FlexKomSigLaenge" SG_ 1082 NM_Ud_Srv 32;
BA_ "FlexKomSigName" SG_ 1082 NM_Ud_Srv "NM";
BA_ "FlexKomSigStartPos" SG_ 1082 NM_Ud_Srv 7;
BA_ "FlexKomSigStartValue" SG_ 1082 NM_Ud_Srv "FFFFFFFFh";
BA_ "GenSigSendType" SG_ 1082 NM_Ud_Srv 1;
BA_ "GenSigSNA" SG_ 1082 NM_Ud_Srv "FFh";
BA_ "GenSigStartValue" SG_ 1082 NM_Ud_Srv 255;
BA_ "RID" SG_ 1082 NM_Ud_Srv "9700";
BA_ "FlexKomComment" SG_ 1082 Nw_Id "Network identification no.";
BA_ "FlexKomIsMotorola" SG_ 1082 Nw_Id 1;
BA_ "FlexKomSID" SG_ 1082 Nw_Id 535;
BA_ "FlexKomSigLaenge" SG_ 1082 Nw_Id 8;
BA_ "FlexKomSigName" SG_ 1082 Nw_Id "Nw_Id";
BA_ "FlexKomSigStartPos" SG_ 1082 Nw_Id 63;
BA_ "FlexKomSigStartValue" SG_ 1082 Nw_Id "FFh";
BA_ "GenSigSendType" SG_ 1082 Nw_Id 1;
BA_ "GenSigSNA" SG_ 1082 Nw_Id "FFh";
BA_ "GenSigStartValue" SG_ 1082 Nw_Id 255;
BA_ "RID" SG_ 1082 Nw_Id "9701";
BA_ "FlexKomComment" SG_ 1082 WakeupCnt "Mode 2 of NM_Ud_Srv";
BA_ "FlexKomIsMotorola" SG_ 1082 WakeupCnt 1;
BA_ "FlexKomSID" SG_ 1082 WakeupCnt 2123;
BA_ "FlexKomSigLaenge" SG_ 1082 WakeupCnt 24;
BA_ "FlexKomSigName" SG_ 1082 WakeupCnt "Wakeup_HCP";
BA_ "FlexKomSigStartPos" SG_ 1082 WakeupCnt 39;
BA_ "FlexKomSigStartValue" SG_ 1082 WakeupCnt "FFFF00h";
BA_ "GenSigSendType" SG_ 1082 WakeupCnt 1;
BA_ "GenSigSNA" SG_ 1082 WakeupCnt "FFh";
BA_ "GenSigStartValue" SG_ 1082 WakeupCnt 255;
BA_ "RID" SG_ 1082 WakeupCnt "9702";
BA_ "FlexKomComment" SG_ 1082 WakeupRsn_HCP "Mode 2 of NM_Ud_Srv";
BA_ "FlexKomIsMotorola" SG_ 1082 WakeupRsn_HCP 1;
BA_ "FlexKomSID" SG_ 1082 WakeupRsn_HCP 2123;
BA_ "FlexKomSigLaenge" SG_ 1082 WakeupRsn_HCP 24;
BA_ "FlexKomSigName" SG_ 1082 WakeupRsn_HCP "Wakeup_HCP";
BA_ "FlexKomSigStartPos" SG_ 1082 WakeupRsn_HCP 39;
BA_ "FlexKomSigStartValue" SG_ 1082 WakeupRsn_HCP "FFFF00h";
BA_ "GenSigSendType" SG_ 1082 WakeupRsn_HCP 1;
BA_ "GenSigSNA" SG_ 1082 WakeupRsn_HCP "FFh";
BA_ "GenSigStartValue" SG_ 1082 WakeupRsn_HCP 255;
BA_ "RID" SG_ 1082 WakeupRsn_HCP "9703";
BA_ "FlexKomComment" SG_ 1026 Awake_Diag_Actv "Mode 15 of NM_Ud_Srv";
BA_ "FlexKomIsMotorola" SG_ 1026 Awake_Diag_Actv 1;
BA_ "FlexKomSID" SG_ 1026 Awake_Diag_Actv 512;
BA_ "FlexKomSigLaenge" SG_ 1026 Awake_Diag_Actv 24;
BA_ "FlexKomSigName" SG_ 1026 Awake_Diag_Actv "Awake_IC";
BA_ "FlexKomSigStartPos" SG_ 1026 Awake_Diag_Actv 39;
BA_ "FlexKomSigStartValue" SG_ 1026 Awake_Diag_Actv "000000h";
BA_ "GenSigSendType" SG_ 1026 Awake_Diag_Actv 1;
BA_ "GenSigSNA" SG_ 1026 Awake_Diag_Actv "0h";
BA_ "RID" SG_ 1026 Awake_Diag_Actv "9704";
BA_ "FlexKomComment" SG_ 1026 Awake_NwSt "Mode 15 of NM_Ud_Srv";
BA_ "FlexKomIsMotorola" SG_ 1026 Awake_NwSt 1;
BA_ "FlexKomSID" SG_ 1026 Awake_NwSt 512;
BA_ "FlexKomSigLaenge" SG_ 1026 Awake_NwSt 24;
BA_ "FlexKomSigName" SG_ 1026 Awake_NwSt "Awake_IC";
BA_ "FlexKomSigStartPos" SG_ 1026 Awake_NwSt 39;
BA_ "FlexKomSigStartValue" SG_ 1026 Awake_NwSt "000000h";
BA_ "GenSigSendType" SG_ 1026 Awake_NwSt 1;
BA_ "GenSigSNA" SG_ 1026 Awake_NwSt "0h";
BA_ "RID" SG_ 1026 Awake_NwSt "9705";
BA_ "FlexKomComment" SG_ 1026 NM_Mode "Network management state";
BA_ "FlexKomIsMotorola" SG_ 1026 NM_Mode 1;
BA_ "FlexKomSID" SG_ 1026 NM_Mode 472;
BA_ "FlexKomSigLaenge" SG_ 1026 NM_Mode 32;
BA_ "FlexKomSigName" SG_ 1026 NM_Mode "NM";
BA_ "FlexKomSigStartPos" SG_ 1026 NM_Mode 7;
BA_ "FlexKomSigStartValue" SG_ 1026 NM_Mode "FFFFFFFFh";
BA_ "GenSigSendType" SG_ 1026 NM_Mode 1;
BA_ "GenSigSNA" SG_ 1026 NM_Mode "FFh";
BA_ "GenSigStartValue" SG_ 1026 NM_Mode 255;
BA_ "RID" SG_ 1026 NM_Mode "9706";
BA_ "FlexKomComment" SG_ 1026 NM_Sleep_Ack "Network management state";
BA_ "FlexKomIsMotorola" SG_ 1026 NM_Sleep_Ack 1;
BA_ "FlexKomSID" SG_ 1026 NM_Sleep_Ack 472;
BA_ "FlexKomSigLaenge" SG_ 1026 NM_Sleep_Ack 32;
BA_ "FlexKomSigName" SG_ 1026 NM_Sleep_Ack "NM";
BA_ "FlexKomSigStartPos" SG_ 1026 NM_Sleep_Ack 7;
BA_ "FlexKomSigStartValue" SG_ 1026 NM_Sleep_Ack "FFFFFFFFh";
BA_ "GenSigSendType" SG_ 1026 NM_Sleep_Ack 1;
BA_ "GenSigSNA" SG_ 1026 NM_Sleep_Ack "1h";
BA_ "GenSigStartValue" SG_ 1026 NM_Sleep_Ack 1;
BA_ "RID" SG_ 1026 NM_Sleep_Ack "9707";
BA_ "FlexKomComment" SG_ 1026 NM_Sleep_Ind "Network management state";
BA_ "FlexKomIsMotorola" SG_ 1026 NM_Sleep_Ind 1;
BA_ "FlexKomSID" SG_ 1026 NM_Sleep_Ind 472;
BA_ "FlexKomSigLaenge" SG_ 1026 NM_Sleep_Ind 32;
BA_ "FlexKomSigName" SG_ 1026 NM_Sleep_Ind "NM";
BA_ "FlexKomSigStartPos" SG_ 1026 NM_Sleep_Ind 7;
BA_ "FlexKomSigStartValue" SG_ 1026 NM_Sleep_Ind "FFFFFFFFh";
BA_ "GenSigSendType" SG_ 1026 NM_Sleep_Ind 1;
BA_ "GenSigSNA" SG_ 1026 NM_Sleep_Ind "1h";
BA_ "GenSigStartValue" SG_ 1026 NM_Sleep_Ind 1;
BA_ "RID" SG_ 1026 NM_Sleep_Ind "9708";
BA_ "FlexKomComment" SG_ 1026 NM_Successor "Network management state";
BA_ "FlexKomIsMotorola" SG_ 1026 NM_Successor 1;
BA_ "FlexKomSID" SG_ 1026 NM_Successor 472;
BA_ "FlexKomSigLaenge" SG_ 1026 NM_Successor 32;
BA_ "FlexKomSigName" SG_ 1026 NM_Successor "NM";
BA_ "FlexKomSigStartPos" SG_ 1026 NM_Successor 7;
BA_ "FlexKomSigStartValue" SG_ 1026 NM_Successor "FFFFFFFFh";
BA_ "GenSigSendType" SG_ 1026 NM_Successor 1;
BA_ "GenSigSNA" SG_ 1026 NM_Successor "FFh";
BA_ "GenSigStartValue" SG_ 1026 NM_Successor 255;
BA_ "RID" SG_ 1026 NM_Successor "9709";
BA_ "FlexKomComment" SG_ 1026 NM_Ud_Launch "Network management state";
BA_ "FlexKomIsMotorola" SG_ 1026 NM_Ud_Launch 1;
BA_ "FlexKomSID" SG_ 1026 NM_Ud_Launch 472;
BA_ "FlexKomSigLaenge" SG_ 1026 NM_Ud_Launch 32;
BA_ "FlexKomSigName" SG_ 1026 NM_Ud_Launch "NM";
BA_ "FlexKomSigStartPos" SG_ 1026 NM_Ud_Launch 7;
BA_ "FlexKomSigStartValue" SG_ 1026 NM_Ud_Launch "FFFFFFFFh";
BA_ "GenSigSendType" SG_ 1026 NM_Ud_Launch 1;
BA_ "GenSigSNA" SG_ 1026 NM_Ud_Launch "3Fh";
BA_ "GenSigStartValue" SG_ 1026 NM_Ud_Launch 63;
BA_ "RID" SG_ 1026 NM_Ud_Launch "9710";
BA_ "FlexKomComment" SG_ 1026 NM_Ud_Srv "Network management state";
BA_ "FlexKomIsMotorola" SG_ 1026 NM_Ud_Srv 1;
BA_ "FlexKomSID" SG_ 1026 NM_Ud_Srv 472;
BA_ "FlexKomSigLaenge" SG_ 1026 NM_Ud_Srv 32;
BA_ "FlexKomSigName" SG_ 1026 NM_Ud_Srv "NM";
BA_ "FlexKomSigStartPos" SG_ 1026 NM_Ud_Srv 7;
BA_ "FlexKomSigStartValue" SG_ 1026 NM_Ud_Srv "FFFFFFFFh";
BA_ "GenSigSendType" SG_ 1026 NM_Ud_Srv 1;
BA_ "GenSigSNA" SG_ 1026 NM_Ud_Srv "FFh";
BA_ "GenSigStartValue" SG_ 1026 NM_Ud_Srv 255;
BA_ "RID" SG_ 1026 NM_Ud_Srv "9711";
BA_ "FlexKomComment" SG_ 1026 Nw_Id "Network identification no.";
BA_ "FlexKomIsMotorola" SG_ 1026 Nw_Id 1;
BA_ "FlexKomSID" SG_ 1026 Nw_Id 535;
BA_ "FlexKomSigLaenge" SG_ 1026 Nw_Id 8;
BA_ "FlexKomSigName" SG_ 1026 Nw_Id "Nw_Id";
BA_ "FlexKomSigStartPos" SG_ 1026 Nw_Id 63;
BA_ "FlexKomSigStartValue" SG_ 1026 Nw_Id "FFh";
BA_ "GenSigSendType" SG_ 1026 Nw_Id 1;
BA_ "GenSigSNA" SG_ 1026 Nw_Id "FFh";
BA_ "GenSigStartValue" SG_ 1026 Nw_Id 255;
BA_ "RID" SG_ 1026 Nw_Id "9712";
BA_ "FlexKomComment" SG_ 1026 WakeupCnt "Mode 2 of NM_Ud_Srv";
BA_ "FlexKomIsMotorola" SG_ 1026 WakeupCnt 1;
BA_ "FlexKomSID" SG_ 1026 WakeupCnt 482;
BA_ "FlexKomSigLaenge" SG_ 1026 WakeupCnt 24;
BA_ "FlexKomSigName" SG_ 1026 WakeupCnt "Wakeup_IC";
BA_ "FlexKomSigStartPos" SG_ 1026 WakeupCnt 39;
BA_ "FlexKomSigStartValue" SG_ 1026 WakeupCnt "FFFF00h";
BA_ "GenSigSendType" SG_ 1026 WakeupCnt 1;
BA_ "GenSigSNA" SG_ 1026 WakeupCnt "FFh";
BA_ "GenSigStartValue" SG_ 1026 WakeupCnt 255;
BA_ "RID" SG_ 1026 WakeupCnt "9713";
BA_ "FlexKomComment" SG_ 1026 WakeupRsn_IC "Mode 2 of NM_Ud_Srv";
BA_ "FlexKomIsMotorola" SG_ 1026 WakeupRsn_IC 1;
BA_ "FlexKomSID" SG_ 1026 WakeupRsn_IC 482;
BA_ "FlexKomSigLaenge" SG_ 1026 WakeupRsn_IC 24;
BA_ "FlexKomSigName" SG_ 1026 WakeupRsn_IC "Wakeup_IC";
BA_ "FlexKomSigStartPos" SG_ 1026 WakeupRsn_IC 39;
BA_ "FlexKomSigStartValue" SG_ 1026 WakeupRsn_IC "FFFF00h";
BA_ "GenSigSendType" SG_ 1026 WakeupRsn_IC 1;
BA_ "GenSigSNA" SG_ 1026 WakeupRsn_IC "FFh";
BA_ "GenSigStartValue" SG_ 1026 WakeupRsn_IC 255;
BA_ "RID" SG_ 1026 WakeupRsn_IC "9714";
BA_ "FlexKomComment" SG_ 1024 Awake_Diag_Actv "Mode 15 of NM_Ud_Srv";
BA_ "FlexKomIsMotorola" SG_ 1024 Awake_Diag_Actv 1;
BA_ "FlexKomSID" SG_ 1024 Awake_Diag_Actv 619;
BA_ "FlexKomSigLaenge" SG_ 1024 Awake_Diag_Actv 24;
BA_ "FlexKomSigName" SG_ 1024 Awake_Diag_Actv "Awake_RF_HUB";
BA_ "FlexKomSigStartPos" SG_ 1024 Awake_Diag_Actv 39;
BA_ "FlexKomSigStartValue" SG_ 1024 Awake_Diag_Actv "000000h";
BA_ "GenSigSendType" SG_ 1024 Awake_Diag_Actv 1;
BA_ "GenSigSNA" SG_ 1024 Awake_Diag_Actv "0h";
BA_ "RID" SG_ 1024 Awake_Diag_Actv "9715";
BA_ "FlexKomComment" SG_ 1024 Awake_NwSt "Mode 15 of NM_Ud_Srv";
BA_ "FlexKomIsMotorola" SG_ 1024 Awake_NwSt 1;
BA_ "FlexKomSID" SG_ 1024 Awake_NwSt 619;
BA_ "FlexKomSigLaenge" SG_ 1024 Awake_NwSt 24;
BA_ "FlexKomSigName" SG_ 1024 Awake_NwSt "Awake_RF_HUB";
BA_ "FlexKomSigStartPos" SG_ 1024 Awake_NwSt 39;
BA_ "FlexKomSigStartValue" SG_ 1024 Awake_NwSt "000000h";
BA_ "GenSigSendType" SG_ 1024 Awake_NwSt 1;
BA_ "GenSigSNA" SG_ 1024 Awake_NwSt "0h";
BA_ "RID" SG_ 1024 Awake_NwSt "9716";
BA_ "FlexKomComment" SG_ 1024 NM_Mode "Network management state";
BA_ "FlexKomIsMotorola" SG_ 1024 NM_Mode 1;
BA_ "FlexKomSID" SG_ 1024 NM_Mode 472;
BA_ "FlexKomSigLaenge" SG_ 1024 NM_Mode 32;
BA_ "FlexKomSigName" SG_ 1024 NM_Mode "NM";
BA_ "FlexKomSigStartPos" SG_ 1024 NM_Mode 7;
BA_ "FlexKomSigStartValue" SG_ 1024 NM_Mode "FFFFFFFFh";
BA_ "GenSigSendType" SG_ 1024 NM_Mode 1;
BA_ "GenSigSNA" SG_ 1024 NM_Mode "FFh";
BA_ "GenSigStartValue" SG_ 1024 NM_Mode 255;
BA_ "RID" SG_ 1024 NM_Mode "9717";
BA_ "FlexKomComment" SG_ 1024 NM_Sleep_Ack "Network management state";
BA_ "FlexKomIsMotorola" SG_ 1024 NM_Sleep_Ack 1;
BA_ "FlexKomSID" SG_ 1024 NM_Sleep_Ack 472;
BA_ "FlexKomSigLaenge" SG_ 1024 NM_Sleep_Ack 32;
BA_ "FlexKomSigName" SG_ 1024 NM_Sleep_Ack "NM";
BA_ "FlexKomSigStartPos" SG_ 1024 NM_Sleep_Ack 7;
BA_ "FlexKomSigStartValue" SG_ 1024 NM_Sleep_Ack "FFFFFFFFh";
BA_ "GenSigSendType" SG_ 1024 NM_Sleep_Ack 1;
BA_ "GenSigSNA" SG_ 1024 NM_Sleep_Ack "1h";
BA_ "GenSigStartValue" SG_ 1024 NM_Sleep_Ack 1;
BA_ "RID" SG_ 1024 NM_Sleep_Ack "9718";
BA_ "FlexKomComment" SG_ 1024 NM_Sleep_Ind "Network management state";
BA_ "FlexKomIsMotorola" SG_ 1024 NM_Sleep_Ind 1;
BA_ "FlexKomSID" SG_ 1024 NM_Sleep_Ind 472;
BA_ "FlexKomSigLaenge" SG_ 1024 NM_Sleep_Ind 32;
BA_ "FlexKomSigName" SG_ 1024 NM_Sleep_Ind "NM";
BA_ "FlexKomSigStartPos" SG_ 1024 NM_Sleep_Ind 7;
BA_ "FlexKomSigStartValue" SG_ 1024 NM_Sleep_Ind "FFFFFFFFh";
BA_ "GenSigSendType" SG_ 1024 NM_Sleep_Ind 1;
BA_ "GenSigSNA" SG_ 1024 NM_Sleep_Ind "1h";
BA_ "GenSigStartValue" SG_ 1024 NM_Sleep_Ind 1;
BA_ "RID" SG_ 1024 NM_Sleep_Ind "9719";
BA_ "FlexKomComment" SG_ 1024 NM_Successor "Network management state";
BA_ "FlexKomIsMotorola" SG_ 1024 NM_Successor 1;
BA_ "FlexKomSID" SG_ 1024 NM_Successor 472;
BA_ "FlexKomSigLaenge" SG_ 1024 NM_Successor 32;
BA_ "FlexKomSigName" SG_ 1024 NM_Successor "NM";
BA_ "FlexKomSigStartPos" SG_ 1024 NM_Successor 7;
BA_ "FlexKomSigStartValue" SG_ 1024 NM_Successor "FFFFFFFFh";
BA_ "GenSigSendType" SG_ 1024 NM_Successor 1;
BA_ "GenSigSNA" SG_ 1024 NM_Successor "FFh";
BA_ "GenSigStartValue" SG_ 1024 NM_Successor 255;
BA_ "RID" SG_ 1024 NM_Successor "9720";
BA_ "FlexKomComment" SG_ 1024 NM_Ud_Launch "Network management state";
BA_ "FlexKomIsMotorola" SG_ 1024 NM_Ud_Launch 1;
BA_ "FlexKomSID" SG_ 1024 NM_Ud_Launch 472;
BA_ "FlexKomSigLaenge" SG_ 1024 NM_Ud_Launch 32;
BA_ "FlexKomSigName" SG_ 1024 NM_Ud_Launch "NM";
BA_ "FlexKomSigStartPos" SG_ 1024 NM_Ud_Launch 7;
BA_ "FlexKomSigStartValue" SG_ 1024 NM_Ud_Launch "FFFFFFFFh";
BA_ "GenSigSendType" SG_ 1024 NM_Ud_Launch 1;
BA_ "GenSigSNA" SG_ 1024 NM_Ud_Launch "3Fh";
BA_ "GenSigStartValue" SG_ 1024 NM_Ud_Launch 63;
BA_ "RID" SG_ 1024 NM_Ud_Launch "9721";
BA_ "FlexKomComment" SG_ 1024 NM_Ud_Srv "Network management state";
BA_ "FlexKomIsMotorola" SG_ 1024 NM_Ud_Srv 1;
BA_ "FlexKomSID" SG_ 1024 NM_Ud_Srv 472;
BA_ "FlexKomSigLaenge" SG_ 1024 NM_Ud_Srv 32;
BA_ "FlexKomSigName" SG_ 1024 NM_Ud_Srv "NM";
BA_ "FlexKomSigStartPos" SG_ 1024 NM_Ud_Srv 7;
BA_ "FlexKomSigStartValue" SG_ 1024 NM_Ud_Srv "FFFFFFFFh";
BA_ "GenSigSendType" SG_ 1024 NM_Ud_Srv 1;
BA_ "GenSigSNA" SG_ 1024 NM_Ud_Srv "FFh";
BA_ "GenSigStartValue" SG_ 1024 NM_Ud_Srv 255;
BA_ "RID" SG_ 1024 NM_Ud_Srv "9722";
BA_ "FlexKomComment" SG_ 1024 Nw_Id "Network identification no.";
BA_ "FlexKomIsMotorola" SG_ 1024 Nw_Id 1;
BA_ "FlexKomSID" SG_ 1024 Nw_Id 535;
BA_ "FlexKomSigLaenge" SG_ 1024 Nw_Id 8;
BA_ "FlexKomSigName" SG_ 1024 Nw_Id "Nw_Id";
BA_ "FlexKomSigStartPos" SG_ 1024 Nw_Id 63;
BA_ "FlexKomSigStartValue" SG_ 1024 Nw_Id "FFh";
BA_ "GenSigSendType" SG_ 1024 Nw_Id 1;
BA_ "GenSigSNA" SG_ 1024 Nw_Id "FFh";
BA_ "GenSigStartValue" SG_ 1024 Nw_Id 255;
BA_ "RID" SG_ 1024 Nw_Id "9723";
BA_ "FlexKomComment" SG_ 1024 WakeupCnt "Mode 2 of NM_Ud_Srv";
BA_ "FlexKomIsMotorola" SG_ 1024 WakeupCnt 1;
BA_ "FlexKomSID" SG_ 1024 WakeupCnt 620;
BA_ "FlexKomSigLaenge" SG_ 1024 WakeupCnt 24;
BA_ "FlexKomSigName" SG_ 1024 WakeupCnt "Wakeup_RF_HUB";
BA_ "FlexKomSigStartPos" SG_ 1024 WakeupCnt 39;
BA_ "FlexKomSigStartValue" SG_ 1024 WakeupCnt "FFFF00h";
BA_ "GenSigSendType" SG_ 1024 WakeupCnt 1;
BA_ "GenSigSNA" SG_ 1024 WakeupCnt "FFh";
BA_ "GenSigStartValue" SG_ 1024 WakeupCnt 255;
BA_ "RID" SG_ 1024 WakeupCnt "9724";
BA_ "FlexKomComment" SG_ 1024 WakeupRsn_RF_HUB "Mode 2 of NM_Ud_Srv";
BA_ "FlexKomIsMotorola" SG_ 1024 WakeupRsn_RF_HUB 1;
BA_ "FlexKomSID" SG_ 1024 WakeupRsn_RF_HUB 620;
BA_ "FlexKomSigLaenge" SG_ 1024 WakeupRsn_RF_HUB 24;
BA_ "FlexKomSigName" SG_ 1024 WakeupRsn_RF_HUB "Wakeup_RF_HUB";
BA_ "FlexKomSigStartPos" SG_ 1024 WakeupRsn_RF_HUB 39;
BA_ "FlexKomSigStartValue" SG_ 1024 WakeupRsn_RF_HUB "FFFF00h";
BA_ "GenSigSendType" SG_ 1024 WakeupRsn_RF_HUB 1;
BA_ "GenSigSNA" SG_ 1024 WakeupRsn_RF_HUB "FFh";
BA_ "GenSigStartValue" SG_ 1024 WakeupRsn_RF_HUB 255;
BA_ "RID" SG_ 1024 WakeupRsn_RF_HUB "9725";
BA_ "FlexKomComment" SG_ 1059 Awake_Diag_Actv "Mode 15 of NM_Ud_Srv";
BA_ "FlexKomIsMotorola" SG_ 1059 Awake_Diag_Actv 1;
BA_ "FlexKomSID" SG_ 1059 Awake_Diag_Actv 524;
BA_ "FlexKomSigLaenge" SG_ 1059 Awake_Diag_Actv 24;
BA_ "FlexKomSigName" SG_ 1059 Awake_Diag_Actv "Awake_SCCM_Pkt";
BA_ "FlexKomSigStartPos" SG_ 1059 Awake_Diag_Actv 39;
BA_ "FlexKomSigStartValue" SG_ 1059 Awake_Diag_Actv "000000h";
BA_ "GenSigSendType" SG_ 1059 Awake_Diag_Actv 1;
BA_ "GenSigSNA" SG_ 1059 Awake_Diag_Actv "0h";
BA_ "RID" SG_ 1059 Awake_Diag_Actv "9726";
BA_ "FlexKomComment" SG_ 1059 Awake_EEPROM "Mode 15 of NM_Ud_Srv";
BA_ "FlexKomIsMotorola" SG_ 1059 Awake_EEPROM 1;
BA_ "FlexKomSID" SG_ 1059 Awake_EEPROM 524;
BA_ "FlexKomSigLaenge" SG_ 1059 Awake_EEPROM 24;
BA_ "FlexKomSigName" SG_ 1059 Awake_EEPROM "Awake_SCCM_Pkt";
BA_ "FlexKomSigStartPos" SG_ 1059 Awake_EEPROM 39;
BA_ "FlexKomSigStartValue" SG_ 1059 Awake_EEPROM "000000h";
BA_ "GenSigSendType" SG_ 1059 Awake_EEPROM 1;
BA_ "GenSigSNA" SG_ 1059 Awake_EEPROM "0h";
BA_ "RID" SG_ 1059 Awake_EEPROM "9727";
BA_ "FlexKomComment" SG_ 1059 Awake_FTP_Psd "Mode 15 of NM_Ud_Srv";
BA_ "FlexKomIsMotorola" SG_ 1059 Awake_FTP_Psd 1;
BA_ "FlexKomSID" SG_ 1059 Awake_FTP_Psd 524;
BA_ "FlexKomSigLaenge" SG_ 1059 Awake_FTP_Psd 24;
BA_ "FlexKomSigName" SG_ 1059 Awake_FTP_Psd "Awake_SCCM_Pkt";
BA_ "FlexKomSigStartPos" SG_ 1059 Awake_FTP_Psd 39;
BA_ "FlexKomSigStartValue" SG_ 1059 Awake_FTP_Psd "000000h";
BA_ "GenSigSendType" SG_ 1059 Awake_FTP_Psd 1;
BA_ "GenSigSNA" SG_ 1059 Awake_FTP_Psd "0h";
BA_ "RID" SG_ 1059 Awake_FTP_Psd "9728";
BA_ "FlexKomComment" SG_ 1059 Awake_HrnSwt_Actv "Mode 15 of NM_Ud_Srv";
BA_ "FlexKomIsMotorola" SG_ 1059 Awake_HrnSwt_Actv 1;
BA_ "FlexKomSID" SG_ 1059 Awake_HrnSwt_Actv 524;
BA_ "FlexKomSigLaenge" SG_ 1059 Awake_HrnSwt_Actv 24;
BA_ "FlexKomSigName" SG_ 1059 Awake_HrnSwt_Actv "Awake_SCCM_Pkt";
BA_ "FlexKomSigStartPos" SG_ 1059 Awake_HrnSwt_Actv 39;
BA_ "FlexKomSigStartValue" SG_ 1059 Awake_HrnSwt_Actv "000000h";
BA_ "GenSigSendType" SG_ 1059 Awake_HrnSwt_Actv 1;
BA_ "GenSigSNA" SG_ 1059 Awake_HrnSwt_Actv "0h";
BA_ "RID" SG_ 1059 Awake_HrnSwt_Actv "9729";
BA_ "FlexKomComment" SG_ 1059 Awake_Ignition_On "Mode 15 of NM_Ud_Srv";
BA_ "FlexKomIsMotorola" SG_ 1059 Awake_Ignition_On 1;
BA_ "FlexKomSID" SG_ 1059 Awake_Ignition_On 524;
BA_ "FlexKomSigLaenge" SG_ 1059 Awake_Ignition_On 24;
BA_ "FlexKomSigName" SG_ 1059 Awake_Ignition_On "Awake_SCCM_Pkt";
BA_ "FlexKomSigStartPos" SG_ 1059 Awake_Ignition_On 39;
BA_ "FlexKomSigStartValue" SG_ 1059 Awake_Ignition_On "000000h";
BA_ "GenSigSendType" SG_ 1059 Awake_Ignition_On 1;
BA_ "GenSigSNA" SG_ 1059 Awake_Ignition_On "0h";
BA_ "RID" SG_ 1059 Awake_Ignition_On "9730";
BA_ "FlexKomComment" SG_ 1059 Awake_NwSt "Mode 15 of NM_Ud_Srv";
BA_ "FlexKomIsMotorola" SG_ 1059 Awake_NwSt 1;
BA_ "FlexKomSID" SG_ 1059 Awake_NwSt 524;
BA_ "FlexKomSigLaenge" SG_ 1059 Awake_NwSt 24;
BA_ "FlexKomSigName" SG_ 1059 Awake_NwSt "Awake_SCCM_Pkt";
BA_ "FlexKomSigStartPos" SG_ 1059 Awake_NwSt 39;
BA_ "FlexKomSigStartValue" SG_ 1059 Awake_NwSt "000000h";
BA_ "GenSigSendType" SG_ 1059 Awake_NwSt 1;
BA_ "GenSigSNA" SG_ 1059 Awake_NwSt "0h";
BA_ "RID" SG_ 1059 Awake_NwSt "9731";
BA_ "FlexKomComment" SG_ 1059 Awake_StwSw_Actv "Mode 15 of NM_Ud_Srv";
BA_ "FlexKomIsMotorola" SG_ 1059 Awake_StwSw_Actv 1;
BA_ "FlexKomSID" SG_ 1059 Awake_StwSw_Actv 524;
BA_ "FlexKomSigLaenge" SG_ 1059 Awake_StwSw_Actv 24;
BA_ "FlexKomSigName" SG_ 1059 Awake_StwSw_Actv "Awake_SCCM_Pkt";
BA_ "FlexKomSigStartPos" SG_ 1059 Awake_StwSw_Actv 39;
BA_ "FlexKomSigStartValue" SG_ 1059 Awake_StwSw_Actv "000000h";
BA_ "GenSigSendType" SG_ 1059 Awake_StwSw_Actv 1;
BA_ "GenSigSNA" SG_ 1059 Awake_StwSw_Actv "0h";
BA_ "RID" SG_ 1059 Awake_StwSw_Actv "9732";
BA_ "FlexKomComment" SG_ 1059 Awake_tilt_tel_Psd "Mode 15 of NM_Ud_Srv";
BA_ "FlexKomIsMotorola" SG_ 1059 Awake_tilt_tel_Psd 1;
BA_ "FlexKomSID" SG_ 1059 Awake_tilt_tel_Psd 524;
BA_ "FlexKomSigLaenge" SG_ 1059 Awake_tilt_tel_Psd 24;
BA_ "FlexKomSigName" SG_ 1059 Awake_tilt_tel_Psd "Awake_SCCM_Pkt";
BA_ "FlexKomSigStartPos" SG_ 1059 Awake_tilt_tel_Psd 39;
BA_ "FlexKomSigStartValue" SG_ 1059 Awake_tilt_tel_Psd "000000h";
BA_ "GenSigSendType" SG_ 1059 Awake_tilt_tel_Psd 1;
BA_ "GenSigSNA" SG_ 1059 Awake_tilt_tel_Psd "0h";
BA_ "RID" SG_ 1059 Awake_tilt_tel_Psd "9733";
BA_ "FlexKomComment" SG_ 1059 NM_Mode "Network management state";
BA_ "FlexKomIsMotorola" SG_ 1059 NM_Mode 1;
BA_ "FlexKomSID" SG_ 1059 NM_Mode 472;
BA_ "FlexKomSigLaenge" SG_ 1059 NM_Mode 32;
BA_ "FlexKomSigName" SG_ 1059 NM_Mode "NM";
BA_ "FlexKomSigStartPos" SG_ 1059 NM_Mode 7;
BA_ "FlexKomSigStartValue" SG_ 1059 NM_Mode "FFFFFFFFh";
BA_ "GenSigSendType" SG_ 1059 NM_Mode 1;
BA_ "GenSigSNA" SG_ 1059 NM_Mode "FFh";
BA_ "GenSigStartValue" SG_ 1059 NM_Mode 255;
BA_ "RID" SG_ 1059 NM_Mode "9734";
BA_ "FlexKomComment" SG_ 1059 NM_Sleep_Ack "Network management state";
BA_ "FlexKomIsMotorola" SG_ 1059 NM_Sleep_Ack 1;
BA_ "FlexKomSID" SG_ 1059 NM_Sleep_Ack 472;
BA_ "FlexKomSigLaenge" SG_ 1059 NM_Sleep_Ack 32;
BA_ "FlexKomSigName" SG_ 1059 NM_Sleep_Ack "NM";
BA_ "FlexKomSigStartPos" SG_ 1059 NM_Sleep_Ack 7;
BA_ "FlexKomSigStartValue" SG_ 1059 NM_Sleep_Ack "FFFFFFFFh";
BA_ "GenSigSendType" SG_ 1059 NM_Sleep_Ack 1;
BA_ "GenSigSNA" SG_ 1059 NM_Sleep_Ack "1h";
BA_ "GenSigStartValue" SG_ 1059 NM_Sleep_Ack 1;
BA_ "RID" SG_ 1059 NM_Sleep_Ack "9735";
BA_ "FlexKomComment" SG_ 1059 NM_Sleep_Ind "Network management state";
BA_ "FlexKomIsMotorola" SG_ 1059 NM_Sleep_Ind 1;
BA_ "FlexKomSID" SG_ 1059 NM_Sleep_Ind 472;
BA_ "FlexKomSigLaenge" SG_ 1059 NM_Sleep_Ind 32;
BA_ "FlexKomSigName" SG_ 1059 NM_Sleep_Ind "NM";
BA_ "FlexKomSigStartPos" SG_ 1059 NM_Sleep_Ind 7;
BA_ "FlexKomSigStartValue" SG_ 1059 NM_Sleep_Ind "FFFFFFFFh";
BA_ "GenSigSendType" SG_ 1059 NM_Sleep_Ind 1;
BA_ "GenSigSNA" SG_ 1059 NM_Sleep_Ind "1h";
BA_ "GenSigStartValue" SG_ 1059 NM_Sleep_Ind 1;
BA_ "RID" SG_ 1059 NM_Sleep_Ind "9736";
BA_ "FlexKomComment" SG_ 1059 NM_Successor "Network management state";
BA_ "FlexKomIsMotorola" SG_ 1059 NM_Successor 1;
BA_ "FlexKomSID" SG_ 1059 NM_Successor 472;
BA_ "FlexKomSigLaenge" SG_ 1059 NM_Successor 32;
BA_ "FlexKomSigName" SG_ 1059 NM_Successor "NM";
BA_ "FlexKomSigStartPos" SG_ 1059 NM_Successor 7;
BA_ "FlexKomSigStartValue" SG_ 1059 NM_Successor "FFFFFFFFh";
BA_ "GenSigSendType" SG_ 1059 NM_Successor 1;
BA_ "GenSigSNA" SG_ 1059 NM_Successor "FFh";
BA_ "GenSigStartValue" SG_ 1059 NM_Successor 255;
BA_ "RID" SG_ 1059 NM_Successor "9737";
BA_ "FlexKomComment" SG_ 1059 NM_Ud_Launch "Network management state";
BA_ "FlexKomIsMotorola" SG_ 1059 NM_Ud_Launch 1;
BA_ "FlexKomSID" SG_ 1059 NM_Ud_Launch 472;
BA_ "FlexKomSigLaenge" SG_ 1059 NM_Ud_Launch 32;
BA_ "FlexKomSigName" SG_ 1059 NM_Ud_Launch "NM";
BA_ "FlexKomSigStartPos" SG_ 1059 NM_Ud_Launch 7;
BA_ "FlexKomSigStartValue" SG_ 1059 NM_Ud_Launch "FFFFFFFFh";
BA_ "GenSigSendType" SG_ 1059 NM_Ud_Launch 1;
BA_ "GenSigSNA" SG_ 1059 NM_Ud_Launch "3Fh";
BA_ "GenSigStartValue" SG_ 1059 NM_Ud_Launch 63;
BA_ "RID" SG_ 1059 NM_Ud_Launch "9738";
BA_ "FlexKomComment" SG_ 1059 NM_Ud_Srv "Network management state";
BA_ "FlexKomIsMotorola" SG_ 1059 NM_Ud_Srv 1;
BA_ "FlexKomSID" SG_ 1059 NM_Ud_Srv 472;
BA_ "FlexKomSigLaenge" SG_ 1059 NM_Ud_Srv 32;
BA_ "FlexKomSigName" SG_ 1059 NM_Ud_Srv "NM";
BA_ "FlexKomSigStartPos" SG_ 1059 NM_Ud_Srv 7;
BA_ "FlexKomSigStartValue" SG_ 1059 NM_Ud_Srv "FFFFFFFFh";
BA_ "GenSigSendType" SG_ 1059 NM_Ud_Srv 1;
BA_ "GenSigSNA" SG_ 1059 NM_Ud_Srv "FFh";
BA_ "GenSigStartValue" SG_ 1059 NM_Ud_Srv 255;
BA_ "RID" SG_ 1059 NM_Ud_Srv "9739";
BA_ "FlexKomComment" SG_ 1059 Nw_Id "Network identification no.";
BA_ "FlexKomIsMotorola" SG_ 1059 Nw_Id 1;
BA_ "FlexKomSID" SG_ 1059 Nw_Id 535;
BA_ "FlexKomSigLaenge" SG_ 1059 Nw_Id 8;
BA_ "FlexKomSigName" SG_ 1059 Nw_Id "Nw_Id";
BA_ "FlexKomSigStartPos" SG_ 1059 Nw_Id 63;
BA_ "FlexKomSigStartValue" SG_ 1059 Nw_Id "FFh";
BA_ "GenSigSendType" SG_ 1059 Nw_Id 1;
BA_ "GenSigSNA" SG_ 1059 Nw_Id "FFh";
BA_ "GenSigStartValue" SG_ 1059 Nw_Id 255;
BA_ "RID" SG_ 1059 Nw_Id "9740";
BA_ "FlexKomComment" SG_ 1059 WakeupCnt "Mode 2 of NM_Ud_Srv";
BA_ "FlexKomIsMotorola" SG_ 1059 WakeupCnt 1;
BA_ "FlexKomSID" SG_ 1059 WakeupCnt 494;
BA_ "FlexKomSigLaenge" SG_ 1059 WakeupCnt 24;
BA_ "FlexKomSigName" SG_ 1059 WakeupCnt "Wakeup_SCCM_Pkt";
BA_ "FlexKomSigStartPos" SG_ 1059 WakeupCnt 39;
BA_ "FlexKomSigStartValue" SG_ 1059 WakeupCnt "FFFF00h";
BA_ "GenSigSendType" SG_ 1059 WakeupCnt 1;
BA_ "GenSigSNA" SG_ 1059 WakeupCnt "FFh";
BA_ "GenSigStartValue" SG_ 1059 WakeupCnt 255;
BA_ "RID" SG_ 1059 WakeupCnt "9741";
BA_ "FlexKomComment" SG_ 1059 WakeupRsn_SCCM "Mode 2 of NM_Ud_Srv";
BA_ "FlexKomIsMotorola" SG_ 1059 WakeupRsn_SCCM 1;
BA_ "FlexKomSID" SG_ 1059 WakeupRsn_SCCM 494;
BA_ "FlexKomSigLaenge" SG_ 1059 WakeupRsn_SCCM 24;
BA_ "FlexKomSigName" SG_ 1059 WakeupRsn_SCCM "Wakeup_SCCM_Pkt";
BA_ "FlexKomSigStartPos" SG_ 1059 WakeupRsn_SCCM 39;
BA_ "FlexKomSigStartValue" SG_ 1059 WakeupRsn_SCCM "FFFF00h";
BA_ "GenSigSendType" SG_ 1059 WakeupRsn_SCCM 1;
BA_ "GenSigSNA" SG_ 1059 WakeupRsn_SCCM "FFh";
BA_ "GenSigStartValue" SG_ 1059 WakeupRsn_SCCM 255;
BA_ "RID" SG_ 1059 WakeupRsn_SCCM "9742";
BA_ "FlexKomComment" SG_ 464 DRV_SEATBELT "Drivers seat belt status";
BA_ "FlexKomIsMotorola" SG_ 464 DRV_SEATBELT 1;
BA_ "FlexKomSID" SG_ 464 DRV_SEATBELT 330;
BA_ "FlexKomSigLaenge" SG_ 464 DRV_SEATBELT 2;
BA_ "FlexKomSigName" SG_ 464 DRV_SEATBELT "DRV_SEATBELT";
BA_ "FlexKomSigStartPos" SG_ 464 DRV_SEATBELT 17;
BA_ "FlexKomSigStartValue" SG_ 464 DRV_SEATBELT "03h";
BA_ "GenSigCycleTime" SG_ 464 DRV_SEATBELT 1000;
BA_ "GenSigSendType" SG_ 464 DRV_SEATBELT 5;
BA_ "GenSigSNA" SG_ 464 DRV_SEATBELT "3h";
BA_ "GenSigStartValue" SG_ 464 DRV_SEATBELT 3;
BA_ "GenSigTimeout_CBC" SG_ 464 DRV_SEATBELT 10500;
BA_ "GenSigTimeout_ETM" SG_ 464 DRV_SEATBELT 10500;
BA_ "GenSigTimeout_IC" SG_ 464 DRV_SEATBELT 10500;
BA_ "GenSigTimeout_PTS" SG_ 464 DRV_SEATBELT 10500;
BA_ "RID" SG_ 464 DRV_SEATBELT "1107";
BA_ "FlexKomComment" SG_ 464 DrvSbltUnFltr "Drivers seat belt fault status - unfiltered";
BA_ "FlexKomIsMotorola" SG_ 464 DrvSbltUnFltr 1;
BA_ "FlexKomSID" SG_ 464 DrvSbltUnFltr 1814;
BA_ "FlexKomSigLaenge" SG_ 464 DrvSbltUnFltr 3;
BA_ "FlexKomSigName" SG_ 464 DrvSbltUnFltr "DrvSbltUnFltr";
BA_ "FlexKomSigStartPos" SG_ 464 DrvSbltUnFltr 15;
BA_ "FlexKomSigStartValue" SG_ 464 DrvSbltUnFltr "07h";
BA_ "GenSigCycleTime" SG_ 464 DrvSbltUnFltr 1000;
BA_ "GenSigSendType" SG_ 464 DrvSbltUnFltr 5;
BA_ "GenSigSNA" SG_ 464 DrvSbltUnFltr "7h";
BA_ "GenSigStartValue" SG_ 464 DrvSbltUnFltr 7;
BA_ "RID" SG_ 464 DrvSbltUnFltr "1973";
BA_ "FlexKomComment" SG_ 464 ORC_A1_Par "ORC_A1 even parity bit";
BA_ "FlexKomIsMotorola" SG_ 464 ORC_A1_Par 1;
BA_ "FlexKomSID" SG_ 464 ORC_A1_Par 1903;
BA_ "FlexKomSigLaenge" SG_ 464 ORC_A1_Par 1;
BA_ "FlexKomSigName" SG_ 464 ORC_A1_Par "ORC_A1_Par";
BA_ "FlexKomSigStartPos" SG_ 464 ORC_A1_Par 7;
BA_ "FlexKomSigStartValue" SG_ 464 ORC_A1_Par "00h";
BA_ "GenSigCycleTime" SG_ 464 ORC_A1_Par 1000;
BA_ "GenSigSendType" SG_ 464 ORC_A1_Par 5;
BA_ "GenSigSNA" SG_ 464 ORC_A1_Par "0h";
BA_ "RID" SG_ 464 ORC_A1_Par "1961";
BA_ "FlexKomComment" SG_ 464 ORC_A1_Tog "ORC_A1 toggle bit";
BA_ "FlexKomIsMotorola" SG_ 464 ORC_A1_Tog 1;
BA_ "FlexKomSID" SG_ 464 ORC_A1_Tog 1902;
BA_ "FlexKomSigLaenge" SG_ 464 ORC_A1_Tog 1;
BA_ "FlexKomSigName" SG_ 464 ORC_A1_Tog "ORC_A1_Tog";
BA_ "FlexKomSigStartPos" SG_ 464 ORC_A1_Tog 1;
BA_ "FlexKomSigStartValue" SG_ 464 ORC_A1_Tog "00h";
BA_ "GenSigCycleTime" SG_ 464 ORC_A1_Tog 1000;
BA_ "GenSigSendType" SG_ 464 ORC_A1_Tog 5;
BA_ "GenSigSNA" SG_ 464 ORC_A1_Tog "0h";
BA_ "RID" SG_ 464 ORC_A1_Tog "1970";
BA_ "FlexKomComment" SG_ 464 PSG_ODS_STAT "Passenger Occupant Detection Sensor Status";
BA_ "FlexKomIsMotorola" SG_ 464 PSG_ODS_STAT 1;
BA_ "FlexKomSID" SG_ 464 PSG_ODS_STAT 426;
BA_ "FlexKomSigLaenge" SG_ 464 PSG_ODS_STAT 2;
BA_ "FlexKomSigName" SG_ 464 PSG_ODS_STAT "PSG_ODS_STAT";
BA_ "FlexKomSigStartPos" SG_ 464 PSG_ODS_STAT 27;
BA_ "FlexKomSigStartValue" SG_ 464 PSG_ODS_STAT "03h";
BA_ "GenSigCycleTime" SG_ 464 PSG_ODS_STAT 1000;
BA_ "GenSigSendType" SG_ 464 PSG_ODS_STAT 5;
BA_ "GenSigSNA" SG_ 464 PSG_ODS_STAT "3h";
BA_ "GenSigStartValue" SG_ 464 PSG_ODS_STAT 3;
BA_ "GenSigTimeout_CBC" SG_ 464 PSG_ODS_STAT 10500;
BA_ "GenSigTimeout_ETM" SG_ 464 PSG_ODS_STAT 10500;
BA_ "GenSigTimeout_IC" SG_ 464 PSG_ODS_STAT 10500;
BA_ "RID" SG_ 464 PSG_ODS_STAT "1142";
BA_ "FlexKomComment" SG_ 464 PSG_SEATBELT "Passengers seat belt status";
BA_ "FlexKomIsMotorola" SG_ 464 PSG_SEATBELT 1;
BA_ "FlexKomSID" SG_ 464 PSG_SEATBELT 331;
BA_ "FlexKomSigLaenge" SG_ 464 PSG_SEATBELT 2;
BA_ "FlexKomSigName" SG_ 464 PSG_SEATBELT "PSG_SEATBELT";
BA_ "FlexKomSigStartPos" SG_ 464 PSG_SEATBELT 19;
BA_ "FlexKomSigStartValue" SG_ 464 PSG_SEATBELT "03h";
BA_ "GenSigCycleTime" SG_ 464 PSG_SEATBELT 1000;
BA_ "GenSigSendType" SG_ 464 PSG_SEATBELT 5;
BA_ "GenSigSNA" SG_ 464 PSG_SEATBELT "3h";
BA_ "GenSigStartValue" SG_ 464 PSG_SEATBELT 3;
BA_ "GenSigTimeout_CBC" SG_ 464 PSG_SEATBELT 10500;
BA_ "GenSigTimeout_ETM" SG_ 464 PSG_SEATBELT 10500;
BA_ "GenSigTimeout_IC" SG_ 464 PSG_SEATBELT 10500;
BA_ "RID" SG_ 464 PSG_SEATBELT "1160";
BA_ "FlexKomComment" SG_ 464 SRS_IndLmp_Rq "SRS indication lamp request";
BA_ "FlexKomIsMotorola" SG_ 464 SRS_IndLmp_Rq 1;
BA_ "FlexKomSID" SG_ 464 SRS_IndLmp_Rq 329;
BA_ "FlexKomSigLaenge" SG_ 464 SRS_IndLmp_Rq 2;
BA_ "FlexKomSigName" SG_ 464 SRS_IndLmp_Rq "SRS_IndLmp_Rq";
BA_ "FlexKomSigStartPos" SG_ 464 SRS_IndLmp_Rq 3;
BA_ "FlexKomSigStartValue" SG_ 464 SRS_IndLmp_Rq "01h";
BA_ "GenSigCycleTime" SG_ 464 SRS_IndLmp_Rq 1000;
BA_ "GenSigSendType" SG_ 464 SRS_IndLmp_Rq 5;
BA_ "GenSigSNA" SG_ 464 SRS_IndLmp_Rq "3h";
BA_ "GenSigStartValue" SG_ 464 SRS_IndLmp_Rq 1;
BA_ "GenSigTimeout_CBC" SG_ 464 SRS_IndLmp_Rq 5500;
BA_ "GenSigTimeout_ETM" SG_ 464 SRS_IndLmp_Rq 10500;
BA_ "GenSigTimeout_IC" SG_ 464 SRS_IndLmp_Rq 10500;
BA_ "RID" SG_ 464 SRS_IndLmp_Rq "1152";
BA_ "FlexKomComment" SG_ 826 PTS_AlrFC "Park assist front center warnings";
BA_ "FlexKomIsMotorola" SG_ 826 PTS_AlrFC 1;
BA_ "FlexKomSID" SG_ 826 PTS_AlrFC 1121;
BA_ "FlexKomSigLaenge" SG_ 826 PTS_AlrFC 8;
BA_ "FlexKomSigName" SG_ 826 PTS_AlrFC "PTS_FC";
BA_ "FlexKomSigStartPos" SG_ 826 PTS_AlrFC 47;
BA_ "FlexKomSigStartValue" SG_ 826 PTS_AlrFC "F0h";
BA_ "GenSigCycleTime" SG_ 826 PTS_AlrFC 500;
BA_ "GenSigSendType" SG_ 826 PTS_AlrFC 5;
BA_ "GenSigSNA" SG_ 826 PTS_AlrFC "Fh";
BA_ "GenSigTimeout_CBC" SG_ 826 PTS_AlrFC 5250;
BA_ "GenSigTimeout_IC" SG_ 826 PTS_AlrFC 5250;
BA_ "RID" SG_ 826 PTS_AlrFC "2103";
BA_ "FlexKomComment" SG_ 826 PTS_AlrFL "Park assist front left warnings";
BA_ "FlexKomIsMotorola" SG_ 826 PTS_AlrFL 1;
BA_ "FlexKomSID" SG_ 826 PTS_AlrFL 1117;
BA_ "FlexKomSigLaenge" SG_ 826 PTS_AlrFL 8;
BA_ "FlexKomSigName" SG_ 826 PTS_AlrFL "PTS_FL";
BA_ "FlexKomSigStartPos" SG_ 826 PTS_AlrFL 15;
BA_ "FlexKomSigStartValue" SG_ 826 PTS_AlrFL "F0h";
BA_ "GenSigCycleTime" SG_ 826 PTS_AlrFL 500;
BA_ "GenSigSendType" SG_ 826 PTS_AlrFL 5;
BA_ "GenSigSNA" SG_ 826 PTS_AlrFL "Fh";
BA_ "GenSigTimeout_CBC" SG_ 826 PTS_AlrFL 5250;
BA_ "GenSigTimeout_IC" SG_ 826 PTS_AlrFL 5250;
BA_ "RID" SG_ 826 PTS_AlrFL "2104";
BA_ "FlexKomComment" SG_ 826 PTS_AlrFR "Park assist front right warnings";
BA_ "FlexKomIsMotorola" SG_ 826 PTS_AlrFR 1;
BA_ "FlexKomSID" SG_ 826 PTS_AlrFR 1118;
BA_ "FlexKomSigLaenge" SG_ 826 PTS_AlrFR 8;
BA_ "FlexKomSigName" SG_ 826 PTS_AlrFR "PTS_FR";
BA_ "FlexKomSigStartPos" SG_ 826 PTS_AlrFR 23;
BA_ "FlexKomSigStartValue" SG_ 826 PTS_AlrFR "F0h";
BA_ "GenSigCycleTime" SG_ 826 PTS_AlrFR 500;
BA_ "GenSigSendType" SG_ 826 PTS_AlrFR 5;
BA_ "GenSigSNA" SG_ 826 PTS_AlrFR "Fh";
BA_ "GenSigTimeout_CBC" SG_ 826 PTS_AlrFR 5250;
BA_ "GenSigTimeout_IC" SG_ 826 PTS_AlrFR 5250;
BA_ "RID" SG_ 826 PTS_AlrFR "2100";
BA_ "FlexKomComment" SG_ 826 PTS_AlrRC "Park assist rear center warnings";
BA_ "FlexKomIsMotorola" SG_ 826 PTS_AlrRC 1;
BA_ "FlexKomSID" SG_ 826 PTS_AlrRC 1123;
BA_ "FlexKomSigLaenge" SG_ 826 PTS_AlrRC 8;
BA_ "FlexKomSigName" SG_ 826 PTS_AlrRC "PTS_RC";
BA_ "FlexKomSigStartPos" SG_ 826 PTS_AlrRC 55;
BA_ "FlexKomSigStartValue" SG_ 826 PTS_AlrRC "F0h";
BA_ "GenSigCycleTime" SG_ 826 PTS_AlrRC 500;
BA_ "GenSigSendType" SG_ 826 PTS_AlrRC 5;
BA_ "GenSigSNA" SG_ 826 PTS_AlrRC "Fh";
BA_ "GenSigTimeout_CBC" SG_ 826 PTS_AlrRC 5250;
BA_ "GenSigTimeout_IC" SG_ 826 PTS_AlrRC 5250;
BA_ "RID" SG_ 826 PTS_AlrRC "1026 2098";
BA_ "FlexKomComment" SG_ 826 PTS_AlrRL "Park assist rear left warnings";
BA_ "FlexKomIsMotorola" SG_ 826 PTS_AlrRL 1;
BA_ "FlexKomSID" SG_ 826 PTS_AlrRL 1119;
BA_ "FlexKomSigLaenge" SG_ 826 PTS_AlrRL 8;
BA_ "FlexKomSigName" SG_ 826 PTS_AlrRL "PTS_RL";
BA_ "FlexKomSigStartPos" SG_ 826 PTS_AlrRL 31;
BA_ "FlexKomSigStartValue" SG_ 826 PTS_AlrRL "F0h";
BA_ "GenSigCycleTime" SG_ 826 PTS_AlrRL 500;
BA_ "GenSigSendType" SG_ 826 PTS_AlrRL 5;
BA_ "GenSigSNA" SG_ 826 PTS_AlrRL "Fh";
BA_ "GenSigTimeout_CBC" SG_ 826 PTS_AlrRL 5250;
BA_ "GenSigTimeout_IC" SG_ 826 PTS_AlrRL 5250;
BA_ "RID" SG_ 826 PTS_AlrRL "1009 2101";
BA_ "FlexKomComment" SG_ 826 PTS_AlrRR "Park assist rear right warnings";
BA_ "FlexKomIsMotorola" SG_ 826 PTS_AlrRR 1;
BA_ "FlexKomSID" SG_ 826 PTS_AlrRR 1120;
BA_ "FlexKomSigLaenge" SG_ 826 PTS_AlrRR 8;
BA_ "FlexKomSigName" SG_ 826 PTS_AlrRR "PTS_RR";
BA_ "FlexKomSigStartPos" SG_ 826 PTS_AlrRR 39;
BA_ "FlexKomSigStartValue" SG_ 826 PTS_AlrRR "F0h";
BA_ "GenSigCycleTime" SG_ 826 PTS_AlrRR 500;
BA_ "GenSigSendType" SG_ 826 PTS_AlrRR 5;
BA_ "GenSigSNA" SG_ 826 PTS_AlrRR "Fh";
BA_ "GenSigTimeout_CBC" SG_ 826 PTS_AlrRR 5250;
BA_ "GenSigTimeout_IC" SG_ 826 PTS_AlrRR 5250;
BA_ "RID" SG_ 826 PTS_AlrRR "1005 2099";
BA_ "FlexKomComment" SG_ 826 PTS_CFG_STAT "Park assist configuration status";
BA_ "FlexKomIsMotorola" SG_ 826 PTS_CFG_STAT 1;
BA_ "FlexKomSID" SG_ 826 PTS_CFG_STAT 1114;
BA_ "FlexKomSigLaenge" SG_ 826 PTS_CFG_STAT 2;
BA_ "FlexKomSigName" SG_ 826 PTS_CFG_STAT "PTS_CFG_STAT";
BA_ "FlexKomSigStartPos" SG_ 826 PTS_CFG_STAT 2;
BA_ "FlexKomSigStartValue" SG_ 826 PTS_CFG_STAT "00h";
BA_ "GenSigCycleTime" SG_ 826 PTS_CFG_STAT 500;
BA_ "GenSigSendType" SG_ 826 PTS_CFG_STAT 5;
BA_ "GenSigSNA" SG_ 826 PTS_CFG_STAT "3h";
BA_ "GenSigTimeout_CBC" SG_ 826 PTS_CFG_STAT 5250;
BA_ "GenSigTimeout_IC" SG_ 826 PTS_CFG_STAT 5250;
BA_ "RID" SG_ 826 PTS_CFG_STAT "1181";
BA_ "FlexKomComment" SG_ 826 PTS_FT_NA "Front park assist not available - blinded sensor; ";
BA_ "FlexKomIsMotorola" SG_ 826 PTS_FT_NA 1;
BA_ "FlexKomSID" SG_ 826 PTS_FT_NA 1314;
BA_ "FlexKomSigLaenge" SG_ 826 PTS_FT_NA 1;
BA_ "FlexKomSigName" SG_ 826 PTS_FT_NA "PTS_FT_NA";
BA_ "FlexKomSigStartPos" SG_ 826 PTS_FT_NA 3;
BA_ "FlexKomSigStartValue" SG_ 826 PTS_FT_NA "00h";
BA_ "GenSigCycleTime" SG_ 826 PTS_FT_NA 500;
BA_ "GenSigSendType" SG_ 826 PTS_FT_NA 5;
BA_ "GenSigSNA" SG_ 826 PTS_FT_NA "0h";
BA_ "GenSigTimeout_IC" SG_ 826 PTS_FT_NA 5250;
BA_ "FlexKomComment" SG_ 826 PTS_FT_SRV "Front PTS sensor service request; True = [1]";
BA_ "FlexKomIsMotorola" SG_ 826 PTS_FT_SRV 1;
BA_ "FlexKomSID" SG_ 826 PTS_FT_SRV 1354;
BA_ "FlexKomSigLaenge" SG_ 826 PTS_FT_SRV 1;
BA_ "FlexKomSigName" SG_ 826 PTS_FT_SRV "PTS_FT_SRV";
BA_ "FlexKomSigStartPos" SG_ 826 PTS_FT_SRV 58;
BA_ "FlexKomSigStartValue" SG_ 826 PTS_FT_SRV "00h";
BA_ "GenSigCycleTime" SG_ 826 PTS_FT_SRV 500;
BA_ "GenSigSendType" SG_ 826 PTS_FT_SRV 5;
BA_ "GenSigSNA" SG_ 826 PTS_FT_SRV "0h";
BA_ "GenSigTimeout_IC" SG_ 826 PTS_FT_SRV 5250;
BA_ "FlexKomComment" SG_ 826 PTS_GraphicFC "Park assist front center warnings";
BA_ "FlexKomIsMotorola" SG_ 826 PTS_GraphicFC 1;
BA_ "FlexKomSID" SG_ 826 PTS_GraphicFC 1121;
BA_ "FlexKomSigLaenge" SG_ 826 PTS_GraphicFC 8;
BA_ "FlexKomSigName" SG_ 826 PTS_GraphicFC "PTS_FC";
BA_ "FlexKomSigStartPos" SG_ 826 PTS_GraphicFC 47;
BA_ "FlexKomSigStartValue" SG_ 826 PTS_GraphicFC "F0h";
BA_ "GenSigCycleTime" SG_ 826 PTS_GraphicFC 500;
BA_ "GenSigSendType" SG_ 826 PTS_GraphicFC 5;
BA_ "GenSigSNA" SG_ 826 PTS_GraphicFC "3h";
BA_ "GenSigStartValue" SG_ 826 PTS_GraphicFC 3;
BA_ "GenSigTimeout_IC" SG_ 826 PTS_GraphicFC 5250;
BA_ "FlexKomComment" SG_ 826 PTS_GraphicFL "Park assist front left warnings";
BA_ "FlexKomIsMotorola" SG_ 826 PTS_GraphicFL 1;
BA_ "FlexKomSID" SG_ 826 PTS_GraphicFL 1117;
BA_ "FlexKomSigLaenge" SG_ 826 PTS_GraphicFL 8;
BA_ "FlexKomSigName" SG_ 826 PTS_GraphicFL "PTS_FL";
BA_ "FlexKomSigStartPos" SG_ 826 PTS_GraphicFL 15;
BA_ "FlexKomSigStartValue" SG_ 826 PTS_GraphicFL "F0h";
BA_ "GenSigCycleTime" SG_ 826 PTS_GraphicFL 500;
BA_ "GenSigSendType" SG_ 826 PTS_GraphicFL 5;
BA_ "GenSigSNA" SG_ 826 PTS_GraphicFL "3h";
BA_ "GenSigStartValue" SG_ 826 PTS_GraphicFL 3;
BA_ "GenSigTimeout_IC" SG_ 826 PTS_GraphicFL 5250;
BA_ "FlexKomComment" SG_ 826 PTS_GraphicFR "Park assist front right warnings";
BA_ "FlexKomIsMotorola" SG_ 826 PTS_GraphicFR 1;
BA_ "FlexKomSID" SG_ 826 PTS_GraphicFR 1118;
BA_ "FlexKomSigLaenge" SG_ 826 PTS_GraphicFR 8;
BA_ "FlexKomSigName" SG_ 826 PTS_GraphicFR "PTS_FR";
BA_ "FlexKomSigStartPos" SG_ 826 PTS_GraphicFR 23;
BA_ "FlexKomSigStartValue" SG_ 826 PTS_GraphicFR "F0h";
BA_ "GenSigCycleTime" SG_ 826 PTS_GraphicFR 500;
BA_ "GenSigSendType" SG_ 826 PTS_GraphicFR 5;
BA_ "GenSigSNA" SG_ 826 PTS_GraphicFR "3h";
BA_ "GenSigStartValue" SG_ 826 PTS_GraphicFR 3;
BA_ "GenSigTimeout_IC" SG_ 826 PTS_GraphicFR 5250;
BA_ "FlexKomComment" SG_ 826 PTS_GraphicRC "Park assist rear center warnings";
BA_ "FlexKomIsMotorola" SG_ 826 PTS_GraphicRC 1;
BA_ "FlexKomSID" SG_ 826 PTS_GraphicRC 1123;
BA_ "FlexKomSigLaenge" SG_ 826 PTS_GraphicRC 8;
BA_ "FlexKomSigName" SG_ 826 PTS_GraphicRC "PTS_RC";
BA_ "FlexKomSigStartPos" SG_ 826 PTS_GraphicRC 55;
BA_ "FlexKomSigStartValue" SG_ 826 PTS_GraphicRC "F0h";
BA_ "GenSigCycleTime" SG_ 826 PTS_GraphicRC 500;
BA_ "GenSigSendType" SG_ 826 PTS_GraphicRC 5;
BA_ "GenSigSNA" SG_ 826 PTS_GraphicRC "3h";
BA_ "GenSigStartValue" SG_ 826 PTS_GraphicRC 3;
BA_ "GenSigTimeout_IC" SG_ 826 PTS_GraphicRC 5250;
BA_ "FlexKomComment" SG_ 826 PTS_GraphicRL "Park assist rear left warnings";
BA_ "FlexKomIsMotorola" SG_ 826 PTS_GraphicRL 1;
BA_ "FlexKomSID" SG_ 826 PTS_GraphicRL 1119;
BA_ "FlexKomSigLaenge" SG_ 826 PTS_GraphicRL 8;
BA_ "FlexKomSigName" SG_ 826 PTS_GraphicRL "PTS_RL";
BA_ "FlexKomSigStartPos" SG_ 826 PTS_GraphicRL 31;
BA_ "FlexKomSigStartValue" SG_ 826 PTS_GraphicRL "F0h";
BA_ "GenSigCycleTime" SG_ 826 PTS_GraphicRL 500;
BA_ "GenSigSendType" SG_ 826 PTS_GraphicRL 5;
BA_ "GenSigSNA" SG_ 826 PTS_GraphicRL "3h";
BA_ "GenSigStartValue" SG_ 826 PTS_GraphicRL 3;
BA_ "GenSigTimeout_IC" SG_ 826 PTS_GraphicRL 5250;
BA_ "FlexKomComment" SG_ 826 PTS_GraphicRR "Park assist rear right warnings";
BA_ "FlexKomIsMotorola" SG_ 826 PTS_GraphicRR 1;
BA_ "FlexKomSID" SG_ 826 PTS_GraphicRR 1120;
BA_ "FlexKomSigLaenge" SG_ 826 PTS_GraphicRR 8;
BA_ "FlexKomSigName" SG_ 826 PTS_GraphicRR "PTS_RR";
BA_ "FlexKomSigStartPos" SG_ 826 PTS_GraphicRR 39;
BA_ "FlexKomSigStartValue" SG_ 826 PTS_GraphicRR "F0h";
BA_ "GenSigCycleTime" SG_ 826 PTS_GraphicRR 500;
BA_ "GenSigSendType" SG_ 826 PTS_GraphicRR 5;
BA_ "GenSigSNA" SG_ 826 PTS_GraphicRR "3h";
BA_ "GenSigStartValue" SG_ 826 PTS_GraphicRR 3;
BA_ "GenSigTimeout_IC" SG_ 826 PTS_GraphicRR 5250;
BA_ "FlexKomComment" SG_ 826 PTS_RR_NA "Rear park assist not available - blinded sensor; T";
BA_ "FlexKomIsMotorola" SG_ 826 PTS_RR_NA 1;
BA_ "FlexKomSID" SG_ 826 PTS_RR_NA 1315;
BA_ "FlexKomSigLaenge" SG_ 826 PTS_RR_NA 1;
BA_ "FlexKomSigName" SG_ 826 PTS_RR_NA "PTS_RR_NA";
BA_ "FlexKomSigStartPos" SG_ 826 PTS_RR_NA 4;
BA_ "FlexKomSigStartValue" SG_ 826 PTS_RR_NA "00h";
BA_ "GenSigCycleTime" SG_ 826 PTS_RR_NA 500;
BA_ "GenSigSendType" SG_ 826 PTS_RR_NA 5;
BA_ "GenSigSNA" SG_ 826 PTS_RR_NA "0h";
BA_ "GenSigTimeout_IC" SG_ 826 PTS_RR_NA 5250;
BA_ "FlexKomComment" SG_ 826 PTS_RR_SRV "Rear PTS sensor service request; True = [1]";
BA_ "FlexKomIsMotorola" SG_ 826 PTS_RR_SRV 1;
BA_ "FlexKomSID" SG_ 826 PTS_RR_SRV 1353;
BA_ "FlexKomSigLaenge" SG_ 826 PTS_RR_SRV 1;
BA_ "FlexKomSigName" SG_ 826 PTS_RR_SRV "PTS_RR_SRV";
BA_ "FlexKomSigStartPos" SG_ 826 PTS_RR_SRV 59;
BA_ "FlexKomSigStartValue" SG_ 826 PTS_RR_SRV "00h";
BA_ "GenSigCycleTime" SG_ 826 PTS_RR_SRV 500;
BA_ "GenSigSendType" SG_ 826 PTS_RR_SRV 5;
BA_ "GenSigSNA" SG_ 826 PTS_RR_SRV "0h";
BA_ "GenSigTimeout_IC" SG_ 826 PTS_RR_SRV 5250;
BA_ "FlexKomComment" SG_ 826 PTS_SRV_RQ "PTS service warning request; True = [1]";
BA_ "FlexKomIsMotorola" SG_ 826 PTS_SRV_RQ 1;
BA_ "FlexKomSID" SG_ 826 PTS_SRV_RQ 54;
BA_ "FlexKomSigLaenge" SG_ 826 PTS_SRV_RQ 1;
BA_ "FlexKomSigName" SG_ 826 PTS_SRV_RQ "PTS_SRV_RQ";
BA_ "FlexKomSigStartPos" SG_ 826 PTS_SRV_RQ 5;
BA_ "FlexKomSigStartValue" SG_ 826 PTS_SRV_RQ "00h";
BA_ "GenSigCycleTime" SG_ 826 PTS_SRV_RQ 500;
BA_ "GenSigSendType" SG_ 826 PTS_SRV_RQ 5;
BA_ "GenSigSNA" SG_ 826 PTS_SRV_RQ "0h";
BA_ "GenSigTimeout_IC" SG_ 826 PTS_SRV_RQ 5250;
BA_ "FlexKomComment" SG_ 826 PTS_STAT "Park Assist System - LED control status";
BA_ "FlexKomIsMotorola" SG_ 826 PTS_STAT 1;
BA_ "FlexKomSID" SG_ 826 PTS_STAT 1862;
BA_ "FlexKomSigLaenge" SG_ 826 PTS_STAT 2;
BA_ "FlexKomSigName" SG_ 826 PTS_STAT "PTS_STAT";
BA_ "FlexKomSigStartPos" SG_ 826 PTS_STAT 61;
BA_ "FlexKomSigStartValue" SG_ 826 PTS_STAT "00h";
BA_ "GenSigCycleTime" SG_ 826 PTS_STAT 500;
BA_ "GenSigSendType" SG_ 826 PTS_STAT 5;
BA_ "GenSigSNA" SG_ 826 PTS_STAT "3h";
BA_ "GenSigTimeout_CBC" SG_ 826 PTS_STAT 5250;
BA_ "RID" SG_ 826 PTS_STAT "1877 1939 5117";
BA_ "FlexKomComment" SG_ 608 CRC_PTS_2 "PTS 2 message packet";
BA_ "FlexKomIsMotorola" SG_ 608 CRC_PTS_2 1;
BA_ "FlexKomSID" SG_ 608 CRC_PTS_2 1954;
BA_ "FlexKomSigLaenge" SG_ 608 CRC_PTS_2 64;
BA_ "FlexKomSigName" SG_ 608 CRC_PTS_2 "PTS_2_Pkt";
BA_ "FlexKomSigStartPos" SG_ 608 CRC_PTS_2 7;
BA_ "FlexKomSigStartValue" SG_ 608 CRC_PTS_2 "FF001400000000FFh";
BA_ "GenSigCycleTime" SG_ 608 CRC_PTS_2 500;
BA_ "GenSigSendType" SG_ 608 CRC_PTS_2 5;
BA_ "GenSigSNA" SG_ 608 CRC_PTS_2 "FFh";
BA_ "GenSigStartValue" SG_ 608 CRC_PTS_2 255;
BA_ "FlexKomComment" SG_ 608 MC_PTS_2 "PTS 2 message packet";
BA_ "FlexKomIsMotorola" SG_ 608 MC_PTS_2 1;
BA_ "FlexKomSID" SG_ 608 MC_PTS_2 1954;
BA_ "FlexKomSigLaenge" SG_ 608 MC_PTS_2 64;
BA_ "FlexKomSigName" SG_ 608 MC_PTS_2 "PTS_2_Pkt";
BA_ "FlexKomSigStartPos" SG_ 608 MC_PTS_2 7;
BA_ "FlexKomSigStartValue" SG_ 608 MC_PTS_2 "FF001400000000FFh";
BA_ "GenSigCycleTime" SG_ 608 MC_PTS_2 500;
BA_ "GenSigSendType" SG_ 608 MC_PTS_2 5;
BA_ "GenSigSNA" SG_ 608 MC_PTS_2 "0h";
BA_ "FlexKomComment" SG_ 608 PTS_CFG_STAT_TeenKey "PTS 2 message packet";
BA_ "FlexKomIsMotorola" SG_ 608 PTS_CFG_STAT_TeenKey 1;
BA_ "FlexKomSID" SG_ 608 PTS_CFG_STAT_TeenKey 1954;
BA_ "FlexKomSigLaenge" SG_ 608 PTS_CFG_STAT_TeenKey 64;
BA_ "FlexKomSigName" SG_ 608 PTS_CFG_STAT_TeenKey "PTS_2_Pkt";
BA_ "FlexKomSigStartPos" SG_ 608 PTS_CFG_STAT_TeenKey 7;
BA_ "FlexKomSigStartValue" SG_ 608 PTS_CFG_STAT_TeenKey "FF001400000000FFh";
BA_ "GenSigCycleTime" SG_ 608 PTS_CFG_STAT_TeenKey 500;
BA_ "GenSigSendType" SG_ 608 PTS_CFG_STAT_TeenKey 5;
BA_ "GenSigSNA" SG_ 608 PTS_CFG_STAT_TeenKey "3h";
BA_ "GenSigTimeout_CBC" SG_ 608 PTS_CFG_STAT_TeenKey 5250;
BA_ "RID" SG_ 608 PTS_CFG_STAT_TeenKey "2168";
BA_ "FlexKomComment" SG_ 608 PTS_FT_TEMP_NA "PTS 2 message packet";
BA_ "FlexKomIsMotorola" SG_ 608 PTS_FT_TEMP_NA 1;
BA_ "FlexKomSID" SG_ 608 PTS_FT_TEMP_NA 1954;
BA_ "FlexKomSigLaenge" SG_ 608 PTS_FT_TEMP_NA 64;
BA_ "FlexKomSigName" SG_ 608 PTS_FT_TEMP_NA "PTS_2_Pkt";
BA_ "FlexKomSigStartPos" SG_ 608 PTS_FT_TEMP_NA 7;
BA_ "FlexKomSigStartValue" SG_ 608 PTS_FT_TEMP_NA "FF001400000000FFh";
BA_ "GenSigCycleTime" SG_ 608 PTS_FT_TEMP_NA 500;
BA_ "GenSigSendType" SG_ 608 PTS_FT_TEMP_NA 5;
BA_ "GenSigSNA" SG_ 608 PTS_FT_TEMP_NA "0h";
BA_ "GenSigTimeout_IC" SG_ 608 PTS_FT_TEMP_NA 5250;
BA_ "FlexKomComment" SG_ 608 PTS_FT_VOL_TeenKey "PTS 2 message packet";
BA_ "FlexKomIsMotorola" SG_ 608 PTS_FT_VOL_TeenKey 1;
BA_ "FlexKomSID" SG_ 608 PTS_FT_VOL_TeenKey 1954;
BA_ "FlexKomSigLaenge" SG_ 608 PTS_FT_VOL_TeenKey 64;
BA_ "FlexKomSigName" SG_ 608 PTS_FT_VOL_TeenKey "PTS_2_Pkt";
BA_ "FlexKomSigStartPos" SG_ 608 PTS_FT_VOL_TeenKey 7;
BA_ "FlexKomSigStartValue" SG_ 608 PTS_FT_VOL_TeenKey "FF001400000000FFh";
BA_ "GenSigCycleTime" SG_ 608 PTS_FT_VOL_TeenKey 500;
BA_ "GenSigSendType" SG_ 608 PTS_FT_VOL_TeenKey 5;
BA_ "GenSigSNA" SG_ 608 PTS_FT_VOL_TeenKey "3h";
BA_ "GenSigStartValue" SG_ 608 PTS_FT_VOL_TeenKey 1;
BA_ "GenSigTimeout_CBC" SG_ 608 PTS_FT_VOL_TeenKey 5250;
BA_ "RID" SG_ 608 PTS_FT_VOL_TeenKey "2166";
BA_ "FlexKomComment" SG_ 608 PTS_Off_Status "PTS 2 message packet";
BA_ "FlexKomIsMotorola" SG_ 608 PTS_Off_Status 1;
BA_ "FlexKomSID" SG_ 608 PTS_Off_Status 1954;
BA_ "FlexKomSigLaenge" SG_ 608 PTS_Off_Status 64;
BA_ "FlexKomSigName" SG_ 608 PTS_Off_Status "PTS_2_Pkt";
BA_ "FlexKomSigStartPos" SG_ 608 PTS_Off_Status 7;
BA_ "FlexKomSigStartValue" SG_ 608 PTS_Off_Status "FF001400000000FFh";
BA_ "GenSigCycleTime" SG_ 608 PTS_Off_Status 500;
BA_ "GenSigSendType" SG_ 608 PTS_Off_Status 5;
BA_ "GenSigSNA" SG_ 608 PTS_Off_Status "0h";
BA_ "GenSigTimeout_IC" SG_ 608 PTS_Off_Status 5250;
BA_ "FlexKomComment" SG_ 608 PTS_PopUpRqst "PTS 2 message packet";
BA_ "FlexKomIsMotorola" SG_ 608 PTS_PopUpRqst 1;
BA_ "FlexKomSID" SG_ 608 PTS_PopUpRqst 1954;
BA_ "FlexKomSigLaenge" SG_ 608 PTS_PopUpRqst 64;
BA_ "FlexKomSigName" SG_ 608 PTS_PopUpRqst "PTS_2_Pkt";
BA_ "FlexKomSigStartPos" SG_ 608 PTS_PopUpRqst 7;
BA_ "FlexKomSigStartValue" SG_ 608 PTS_PopUpRqst "FF001400000000FFh";
BA_ "GenSigCycleTime" SG_ 608 PTS_PopUpRqst 500;
BA_ "GenSigSendType" SG_ 608 PTS_PopUpRqst 5;
BA_ "GenSigSNA" SG_ 608 PTS_PopUpRqst "FFh";
BA_ "GenSigTimeout_IC" SG_ 608 PTS_PopUpRqst 5250;
BA_ "FlexKomComment" SG_ 608 PTS_RR_TEMP_NA "PTS 2 message packet";
BA_ "FlexKomIsMotorola" SG_ 608 PTS_RR_TEMP_NA 1;
BA_ "FlexKomSID" SG_ 608 PTS_RR_TEMP_NA 1954;
BA_ "FlexKomSigLaenge" SG_ 608 PTS_RR_TEMP_NA 64;
BA_ "FlexKomSigName" SG_ 608 PTS_RR_TEMP_NA "PTS_2_Pkt";
BA_ "FlexKomSigStartPos" SG_ 608 PTS_RR_TEMP_NA 7;
BA_ "FlexKomSigStartValue" SG_ 608 PTS_RR_TEMP_NA "FF001400000000FFh";
BA_ "GenSigCycleTime" SG_ 608 PTS_RR_TEMP_NA 500;
BA_ "GenSigSendType" SG_ 608 PTS_RR_TEMP_NA 5;
BA_ "GenSigSNA" SG_ 608 PTS_RR_TEMP_NA "0h";
BA_ "GenSigTimeout_IC" SG_ 608 PTS_RR_TEMP_NA 5250;
BA_ "FlexKomComment" SG_ 608 PTS_RR_VOL_TeenKey "PTS 2 message packet";
BA_ "FlexKomIsMotorola" SG_ 608 PTS_RR_VOL_TeenKey 1;
BA_ "FlexKomSID" SG_ 608 PTS_RR_VOL_TeenKey 1954;
BA_ "FlexKomSigLaenge" SG_ 608 PTS_RR_VOL_TeenKey 64;
BA_ "FlexKomSigName" SG_ 608 PTS_RR_VOL_TeenKey "PTS_2_Pkt";
BA_ "FlexKomSigStartPos" SG_ 608 PTS_RR_VOL_TeenKey 7;
BA_ "FlexKomSigStartValue" SG_ 608 PTS_RR_VOL_TeenKey "FF001400000000FFh";
BA_ "GenSigCycleTime" SG_ 608 PTS_RR_VOL_TeenKey 500;
BA_ "GenSigSendType" SG_ 608 PTS_RR_VOL_TeenKey 5;
BA_ "GenSigSNA" SG_ 608 PTS_RR_VOL_TeenKey "3h";
BA_ "GenSigStartValue" SG_ 608 PTS_RR_VOL_TeenKey 1;
BA_ "GenSigTimeout_CBC" SG_ 608 PTS_RR_VOL_TeenKey 5250;
BA_ "RID" SG_ 608 PTS_RR_VOL_TeenKey "2170";
BA_ "FlexKomComment" SG_ 608 RR_PTS_Brk_RqSts "PTS 2 message packet";
BA_ "FlexKomIsMotorola" SG_ 608 RR_PTS_Brk_RqSts 1;
BA_ "FlexKomSID" SG_ 608 RR_PTS_Brk_RqSts 1954;
BA_ "FlexKomSigLaenge" SG_ 608 RR_PTS_Brk_RqSts 64;
BA_ "FlexKomSigName" SG_ 608 RR_PTS_Brk_RqSts "PTS_2_Pkt";
BA_ "FlexKomSigStartPos" SG_ 608 RR_PTS_Brk_RqSts 7;
BA_ "FlexKomSigStartValue" SG_ 608 RR_PTS_Brk_RqSts "FF001400000000FFh";
BA_ "GenSigCycleTime" SG_ 608 RR_PTS_Brk_RqSts 500;
BA_ "GenSigSendType" SG_ 608 RR_PTS_Brk_RqSts 5;
BA_ "GenSigSNA" SG_ 608 RR_PTS_Brk_RqSts "0h";
BA_ "FlexKomComment" SG_ 608 RR_PTS_Dist "PTS 2 message packet";
BA_ "FlexKomIsMotorola" SG_ 608 RR_PTS_Dist 1;
BA_ "FlexKomSID" SG_ 608 RR_PTS_Dist 1954;
BA_ "FlexKomSigLaenge" SG_ 608 RR_PTS_Dist 64;
BA_ "FlexKomSigName" SG_ 608 RR_PTS_Dist "PTS_2_Pkt";
BA_ "FlexKomSigStartPos" SG_ 608 RR_PTS_Dist 7;
BA_ "FlexKomSigStartValue" SG_ 608 RR_PTS_Dist "FF001400000000FFh";
BA_ "GenSigCycleTime" SG_ 608 RR_PTS_Dist 500;
BA_ "GenSigSendType" SG_ 608 RR_PTS_Dist 5;
BA_ "GenSigSNA" SG_ 608 RR_PTS_Dist "FFh";
BA_ "GenSigStartValue" SG_ 608 RR_PTS_Dist 255;
BA_ "FlexKomComment" SG_ 608 RR_PTS_StopControlSts "PTS 2 message packet";
BA_ "FlexKomIsMotorola" SG_ 608 RR_PTS_StopControlSts 1;
BA_ "FlexKomSID" SG_ 608 RR_PTS_StopControlSts 1954;
BA_ "FlexKomSigLaenge" SG_ 608 RR_PTS_StopControlSts 64;
BA_ "FlexKomSigName" SG_ 608 RR_PTS_StopControlSts "PTS_2_Pkt";
BA_ "FlexKomSigStartPos" SG_ 608 RR_PTS_StopControlSts 7;
BA_ "FlexKomSigStartValue" SG_ 608 RR_PTS_StopControlSts "FF001400000000FFh";
BA_ "GenSigCycleTime" SG_ 608 RR_PTS_StopControlSts 500;
BA_ "GenSigSendType" SG_ 608 RR_PTS_StopControlSts 5;
BA_ "GenSigSNA" SG_ 608 RR_PTS_StopControlSts "0h";
BA_ "RID" SG_ 608 RR_PTS_StopControlSts "2054";
BA_ "FlexKomComment" SG_ 608 RR_PTS_StopControlStsTeen "PTS 2 message packet";
BA_ "FlexKomIsMotorola" SG_ 608 RR_PTS_StopControlStsTeen 1;
BA_ "FlexKomSID" SG_ 608 RR_PTS_StopControlStsTeen 1954;
BA_ "FlexKomSigLaenge" SG_ 608 RR_PTS_StopControlStsTeen 64;
BA_ "FlexKomSigName" SG_ 608 RR_PTS_StopControlStsTeen "PTS_2_Pkt";
BA_ "FlexKomSigStartPos" SG_ 608 RR_PTS_StopControlStsTeen 7;
BA_ "FlexKomSigStartValue" SG_ 608 RR_PTS_StopControlStsTeen "FF001400000000FFh";
BA_ "GenSigCycleTime" SG_ 608 RR_PTS_StopControlStsTeen 500;
BA_ "GenSigSendType" SG_ 608 RR_PTS_StopControlStsTeen 5;
BA_ "GenSigSNA" SG_ 608 RR_PTS_StopControlStsTeen "0h";
BA_ "RID" SG_ 608 RR_PTS_StopControlStsTeen "2167";
BA_ "FlexKomComment" SG_ 825 PTS_CHIME_REP_RATE "PTS chime status";
BA_ "FlexKomIsMotorola" SG_ 825 PTS_CHIME_REP_RATE 1;
BA_ "FlexKomSID" SG_ 825 PTS_CHIME_REP_RATE 1350;
BA_ "FlexKomSigLaenge" SG_ 825 PTS_CHIME_REP_RATE 16;
BA_ "FlexKomSigName" SG_ 825 PTS_CHIME_REP_RATE "PTS_CHIME_STAT";
BA_ "FlexKomSigStartPos" SG_ 825 PTS_CHIME_REP_RATE 7;
BA_ "FlexKomSigStartValue" SG_ 825 PTS_CHIME_REP_RATE "0050h";
BA_ "GenSigCycleTime" SG_ 825 PTS_CHIME_REP_RATE 500;
BA_ "GenSigSendType" SG_ 825 PTS_CHIME_REP_RATE 5;
BA_ "GenSigSNA" SG_ 825 PTS_CHIME_REP_RATE "0h";
BA_ "RID" SG_ 825 PTS_CHIME_REP_RATE "1140";
BA_ "FlexKomComment" SG_ 825 PTS_CHIME_TYPE "PTS chime status";
BA_ "FlexKomIsMotorola" SG_ 825 PTS_CHIME_TYPE 1;
BA_ "FlexKomSID" SG_ 825 PTS_CHIME_TYPE 1350;
BA_ "FlexKomSigLaenge" SG_ 825 PTS_CHIME_TYPE 16;
BA_ "FlexKomSigName" SG_ 825 PTS_CHIME_TYPE "PTS_CHIME_STAT";
BA_ "FlexKomSigStartPos" SG_ 825 PTS_CHIME_TYPE 7;
BA_ "FlexKomSigStartValue" SG_ 825 PTS_CHIME_TYPE "0050h";
BA_ "GenSigCycleTime" SG_ 825 PTS_CHIME_TYPE 500;
BA_ "GenSigSendType" SG_ 825 PTS_CHIME_TYPE 5;
BA_ "GenSigSNA" SG_ 825 PTS_CHIME_TYPE "Fh";
BA_ "GenSigTimeout_CBC" SG_ 825 PTS_CHIME_TYPE 5250;
BA_ "RID" SG_ 825 PTS_CHIME_TYPE "1190";
BA_ "FlexKomComment" SG_ 825 PTS_FT_VOL "PTS chime status";
BA_ "FlexKomIsMotorola" SG_ 825 PTS_FT_VOL 1;
BA_ "FlexKomSID" SG_ 825 PTS_FT_VOL 1350;
BA_ "FlexKomSigLaenge" SG_ 825 PTS_FT_VOL 16;
BA_ "FlexKomSigName" SG_ 825 PTS_FT_VOL "PTS_CHIME_STAT";
BA_ "FlexKomSigStartPos" SG_ 825 PTS_FT_VOL 7;
BA_ "FlexKomSigStartValue" SG_ 825 PTS_FT_VOL "0050h";
BA_ "GenSigCycleTime" SG_ 825 PTS_FT_VOL 500;
BA_ "GenSigSendType" SG_ 825 PTS_FT_VOL 5;
BA_ "GenSigSNA" SG_ 825 PTS_FT_VOL "3h";
BA_ "GenSigStartValue" SG_ 825 PTS_FT_VOL 1;
BA_ "GenSigTimeout_CBC" SG_ 825 PTS_FT_VOL 5250;
BA_ "GenSigTimeout_IC" SG_ 825 PTS_FT_VOL 5250;
BA_ "RID" SG_ 825 PTS_FT_VOL "1886";
BA_ "FlexKomComment" SG_ 825 PTS_LF_CHIME_RQ "PTS chime status";
BA_ "FlexKomIsMotorola" SG_ 825 PTS_LF_CHIME_RQ 1;
BA_ "FlexKomSID" SG_ 825 PTS_LF_CHIME_RQ 1350;
BA_ "FlexKomSigLaenge" SG_ 825 PTS_LF_CHIME_RQ 16;
BA_ "FlexKomSigName" SG_ 825 PTS_LF_CHIME_RQ "PTS_CHIME_STAT";
BA_ "FlexKomSigStartPos" SG_ 825 PTS_LF_CHIME_RQ 7;
BA_ "FlexKomSigStartValue" SG_ 825 PTS_LF_CHIME_RQ "0050h";
BA_ "GenSigCycleTime" SG_ 825 PTS_LF_CHIME_RQ 500;
BA_ "GenSigSendType" SG_ 825 PTS_LF_CHIME_RQ 5;
BA_ "GenSigSNA" SG_ 825 PTS_LF_CHIME_RQ "0h";
BA_ "RID" SG_ 825 PTS_LF_CHIME_RQ "1083";
BA_ "FlexKomComment" SG_ 825 PTS_LR_CHIME_RQ "PTS chime status";
BA_ "FlexKomIsMotorola" SG_ 825 PTS_LR_CHIME_RQ 1;
BA_ "FlexKomSID" SG_ 825 PTS_LR_CHIME_RQ 1350;
BA_ "FlexKomSigLaenge" SG_ 825 PTS_LR_CHIME_RQ 16;
BA_ "FlexKomSigName" SG_ 825 PTS_LR_CHIME_RQ "PTS_CHIME_STAT";
BA_ "FlexKomSigStartPos" SG_ 825 PTS_LR_CHIME_RQ 7;
BA_ "FlexKomSigStartValue" SG_ 825 PTS_LR_CHIME_RQ "0050h";
BA_ "GenSigCycleTime" SG_ 825 PTS_LR_CHIME_RQ 500;
BA_ "GenSigSendType" SG_ 825 PTS_LR_CHIME_RQ 5;
BA_ "GenSigSNA" SG_ 825 PTS_LR_CHIME_RQ "0h";
BA_ "RID" SG_ 825 PTS_LR_CHIME_RQ "1054";
BA_ "FlexKomComment" SG_ 825 PTS_RF_CHIME_RQ "PTS chime status";
BA_ "FlexKomIsMotorola" SG_ 825 PTS_RF_CHIME_RQ 1;
BA_ "FlexKomSID" SG_ 825 PTS_RF_CHIME_RQ 1350;
BA_ "FlexKomSigLaenge" SG_ 825 PTS_RF_CHIME_RQ 16;
BA_ "FlexKomSigName" SG_ 825 PTS_RF_CHIME_RQ "PTS_CHIME_STAT";
BA_ "FlexKomSigStartPos" SG_ 825 PTS_RF_CHIME_RQ 7;
BA_ "FlexKomSigStartValue" SG_ 825 PTS_RF_CHIME_RQ "0050h";
BA_ "GenSigCycleTime" SG_ 825 PTS_RF_CHIME_RQ 500;
BA_ "GenSigSendType" SG_ 825 PTS_RF_CHIME_RQ 5;
BA_ "GenSigSNA" SG_ 825 PTS_RF_CHIME_RQ "0h";
BA_ "RID" SG_ 825 PTS_RF_CHIME_RQ "1240";
BA_ "FlexKomComment" SG_ 825 PTS_RR_CHIME_RQ "PTS chime status";
BA_ "FlexKomIsMotorola" SG_ 825 PTS_RR_CHIME_RQ 1;
BA_ "FlexKomSID" SG_ 825 PTS_RR_CHIME_RQ 1350;
BA_ "FlexKomSigLaenge" SG_ 825 PTS_RR_CHIME_RQ 16;
BA_ "FlexKomSigName" SG_ 825 PTS_RR_CHIME_RQ "PTS_CHIME_STAT";
BA_ "FlexKomSigStartPos" SG_ 825 PTS_RR_CHIME_RQ 7;
BA_ "FlexKomSigStartValue" SG_ 825 PTS_RR_CHIME_RQ "0050h";
BA_ "GenSigCycleTime" SG_ 825 PTS_RR_CHIME_RQ 500;
BA_ "GenSigSendType" SG_ 825 PTS_RR_CHIME_RQ 5;
BA_ "GenSigSNA" SG_ 825 PTS_RR_CHIME_RQ "0h";
BA_ "RID" SG_ 825 PTS_RR_CHIME_RQ "1090";
BA_ "FlexKomComment" SG_ 825 PTS_RR_VOL "PTS chime status";
BA_ "FlexKomIsMotorola" SG_ 825 PTS_RR_VOL 1;
BA_ "FlexKomSID" SG_ 825 PTS_RR_VOL 1350;
BA_ "FlexKomSigLaenge" SG_ 825 PTS_RR_VOL 16;
BA_ "FlexKomSigName" SG_ 825 PTS_RR_VOL "PTS_CHIME_STAT";
BA_ "FlexKomSigStartPos" SG_ 825 PTS_RR_VOL 7;
BA_ "FlexKomSigStartValue" SG_ 825 PTS_RR_VOL "0050h";
BA_ "GenSigCycleTime" SG_ 825 PTS_RR_VOL 500;
BA_ "GenSigSendType" SG_ 825 PTS_RR_VOL 5;
BA_ "GenSigSNA" SG_ 825 PTS_RR_VOL "3h";
BA_ "GenSigStartValue" SG_ 825 PTS_RR_VOL 1;
BA_ "GenSigTimeout_CBC" SG_ 825 PTS_RR_VOL 5250;
BA_ "GenSigTimeout_IC" SG_ 825 PTS_RR_VOL 5250;
BA_ "RID" SG_ 825 PTS_RR_VOL "1891";
BA_ "FlexKomComment" SG_ 671 CRC_29Fh "PTS steering control packet";
BA_ "FlexKomIsMotorola" SG_ 671 CRC_29Fh 1;
BA_ "FlexKomSID" SG_ 671 CRC_29Fh 1907;
BA_ "FlexKomSigLaenge" SG_ 671 CRC_29Fh 64;
BA_ "FlexKomSigName" SG_ 671 CRC_29Fh "PTS_StrCtrl";
BA_ "FlexKomSigStartPos" SG_ 671 CRC_29Fh 7;
BA_ "FlexKomSigStartValue" SG_ 671 CRC_29Fh "04000000000000FFh";
BA_ "GenSigCycleTime" SG_ 671 CRC_29Fh 20;
BA_ "GenSigSNA" SG_ 671 CRC_29Fh "FFh";
BA_ "GenSigStartValue" SG_ 671 CRC_29Fh 255;
BA_ "FlexKomComment" SG_ 671 MC_29Fh "PTS steering control packet";
BA_ "FlexKomIsMotorola" SG_ 671 MC_29Fh 1;
BA_ "FlexKomSID" SG_ 671 MC_29Fh 1907;
BA_ "FlexKomSigLaenge" SG_ 671 MC_29Fh 64;
BA_ "FlexKomSigName" SG_ 671 MC_29Fh "PTS_StrCtrl";
BA_ "FlexKomSigStartPos" SG_ 671 MC_29Fh 7;
BA_ "FlexKomSigStartValue" SG_ 671 MC_29Fh "04000000000000FFh";
BA_ "GenSigCycleTime" SG_ 671 MC_29Fh 20;
BA_ "GenSigSNA" SG_ 671 MC_29Fh "0h";
BA_ "FlexKomComment" SG_ 671 ManeuverPhase "PTS steering control packet";
BA_ "FlexKomIsMotorola" SG_ 671 ManeuverPhase 1;
BA_ "FlexKomSID" SG_ 671 ManeuverPhase 1907;
BA_ "FlexKomSigLaenge" SG_ 671 ManeuverPhase 64;
BA_ "FlexKomSigName" SG_ 671 ManeuverPhase "PTS_StrCtrl";
BA_ "FlexKomSigStartPos" SG_ 671 ManeuverPhase 7;
BA_ "FlexKomSigStartValue" SG_ 671 ManeuverPhase "04000000000000FFh";
BA_ "GenSigCycleTime" SG_ 671 ManeuverPhase 20;
BA_ "GenSigSNA" SG_ 671 ManeuverPhase "0h";
BA_ "FlexKomComment" SG_ 671 PTSDriveStyleReqSts "PTS steering control packet";
BA_ "FlexKomIsMotorola" SG_ 671 PTSDriveStyleReqSts 1;
BA_ "FlexKomSID" SG_ 671 PTSDriveStyleReqSts 1907;
BA_ "FlexKomSigLaenge" SG_ 671 PTSDriveStyleReqSts 64;
BA_ "FlexKomSigName" SG_ 671 PTSDriveStyleReqSts "PTS_StrCtrl";
BA_ "FlexKomSigStartPos" SG_ 671 PTSDriveStyleReqSts 7;
BA_ "FlexKomSigStartValue" SG_ 671 PTSDriveStyleReqSts "04000000000000FFh";
BA_ "GenSigCycleTime" SG_ 671 PTSDriveStyleReqSts 20;
BA_ "GenSigSNA" SG_ 671 PTSDriveStyleReqSts "0h";
BA_ "FlexKomComment" SG_ 671 PTSSystemFault "PTS steering control packet";
BA_ "FlexKomIsMotorola" SG_ 671 PTSSystemFault 1;
BA_ "FlexKomSID" SG_ 671 PTSSystemFault 1907;
BA_ "FlexKomSigLaenge" SG_ 671 PTSSystemFault 64;
BA_ "FlexKomSigName" SG_ 671 PTSSystemFault "PTS_StrCtrl";
BA_ "FlexKomSigStartPos" SG_ 671 PTSSystemFault 7;
BA_ "FlexKomSigStartValue" SG_ 671 PTSSystemFault "04000000000000FFh";
BA_ "GenSigCycleTime" SG_ 671 PTSSystemFault 20;
BA_ "GenSigSNA" SG_ 671 PTSSystemFault "0h";
BA_ "GenSigTimeout_IC" SG_ 671 PTSSystemFault 210;
BA_ "FlexKomComment" SG_ 671 PTS_ManoeuvreMode "PTS steering control packet";
BA_ "FlexKomIsMotorola" SG_ 671 PTS_ManoeuvreMode 1;
BA_ "FlexKomSID" SG_ 671 PTS_ManoeuvreMode 1907;
BA_ "FlexKomSigLaenge" SG_ 671 PTS_ManoeuvreMode 64;
BA_ "FlexKomSigName" SG_ 671 PTS_ManoeuvreMode "PTS_StrCtrl";
BA_ "FlexKomSigStartPos" SG_ 671 PTS_ManoeuvreMode 7;
BA_ "FlexKomSigStartValue" SG_ 671 PTS_ManoeuvreMode "04000000000000FFh";
BA_ "GenSigCycleTime" SG_ 671 PTS_ManoeuvreMode 20;
BA_ "GenSigSNA" SG_ 671 PTS_ManoeuvreMode "7h";
BA_ "GenSigTimeout_IC" SG_ 671 PTS_ManoeuvreMode 210;
BA_ "FlexKomComment" SG_ 671 TorqueOverlayIntActivation "PTS steering control packet";
BA_ "FlexKomIsMotorola" SG_ 671 TorqueOverlayIntActivation 1;
BA_ "FlexKomSID" SG_ 671 TorqueOverlayIntActivation 1907;
BA_ "FlexKomSigLaenge" SG_ 671 TorqueOverlayIntActivation 64;
BA_ "FlexKomSigName" SG_ 671 TorqueOverlayIntActivation "PTS_StrCtrl";
BA_ "FlexKomSigStartPos" SG_ 671 TorqueOverlayIntActivation 7;
BA_ "FlexKomSigStartValue" SG_ 671 TorqueOverlayIntActivation "04000000000000FFh";
BA_ "GenSigCycleTime" SG_ 671 TorqueOverlayIntActivation 20;
BA_ "GenSigSNA" SG_ 671 TorqueOverlayIntActivation "0h";
BA_ "FlexKomComment" SG_ 671 TorqueOverlaySteeringReq "PTS steering control packet";
BA_ "FlexKomIsMotorola" SG_ 671 TorqueOverlaySteeringReq 1;
BA_ "FlexKomSID" SG_ 671 TorqueOverlaySteeringReq 1907;
BA_ "FlexKomSigLaenge" SG_ 671 TorqueOverlaySteeringReq 64;
BA_ "FlexKomSigName" SG_ 671 TorqueOverlaySteeringReq "PTS_StrCtrl";
BA_ "FlexKomSigStartPos" SG_ 671 TorqueOverlaySteeringReq 7;
BA_ "FlexKomSigStartValue" SG_ 671 TorqueOverlaySteeringReq "04000000000000FFh";
BA_ "GenSigCycleTime" SG_ 671 TorqueOverlaySteeringReq 20;
BA_ "GenSigSNA" SG_ 671 TorqueOverlaySteeringReq "400h";
BA_ "GenSigStartValue" SG_ 671 TorqueOverlaySteeringReq 1024;
BA_ "FlexKomComment" SG_ 571 ACC_DistSwDec "Cruise Control Lever Status";
BA_ "FlexKomIsMotorola" SG_ 571 ACC_DistSwDec 1;
BA_ "FlexKomSID" SG_ 571 ACC_DistSwDec 1848;
BA_ "FlexKomSigLaenge" SG_ 571 ACC_DistSwDec 24;
BA_ "FlexKomSigName" SG_ 571 ACC_DistSwDec "CrsCtrlLvrSts";
BA_ "FlexKomSigStartPos" SG_ 571 ACC_DistSwDec 7;
BA_ "FlexKomSigStartValue" SG_ 571 ACC_DistSwDec "0000FFh";
BA_ "GenSigSendType" SG_ 571 ACC_DistSwDec 1;
BA_ "GenSigSNA" SG_ 571 ACC_DistSwDec "0h";
BA_ "FlexKomComment" SG_ 571 ACC_DistSwInc "Cruise Control Lever Status";
BA_ "FlexKomIsMotorola" SG_ 571 ACC_DistSwInc 1;
BA_ "FlexKomSID" SG_ 571 ACC_DistSwInc 1848;
BA_ "FlexKomSigLaenge" SG_ 571 ACC_DistSwInc 24;
BA_ "FlexKomSigName" SG_ 571 ACC_DistSwInc "CrsCtrlLvrSts";
BA_ "FlexKomSigStartPos" SG_ 571 ACC_DistSwInc 7;
BA_ "FlexKomSigStartValue" SG_ 571 ACC_DistSwInc "0000FFh";
BA_ "GenSigSendType" SG_ 571 ACC_DistSwInc 1;
BA_ "GenSigSNA" SG_ 571 ACC_DistSwInc "0h";
BA_ "FlexKomComment" SG_ 571 ACC_On "Cruise Control Lever Status";
BA_ "FlexKomIsMotorola" SG_ 571 ACC_On 1;
BA_ "FlexKomSID" SG_ 571 ACC_On 1848;
BA_ "FlexKomSigLaenge" SG_ 571 ACC_On 24;
BA_ "FlexKomSigName" SG_ 571 ACC_On "CrsCtrlLvrSts";
BA_ "FlexKomSigStartPos" SG_ 571 ACC_On 7;
BA_ "FlexKomSigStartValue" SG_ 571 ACC_On "0000FFh";
BA_ "GenSigSendType" SG_ 571 ACC_On 1;
BA_ "GenSigSNA" SG_ 571 ACC_On "0h";
BA_ "FlexKomComment" SG_ 571 AcceleratorSts "Cruise Control Lever Status";
BA_ "FlexKomIsMotorola" SG_ 571 AcceleratorSts 1;
BA_ "FlexKomSID" SG_ 571 AcceleratorSts 1848;
BA_ "FlexKomSigLaenge" SG_ 571 AcceleratorSts 24;
BA_ "FlexKomSigName" SG_ 571 AcceleratorSts "CrsCtrlLvrSts";
BA_ "FlexKomSigStartPos" SG_ 571 AcceleratorSts 7;
BA_ "FlexKomSigStartValue" SG_ 571 AcceleratorSts "0000FFh";
BA_ "GenSigSendType" SG_ 571 AcceleratorSts 1;
BA_ "GenSigSNA" SG_ 571 AcceleratorSts "0h";
BA_ "FlexKomComment" SG_ 571 CRC_CSWC_1 "Cruise Control Lever Status";
BA_ "FlexKomIsMotorola" SG_ 571 CRC_CSWC_1 1;
BA_ "FlexKomSID" SG_ 571 CRC_CSWC_1 1848;
BA_ "FlexKomSigLaenge" SG_ 571 CRC_CSWC_1 24;
BA_ "FlexKomSigName" SG_ 571 CRC_CSWC_1 "CrsCtrlLvrSts";
BA_ "FlexKomSigStartPos" SG_ 571 CRC_CSWC_1 7;
BA_ "FlexKomSigStartValue" SG_ 571 CRC_CSWC_1 "0000FFh";
BA_ "GenSigSendType" SG_ 571 CRC_CSWC_1 1;
BA_ "GenSigSNA" SG_ 571 CRC_CSWC_1 "FFh";
BA_ "GenSigStartValue" SG_ 571 CRC_CSWC_1 255;
BA_ "FlexKomComment" SG_ 571 CruiseControlFailSts "Cruise Control Lever Status";
BA_ "FlexKomIsMotorola" SG_ 571 CruiseControlFailSts 1;
BA_ "FlexKomSID" SG_ 571 CruiseControlFailSts 1848;
BA_ "FlexKomSigLaenge" SG_ 571 CruiseControlFailSts 24;
BA_ "FlexKomSigName" SG_ 571 CruiseControlFailSts "CrsCtrlLvrSts";
BA_ "FlexKomSigStartPos" SG_ 571 CruiseControlFailSts 7;
BA_ "FlexKomSigStartValue" SG_ 571 CruiseControlFailSts "0000FFh";
BA_ "GenSigSendType" SG_ 571 CruiseControlFailSts 1;
BA_ "GenSigSNA" SG_ 571 CruiseControlFailSts "0h";
BA_ "FlexKomComment" SG_ 571 CruiseControlOnOffSts "Cruise Control Lever Status";
BA_ "FlexKomIsMotorola" SG_ 571 CruiseControlOnOffSts 1;
BA_ "FlexKomSID" SG_ 571 CruiseControlOnOffSts 1848;
BA_ "FlexKomSigLaenge" SG_ 571 CruiseControlOnOffSts 24;
BA_ "FlexKomSigName" SG_ 571 CruiseControlOnOffSts "CrsCtrlLvrSts";
BA_ "FlexKomSigStartPos" SG_ 571 CruiseControlOnOffSts 7;
BA_ "FlexKomSigStartValue" SG_ 571 CruiseControlOnOffSts "0000FFh";
BA_ "GenSigSendType" SG_ 571 CruiseControlOnOffSts 1;
BA_ "GenSigSNA" SG_ 571 CruiseControlOnOffSts "0h";
BA_ "FlexKomComment" SG_ 571 CrusCnclSwitch "Cruise Control Lever Status";
BA_ "FlexKomIsMotorola" SG_ 571 CrusCnclSwitch 1;
BA_ "FlexKomSID" SG_ 571 CrusCnclSwitch 1848;
BA_ "FlexKomSigLaenge" SG_ 571 CrusCnclSwitch 24;
BA_ "FlexKomSigName" SG_ 571 CrusCnclSwitch "CrsCtrlLvrSts";
BA_ "FlexKomSigStartPos" SG_ 571 CrusCnclSwitch 7;
BA_ "FlexKomSigStartValue" SG_ 571 CrusCnclSwitch "0000FFh";
BA_ "GenSigSendType" SG_ 571 CrusCnclSwitch 1;
BA_ "GenSigSNA" SG_ 571 CrusCnclSwitch "0h";
BA_ "FlexKomComment" SG_ 571 DeceleratorSts "Cruise Control Lever Status";
BA_ "FlexKomIsMotorola" SG_ 571 DeceleratorSts 1;
BA_ "FlexKomSID" SG_ 571 DeceleratorSts 1848;
BA_ "FlexKomSigLaenge" SG_ 571 DeceleratorSts 24;
BA_ "FlexKomSigName" SG_ 571 DeceleratorSts "CrsCtrlLvrSts";
BA_ "FlexKomSigStartPos" SG_ 571 DeceleratorSts 7;
BA_ "FlexKomSigStartValue" SG_ 571 DeceleratorSts "0000FFh";
BA_ "GenSigSendType" SG_ 571 DeceleratorSts 1;
BA_ "GenSigSNA" SG_ 571 DeceleratorSts "0h";
BA_ "FlexKomComment" SG_ 571 MC_CSWC_1 "Cruise Control Lever Status";
BA_ "FlexKomIsMotorola" SG_ 571 MC_CSWC_1 1;
BA_ "FlexKomSID" SG_ 571 MC_CSWC_1 1848;
BA_ "FlexKomSigLaenge" SG_ 571 MC_CSWC_1 24;
BA_ "FlexKomSigName" SG_ 571 MC_CSWC_1 "CrsCtrlLvrSts";
BA_ "FlexKomSigStartPos" SG_ 571 MC_CSWC_1 7;
BA_ "FlexKomSigStartValue" SG_ 571 MC_CSWC_1 "0000FFh";
BA_ "GenSigSendType" SG_ 571 MC_CSWC_1 1;
BA_ "GenSigSNA" SG_ 571 MC_CSWC_1 "0h";
BA_ "FlexKomComment" SG_ 571 ResumeSwitch "Cruise Control Lever Status";
BA_ "FlexKomIsMotorola" SG_ 571 ResumeSwitch 1;
BA_ "FlexKomSID" SG_ 571 ResumeSwitch 1848;
BA_ "FlexKomSigLaenge" SG_ 571 ResumeSwitch 24;
BA_ "FlexKomSigName" SG_ 571 ResumeSwitch "CrsCtrlLvrSts";
BA_ "FlexKomSigStartPos" SG_ 571 ResumeSwitch 7;
BA_ "FlexKomSigStartValue" SG_ 571 ResumeSwitch "0000FFh";
BA_ "GenSigSendType" SG_ 571 ResumeSwitch 1;
BA_ "GenSigSNA" SG_ 571 ResumeSwitch "0h";
VAL_ 996 NET_CFG_STAT_PT 0 "NA" 1 "PROGAMMED" 2 "REQUEST_DATA" 3 "SNA" ;
VAL_ 996 NetCfg_BSMO 0 "Not_Present" 1 "Present" ;
VAL_ 996 NetCfg_RHSC2 0 "Not_Present" 1 "Present" ;
VAL_ 1025 NM_Mode 252 "LHOM" 253 "RING" 254 "ALIVE" 255 "SNA" ;
VAL_ 1025 NM_Successor 255 "SNA" ;
VAL_ 1025 NM_Ud_Launch 4 "BROADCAST" 63 "SNA" ;
VAL_ 1025 NM_Ud_Srv 2 "WAKEUP_SA" 15 "AWAKE_BC" 255 "NO_USER_DATA" ;
VAL_ 1025 Nw_Id 0 "POWERTRAIN" 1 "BODY" 2 "AUDIO_TELE" 255 "SNA" ;
VAL_ 1025 WakeupCnt 255 "SNA" ;
VAL_ 1025 WakeupRsn_CBC 0 "NETWORK" 1 "CAN_C" 2 "CAN_I" 3 "LIN_ONE" 4 "LIN_TWO" 5 "LIN_THREE" 6 "DRV_AJAR" 7 "PSG_AJAR" 8 "L_R_AJAR" 9 "R_R_AJAR" 10 "TLG_AJAR" 11 "FG_AJAR" 12 "HOOD_AJAR" 13 "HRD_TOP_STEALTH" 14 "TK_FG_SW" 15 "DRV_LK_SW" 16 "PASS_LK_SW" 17 "HAZARD_SW" 18 "SS_SW" 19 "BRK_SW" 20 "HL_SW" 21 "PD_SW" 22 "CARGO_SW" 23 "CON_LAMP_LD" 24 "REFUEL" 25 "ELCM" 255 "SNA" ;
VAL_ 1083 NM_Mode 252 "LHOM" 253 "RING" 254 "ALIVE" 255 "SNA" ;
VAL_ 1083 NM_Successor 255 "SNA" ;
VAL_ 1083 NM_Ud_Launch 4 "BROADCAST" 63 "SNA" ;
VAL_ 1083 NM_Ud_Srv 2 "WAKEUP_SA" 15 "AWAKE_BC" 255 "NO_USER_DATA" ;
VAL_ 1083 Nw_Id 0 "POWERTRAIN" 1 "BODY" 2 "AUDIO_TELE" 255 "SNA" ;
VAL_ 1083 WakeupCnt 255 "SNA" ;
VAL_ 1083 WakeupRsn_EBCM 0 "NETWORK" 1 "BP" 255 "SNA" ;
VAL_ 1050 NM_Mode 252 "LHOM" 253 "RING" 254 "ALIVE" 255 "SNA" ;
VAL_ 1050 NM_Successor 255 "SNA" ;
VAL_ 1050 NM_Ud_Launch 4 "BROADCAST" 63 "SNA" ;
VAL_ 1050 NM_Ud_Srv 2 "WAKEUP_SA" 15 "AWAKE_BC" 255 "NO_USER_DATA" ;
VAL_ 1050 Nw_Id 0 "POWERTRAIN" 1 "BODY" 2 "AUDIO_TELE" 255 "SNA" ;
VAL_ 1050 WakeupCnt 255 "SNA" ;
VAL_ 1050 WakeupRsn_EPS 0 "NETWORK" 1 "IGN" 255 "SNA" ;
VAL_ 1031 NM_Mode 252 "LHOM" 253 "RING" 254 "ALIVE" 255 "SNA" ;
VAL_ 1031 NM_Successor 255 "SNA" ;
VAL_ 1031 NM_Ud_Launch 4 "BROADCAST" 63 "SNA" ;
VAL_ 1031 NM_Ud_Srv 2 "WAKEUP_SA" 15 "AWAKE_BC" 255 "NO_USER_DATA" ;
VAL_ 1031 Nw_Id 0 "POWERTRAIN" 1 "BODY" 2 "AUDIO_TELE" 255 "SNA" ;
VAL_ 1031 WakeupCnt 255 "SNA" ;
VAL_ 1031 WakeupRsn_ESC 0 "NETWORK" 1 "BP" 2 "VEH_SPD" 3 "RA_RECLAMP" 4 "T_RECLAMP" 5 "SWU" 6 "DIAG" 7 "IGN" 255 "SNA" ;
VAL_ 1032 NM_Mode 252 "LHOM" 253 "RING" 254 "ALIVE" 255 "SNA" ;
VAL_ 1032 NM_Successor 255 "SNA" ;
VAL_ 1032 NM_Ud_Launch 4 "BROADCAST" 63 "SNA" ;
VAL_ 1032 NM_Ud_Srv 2 "WAKEUP_SA" 15 "AWAKE_BC" 255 "NO_USER_DATA" ;
VAL_ 1032 Nw_Id 0 "POWERTRAIN" 1 "BODY" 2 "AUDIO_TELE" 255 "SNA" ;
VAL_ 1032 WakeupCnt 255 "SNA" ;
VAL_ 1032 WakeupRsn_ESL 0 "NETWORK" 255 "SNA" ;
VAL_ 1082 NM_Mode 252 "LHOM" 253 "RING" 254 "ALIVE" 255 "SNA" ;
VAL_ 1082 NM_Successor 255 "SNA" ;
VAL_ 1082 NM_Ud_Launch 4 "BROADCAST" 63 "SNA" ;
VAL_ 1082 NM_Ud_Srv 2 "WAKEUP_SA" 15 "AWAKE_BC" 255 "NO_USER_DATA" ;
VAL_ 1082 Nw_Id 0 "POWERTRAIN" 1 "BODY" 2 "AUDIO_TELE" 255 "SNA" ;
VAL_ 1082 WakeupCnt 255 "SNA" ;
VAL_ 1082 WakeupRsn_HCP 0 "NETWORK" 1 "CBC_WU" 2 "IGN_WU" 3 "OBCM_WU" 255 "SNA" ;
VAL_ 1026 NM_Mode 252 "LHOM" 253 "RING" 254 "ALIVE" 255 "SNA" ;
VAL_ 1026 NM_Successor 255 "SNA" ;
VAL_ 1026 NM_Ud_Launch 4 "BROADCAST" 63 "SNA" ;
VAL_ 1026 NM_Ud_Srv 2 "WAKEUP_SA" 15 "AWAKE_BC" 255 "NO_USER_DATA" ;
VAL_ 1026 Nw_Id 0 "POWERTRAIN" 1 "BODY" 2 "AUDIO_TELE" 255 "SNA" ;
VAL_ 1026 WakeupCnt 255 "SNA" ;
VAL_ 1026 WakeupRsn_IC 0 "NETWORK" 1 "IGN" 255 "SNA" ;
VAL_ 1024 NM_Mode 252 "LHOM" 253 "RING" 254 "ALIVE" 255 "SNA" ;
VAL_ 1024 NM_Successor 255 "SNA" ;
VAL_ 1024 NM_Ud_Launch 4 "BROADCAST" 63 "SNA" ;
VAL_ 1024 NM_Ud_Srv 2 "WAKEUP_SA" 15 "AWAKE_BC" 255 "NO_USER_DATA" ;
VAL_ 1024 Nw_Id 0 "POWERTRAIN" 1 "BODY" 2 "AUDIO_TELE" 255 "SNA" ;
VAL_ 1024 WakeupCnt 255 "SNA" ;
VAL_ 1024 WakeupRsn_RF_HUB 0 "NETWORK" 1 "SSB" 2 "AP1" 3 "AP2" 4 "AP3" 5 "AP4" 6 "AP5" 7 "RF_INPUT" 8 "RESET" 9 "TIMER" 10 "CLUTCH" 255 "SNA" ;
VAL_ 1059 NM_Mode 252 "LHOM" 253 "RING" 254 "ALIVE" 255 "SNA" ;
VAL_ 1059 NM_Successor 255 "SNA" ;
VAL_ 1059 NM_Ud_Launch 4 "BROADCAST" 63 "SNA" ;
VAL_ 1059 NM_Ud_Srv 2 "WAKEUP_SA" 15 "AWAKE_BC" 255 "NO_USER_DATA" ;
VAL_ 1059 Nw_Id 0 "POWERTRAIN" 1 "BODY" 2 "AUDIO_TELE" 255 "SNA" ;
VAL_ 1059 WakeupCnt 255 "SNA" ;
VAL_ 1059 WakeupRsn_SCCM 0 "NETWORK" 71 "TILT" 72 "FP_LVR" 73 "HRN_SW" 76 "STW_SW" 255 "SNA" ;
VAL_ 464 DRV_SEATBELT 0 "DRV_SEATBELT_OK" 1 "DRV_SEATBELT_NOK" 2 "SEATBELT_FAIL" 3 "SNA" ;
VAL_ 464 DrvSbltUnFltr 0 "BUCKLED" 1 "UNBUCKLED" 2 "LOW" 3 "HIGH" 7 "SNA" ;
VAL_ 464 PSG_ODS_STAT 0 "ODS_STAT_NOCC" 1 "ODS_STAT_OCC" 2 "ODS_FAULT" 3 "SNA" ;
VAL_ 464 PSG_SEATBELT 0 "PSG_SEATBELT_OK" 1 "PSG_SEATBELT_NOK" 2 "SEATBELT_FAIL" 3 "SNA" ;
VAL_ 464 SRS_IndLmp_Rq 0 "OFF" 1 "CONT" 2 "BLINK" 3 "SNA" ;
VAL_ 826 PTS_AlrFC 0 "PTS_ALR_NOD" 1 "ARC1" 2 "ARC2" 3 "ARC3" 4 "ARC4" 5 "ARC5" 6 "ARC6" 7 "ARC7" 8 "ARC8" 15 "SNA" ;
VAL_ 826 PTS_AlrFL 0 "PTS_ALR_NOD" 1 "ARC1" 2 "ARC2" 3 "ARC3" 4 "ARC4" 5 "ARC5" 6 "ARC6" 7 "ARC7" 8 "ARC8" 15 "SNA" ;
VAL_ 826 PTS_AlrFR 0 "PTS_ALR_NOD" 1 "ARC1" 2 "ARC2" 3 "ARC3" 4 "ARC4" 5 "ARC5" 6 "ARC6" 7 "ARC7" 8 "ARC8" 15 "SNA" ;
VAL_ 826 PTS_AlrRC 0 "PTS_ALR_NOD" 1 "ARC1" 2 "ARC2" 3 "ARC3" 4 "ARC4" 5 "ARC5" 6 "ARC6" 7 "ARC7" 8 "ARC8" 15 "SNA" ;
VAL_ 826 PTS_AlrRL 0 "PTS_ALR_NOD" 1 "ARC1" 2 "ARC2" 3 "ARC3" 4 "ARC4" 5 "ARC5" 6 "ARC6" 7 "ARC7" 8 "ARC8" 15 "SNA" ;
VAL_ 826 PTS_AlrRR 0 "PTS_ALR_NOD" 1 "ARC1" 2 "ARC2" 3 "ARC3" 4 "ARC4" 5 "ARC5" 6 "ARC6" 7 "ARC7" 8 "ARC8" 15 "SNA" ;
VAL_ 826 PTS_CFG_STAT 0 "OFF" 1 "SND" 2 "SND_DISP" 3 "SNA" ;
VAL_ 826 PTS_GraphicFC 0 "SLOW_FLS_RQ" 1 "FAST_FLS_RQ" 2 "CONT_FLS_RQ" 3 "None" ;
VAL_ 826 PTS_GraphicFL 0 "SLOW_FLS_RQ" 1 "FAST_FLS_RQ" 2 "CONT_FLS_RQ" 3 "None" ;
VAL_ 826 PTS_GraphicFR 0 "SLOW_FLS_RQ" 1 "FAST_FLS_RQ" 2 "CONT_FLS_RQ" 3 "None" ;
VAL_ 826 PTS_GraphicRC 0 "SLOW_FLS_RQ" 1 "FAST_FLS_RQ" 2 "CONT_FLS_RQ" 3 "None" ;
VAL_ 826 PTS_GraphicRL 0 "SLOW_FLS_RQ" 1 "FAST_FLS_RQ" 2 "CONT_FLS_RQ" 3 "None" ;
VAL_ 826 PTS_GraphicRR 0 "SLOW_FLS_RQ" 1 "FAST_FLS_RQ" 2 "CONT_FLS_RQ" 3 "None" ;
VAL_ 826 PTS_STAT 0 "OFF" 1 "CONT" 2 "BLINK" 3 "SNA" ;
VAL_ 608 PTS_CFG_STAT_TeenKey 0 "OFF" 1 "SND" 2 "SND_DISP" 3 "SNA" ;
VAL_ 608 PTS_FT_VOL_TeenKey 0 "LOW" 1 "MED" 2 "HIGH" 3 "SNA" ;
VAL_ 608 PTS_PopUpRqst 0 "TM0" 1 "TM1" 2 "TM2" 3 "TM3" 4 "TM4" 5 "TM5" 6 "TM6" 7 "TM7" 8 "TM8" 9 "TM9" 10 "TM10" 11 "TM11" 12 "TM12" 13 "TM13" 14 "TM14" 15 "TM15" 16 "TM16" 17 "TM17" 18 "TM18" 19 "TM19" 20 "TM20" 21 "TM21" 22 "TM22" 23 "TM23" 24 "TM24" 25 "TM25" 26 "TM26" 27 "TM27" 28 "TM28" 29 "TM29" 30 "TM30" 31 "TM31" 32 "TM32" 33 "TM33" 34 "TM34" 35 "TM35" 36 "TM36" 37 "TM37" 38 "TM38" 39 "TM39" 40 "TM40" 41 "TM41" 42 "TM42" 43 "TM43" 44 "TM44" 45 "TM45" 46 "TM46" 47 "TM47" 48 "TM48" 49 "TM49" 50 "TM50" 51 "TM51" 52 "TM52" 53 "TM53" 54 "TM54" 55 "TM55" 56 "TM56" 57 "TM57" 58 "TM58" 59 "TM59" 60 "TM60" 61 "TM61" 62 "TM62" 63 "TM63" 64 "TM64" 65 "TM65" 66 "TM66" 67 "TM67" 68 "TM68" 69 "TM69" 70 "TM70" 71 "TM71" 72 "TM72" 73 "TM73" 74 "TM74" 75 "TM75" 76 "TM76" 77 "TM77" 78 "TM78" 79 "TM79" 80 "TM80" 81 "TM81" 82 "TM82" 83 "TM83" 84 "TM84" 85 "TM85" 86 "TM86" 87 "TM87" 88 "TM88" 89 "TM89" 90 "TM90" 91 "TM91" 92 "TM92" 93 "TM93" 94 "TM94" 95 "TM95" 96 "TM96" 97 "TM97" 98 "TM98" 99 "TM99" 100 "TM100" 255 "SNA" ;
VAL_ 608 PTS_RR_VOL_TeenKey 0 "LOW" 1 "MED" 2 "HIGH" 3 "SNA" ;
VAL_ 608 RR_PTS_Dist 255 "SNA" ;
VAL_ 825 PTS_CHIME_TYPE 0 "NONE" 1 "TYP_1" 2 "TYP_2" 3 "TYP_3" 4 "TYP_4" 5 "TYP_5" 6 "TYP_6" 7 "TYP_7" 8 "TYP_8" 9 "TYP_9" 10 "TYP_10" 11 "TYP_11" 12 "TYP_12" 13 "TYP_13" 14 "TYP_14" 15 "SNA" ;
VAL_ 825 PTS_FT_VOL 0 "LOW" 1 "MED" 2 "HIGH" 3 "SNA" ;
VAL_ 825 PTS_RR_VOL 0 "LOW" 1 "MED" 2 "HIGH" 3 "SNA" ;
VAL_ 671 PTS_ManoeuvreMode 0 "None" 1 "PARA" 2 "PERP" 3 "PULL_OUT" 4 "OVER" 7 "SNA" ;
